VERSION ""

NS_ :

BS_:

BU_: VCU_LE CHUD_LE VKM_LE RCRM_LE VPM_LE EDI_LE V2V_LE TCP_LE CSM_LE UHP_Low_LE TouchPad_LE RSE_LE RSC_LE RSA_LE PDIM_LE OTIM_LE ICS_LE LVMPC_LE LVMNav_LE DVB_T_LE ONSTAR_LE HUD_LE IPC_LE RadioHead_LE CHM_LE Dummy_LE CGM_LE AMP_LE

BO_ 2158960640 ODIIndication_Centerstack_LE: 8 RadioHead_LE
 SG_ ODIIC_FUCID : 7|8@0+ (1,0) [0|255] ""  VCU_LE,IPC_LE,CHUD_LE,HUD_LE,RSC_LE,RSA_LE
 SG_ ODIIC_ODIInd9 : 23|1@0+ (1,0) [0|1] ""  VCU_LE,IPC_LE,CHUD_LE,HUD_LE,RSC_LE,RSA_LE
 SG_ ODIIC_ODIInd8 : 8|1@0+ (1,0) [0|1] ""  VCU_LE,IPC_LE,CHUD_LE,HUD_LE,RSC_LE,RSA_LE
 SG_ ODIIC_ODIInd7 : 9|1@0+ (1,0) [0|1] ""  VCU_LE,IPC_LE,CHUD_LE,HUD_LE,RSC_LE,RSA_LE
 SG_ ODIIC_ODIInd6 : 10|1@0+ (1,0) [0|1] ""  VCU_LE,IPC_LE,CHUD_LE,HUD_LE,RSC_LE,RSA_LE
 SG_ ODIIC_ODIInd56 : 56|1@0+ (1,0) [0|1] ""  VCU_LE,IPC_LE,CHUD_LE,HUD_LE,RSC_LE,RSA_LE
 SG_ ODIIC_ODIInd55 : 57|1@0+ (1,0) [0|1] ""  VCU_LE,IPC_LE,CHUD_LE,HUD_LE,RSC_LE,RSA_LE
 SG_ ODIIC_ODIInd54 : 58|1@0+ (1,0) [0|1] ""  VCU_LE,IPC_LE,CHUD_LE,HUD_LE,RSC_LE,RSA_LE
 SG_ ODIIC_ODIInd53 : 59|1@0+ (1,0) [0|1] ""  VCU_LE,IPC_LE,CHUD_LE,HUD_LE,RSC_LE,RSA_LE
 SG_ ODIIC_ODIInd52 : 60|1@0+ (1,0) [0|1] ""  VCU_LE,IPC_LE,CHUD_LE,HUD_LE,RSC_LE,RSA_LE
 SG_ ODIIC_ODIInd51 : 61|1@0+ (1,0) [0|1] ""  VCU_LE,IPC_LE,CHUD_LE,HUD_LE,RSC_LE,RSA_LE
 SG_ ODIIC_ODIInd50 : 62|1@0+ (1,0) [0|1] ""  VCU_LE,IPC_LE,CHUD_LE,HUD_LE,RSC_LE,RSA_LE
 SG_ ODIIC_ODIInd5 : 11|1@0+ (1,0) [0|1] ""  VCU_LE,IPC_LE,CHUD_LE,HUD_LE,RSC_LE,RSA_LE
 SG_ ODIIC_ODIInd49 : 63|1@0+ (1,0) [0|1] ""  VCU_LE,IPC_LE,CHUD_LE,HUD_LE,RSC_LE,RSA_LE
 SG_ ODIIC_ODIInd48 : 48|1@0+ (1,0) [0|1] ""  VCU_LE,IPC_LE,CHUD_LE,HUD_LE,RSC_LE,RSA_LE
 SG_ ODIIC_ODIInd47 : 49|1@0+ (1,0) [0|1] ""  VCU_LE,IPC_LE,CHUD_LE,HUD_LE,RSC_LE,RSA_LE
 SG_ ODIIC_ODIInd46 : 50|1@0+ (1,0) [0|1] ""  VCU_LE,IPC_LE,CHUD_LE,HUD_LE,RSC_LE,RSA_LE
 SG_ ODIIC_ODIInd45 : 51|1@0+ (1,0) [0|1] ""  VCU_LE,IPC_LE,CHUD_LE,HUD_LE,RSC_LE,RSA_LE
 SG_ ODIIC_ODIInd44 : 52|1@0+ (1,0) [0|1] ""  VCU_LE,IPC_LE,CHUD_LE,HUD_LE,RSC_LE,RSA_LE
 SG_ ODIIC_ODIInd43 : 53|1@0+ (1,0) [0|1] ""  VCU_LE,IPC_LE,CHUD_LE,HUD_LE,RSC_LE,RSA_LE
 SG_ ODIIC_ODIInd42 : 54|1@0+ (1,0) [0|1] ""  VCU_LE,IPC_LE,CHUD_LE,HUD_LE,RSC_LE,RSA_LE
 SG_ ODIIC_ODIInd41 : 55|1@0+ (1,0) [0|1] ""  VCU_LE,IPC_LE,CHUD_LE,HUD_LE,RSC_LE,RSA_LE
 SG_ ODIIC_ODIInd40 : 40|1@0+ (1,0) [0|1] ""  VCU_LE,IPC_LE,CHUD_LE,HUD_LE,RSC_LE,RSA_LE
 SG_ ODIIC_ODIInd4 : 12|1@0+ (1,0) [0|1] ""  VCU_LE,IPC_LE,CHUD_LE,HUD_LE,RSC_LE,RSA_LE
 SG_ ODIIC_ODIInd39 : 41|1@0+ (1,0) [0|1] ""  VCU_LE,IPC_LE,CHUD_LE,HUD_LE,RSC_LE,RSA_LE
 SG_ ODIIC_ODIInd38 : 42|1@0+ (1,0) [0|1] ""  VCU_LE,IPC_LE,CHUD_LE,HUD_LE,RSC_LE,RSA_LE
 SG_ ODIIC_ODIInd37 : 43|1@0+ (1,0) [0|1] ""  VCU_LE,IPC_LE,CHUD_LE,HUD_LE,RSC_LE,RSA_LE
 SG_ ODIIC_ODIInd36 : 44|1@0+ (1,0) [0|1] ""  VCU_LE,IPC_LE,CHUD_LE,HUD_LE,RSC_LE,RSA_LE
 SG_ ODIIC_ODIInd35 : 45|1@0+ (1,0) [0|1] ""  VCU_LE,IPC_LE,CHUD_LE,HUD_LE,RSC_LE,RSA_LE
 SG_ ODIIC_ODIInd34 : 46|1@0+ (1,0) [0|1] ""  VCU_LE,IPC_LE,CHUD_LE,HUD_LE,RSC_LE,RSA_LE
 SG_ ODIIC_ODIInd33 : 47|1@0+ (1,0) [0|1] ""  VCU_LE,IPC_LE,CHUD_LE,HUD_LE,RSC_LE,RSA_LE
 SG_ ODIIC_ODIInd32 : 32|1@0+ (1,0) [0|1] ""  VCU_LE,IPC_LE,CHUD_LE,HUD_LE,RSC_LE,RSA_LE
 SG_ ODIIC_ODIInd31 : 33|1@0+ (1,0) [0|1] ""  VCU_LE,IPC_LE,CHUD_LE,HUD_LE,RSC_LE,RSA_LE
 SG_ ODIIC_ODIInd30 : 34|1@0+ (1,0) [0|1] ""  VCU_LE,IPC_LE,CHUD_LE,HUD_LE,RSC_LE,RSA_LE
 SG_ ODIIC_ODIInd3 : 13|1@0+ (1,0) [0|1] ""  VCU_LE,IPC_LE,CHUD_LE,HUD_LE,RSC_LE,RSA_LE
 SG_ ODIIC_ODIInd29 : 35|1@0+ (1,0) [0|1] ""  VCU_LE,IPC_LE,CHUD_LE,HUD_LE,RSC_LE,RSA_LE
 SG_ ODIIC_ODIInd28 : 36|1@0+ (1,0) [0|1] ""  VCU_LE,IPC_LE,CHUD_LE,HUD_LE,RSC_LE,RSA_LE
 SG_ ODIIC_ODIInd27 : 37|1@0+ (1,0) [0|1] ""  VCU_LE,IPC_LE,CHUD_LE,HUD_LE,RSC_LE,RSA_LE
 SG_ ODIIC_ODIInd26 : 38|1@0+ (1,0) [0|1] ""  VCU_LE,IPC_LE,CHUD_LE,HUD_LE,RSC_LE,RSA_LE
 SG_ ODIIC_ODIInd25 : 39|1@0+ (1,0) [0|1] ""  VCU_LE,IPC_LE,CHUD_LE,HUD_LE,RSC_LE,RSA_LE
 SG_ ODIIC_ODIInd24 : 24|1@0+ (1,0) [0|1] ""  VCU_LE,IPC_LE,CHUD_LE,HUD_LE,RSC_LE,RSA_LE
 SG_ ODIIC_ODIInd23 : 25|1@0+ (1,0) [0|1] ""  VCU_LE,IPC_LE,CHUD_LE,HUD_LE,RSC_LE,RSA_LE
 SG_ ODIIC_ODIInd22 : 26|1@0+ (1,0) [0|1] ""  VCU_LE,IPC_LE,CHUD_LE,HUD_LE,RSC_LE,RSA_LE
 SG_ ODIIC_ODIInd21 : 27|1@0+ (1,0) [0|1] ""  VCU_LE,IPC_LE,CHUD_LE,HUD_LE,RSC_LE,RSA_LE
 SG_ ODIIC_ODIInd20 : 28|1@0+ (1,0) [0|1] ""  VCU_LE,IPC_LE,CHUD_LE,HUD_LE,RSC_LE,RSA_LE
 SG_ ODIIC_ODIInd2 : 14|1@0+ (1,0) [0|1] ""  VCU_LE,IPC_LE,CHUD_LE,HUD_LE,RSC_LE,RSA_LE
 SG_ ODIIC_ODIInd19 : 29|1@0+ (1,0) [0|1] ""  VCU_LE,IPC_LE,CHUD_LE,HUD_LE,RSC_LE,RSA_LE
 SG_ ODIIC_ODIInd18 : 30|1@0+ (1,0) [0|1] ""  VCU_LE,IPC_LE,CHUD_LE,HUD_LE,RSC_LE,RSA_LE
 SG_ ODIIC_ODIInd17 : 31|1@0+ (1,0) [0|1] ""  VCU_LE,IPC_LE,CHUD_LE,HUD_LE,RSC_LE,RSA_LE
 SG_ ODIIC_ODIInd16 : 16|1@0+ (1,0) [0|1] ""  VCU_LE,IPC_LE,CHUD_LE,HUD_LE,RSC_LE,RSA_LE
 SG_ ODIIC_ODIInd15 : 17|1@0+ (1,0) [0|1] ""  VCU_LE,IPC_LE,CHUD_LE,HUD_LE,RSC_LE,RSA_LE
 SG_ ODIIC_ODIInd14 : 18|1@0+ (1,0) [0|1] ""  VCU_LE,IPC_LE,CHUD_LE,HUD_LE,RSC_LE,RSA_LE
 SG_ ODIIC_ODIInd13 : 19|1@0+ (1,0) [0|1] ""  VCU_LE,IPC_LE,CHUD_LE,HUD_LE,RSC_LE,RSA_LE
 SG_ ODIIC_ODIInd12 : 20|1@0+ (1,0) [0|1] ""  VCU_LE,IPC_LE,CHUD_LE,HUD_LE,RSC_LE,RSA_LE
 SG_ ODIIC_ODIInd11 : 21|1@0+ (1,0) [0|1] ""  VCU_LE,IPC_LE,CHUD_LE,HUD_LE,RSC_LE,RSA_LE
 SG_ ODIIC_ODIInd10 : 22|1@0+ (1,0) [0|1] ""  VCU_LE,IPC_LE,CHUD_LE,HUD_LE,RSC_LE,RSA_LE
 SG_ ODIIC_ODIInd1 : 15|1@0+ (1,0) [0|1] ""  VCU_LE,IPC_LE,CHUD_LE,HUD_LE,RSC_LE,RSA_LE

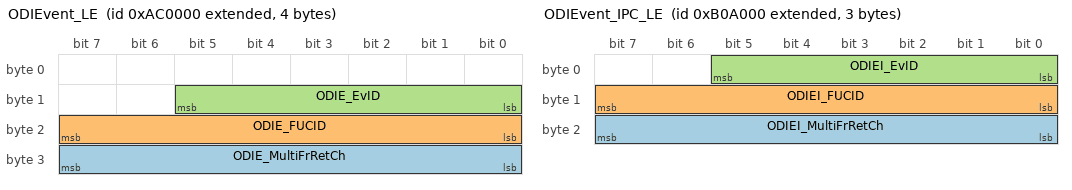
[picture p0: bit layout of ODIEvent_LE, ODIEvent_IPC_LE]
BO_ 2158755840 ODIEvent_LE: 4 ONSTAR_LE
 SG_ ODIE_MultiFrRetCh : 31|8@0+ (1,0) [0|255] ""  CSM_LE,OTIM_LE,RSC_LE,RSA_LE,RadioHead_LE,VCU_LE,IPC_LE,CHUD_LE,HUD_LE
 SG_ ODIE_FUCID : 23|8@0+ (1,0) [0|255] ""  CSM_LE,OTIM_LE,RSC_LE,RSA_LE,RadioHead_LE,VCU_LE,IPC_LE,CHUD_LE,HUD_LE
 SG_ ODIE_EvID : 13|6@0+ (1,0) [0|63] ""  CSM_LE,OTIM_LE,RSC_LE,RSA_LE,RadioHead_LE,VCU_LE,IPC_LE,CHUD_LE,HUD_LE

BO_ 2159058944 ODIEvent_IPC_LE: 3 IPC_LE
 SG_ ODIEI_MultiFrRetCh : 23|8@0+ (1,0) [0|255] ""  CSM_LE,VCU_LE,RadioHead_LE,CHUD_LE,HUD_LE
 SG_ ODIEI_FUCID : 15|8@0+ (1,0) [0|255] ""  CSM_LE,VCU_LE,RadioHead_LE,CHUD_LE,HUD_LE
 SG_ ODIEI_EvID : 5|6@0+ (1,0) [0|63] ""  CSM_LE,VCU_LE,RadioHead_LE,CHUD_LE,HUD_LE

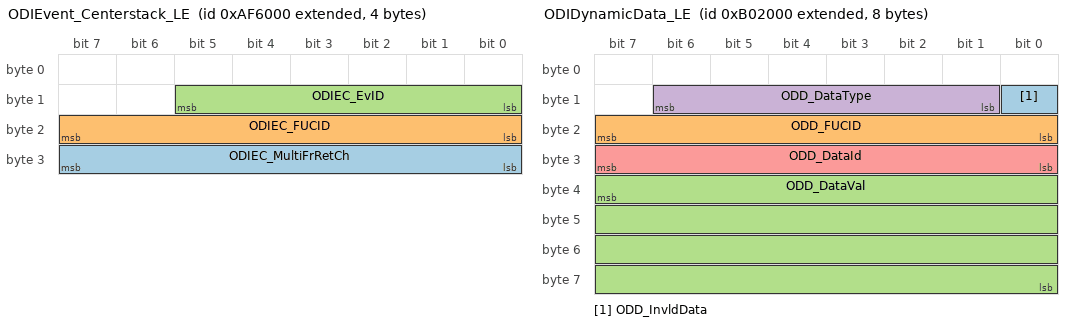
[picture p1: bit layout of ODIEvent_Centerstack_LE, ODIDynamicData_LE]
BO_ 2158977024 ODIEvent_Centerstack_LE: 4 RadioHead_LE
 SG_ ODIEC_MultiFrRetCh : 31|8@0+ (1,0) [0|255] ""  VCU_LE,IPC_LE,CHUD_LE,HUD_LE,RSC_LE,RSA_LE
 SG_ ODIEC_FUCID : 23|8@0+ (1,0) [0|255] ""  VCU_LE,IPC_LE,CHUD_LE,HUD_LE,RSC_LE,RSA_LE
 SG_ ODIEC_EvID : 13|6@0+ (1,0) [0|63] ""  VCU_LE,IPC_LE,CHUD_LE,HUD_LE,RSC_LE,RSA_LE

BO_ 2158936064 ODIEnumDynamicData_LE: 8 CGM_LE
 SG_ ODIEDD_Data18Value : 50|3@0+ (1,0) [0|7] ""  CSM_LE,TCP_LE,ONSTAR_LE,OTIM_LE,IPC_LE,CHUD_LE,HUD_LE,VCU_LE,RadioHead_LE
 SG_ ODIEDD_Data17Value : 53|3@0+ (1,0) [0|7] ""  CSM_LE,TCP_LE,ONSTAR_LE,OTIM_LE,IPC_LE,CHUD_LE,HUD_LE,VCU_LE,RadioHead_LE
 SG_ ODIEDD_Data16Value : 40|3@0+ (1,0) [0|7] ""  CSM_LE,TCP_LE,ONSTAR_LE,OTIM_LE,IPC_LE,CHUD_LE,HUD_LE,VCU_LE,RadioHead_LE
 SG_ ODIEDD_Data15Value : 43|3@0+ (1,0) [0|7] ""  CSM_LE,TCP_LE,ONSTAR_LE,OTIM_LE,IPC_LE,CHUD_LE,HUD_LE,VCU_LE,RadioHead_LE
 SG_ ODIEDD_Data14Value : 46|3@0+ (1,0) [0|7] ""  CSM_LE,TCP_LE,ONSTAR_LE,OTIM_LE,IPC_LE,CHUD_LE,HUD_LE,VCU_LE,RadioHead_LE
 SG_ ODIEDD_Data13Value : 33|3@0+ (1,0) [0|7] ""  CSM_LE,TCP_LE,ONSTAR_LE,OTIM_LE,IPC_LE,CHUD_LE,HUD_LE,VCU_LE,RadioHead_LE
 SG_ ODIEDD_Data12Value : 36|3@0+ (1,0) [0|7] ""  CSM_LE,TCP_LE,ONSTAR_LE,OTIM_LE,IPC_LE,CHUD_LE,HUD_LE,VCU_LE,RadioHead_LE
 SG_ ODIEDD_Data11Value : 39|3@0+ (1,0) [0|7] ""  CSM_LE,TCP_LE,ONSTAR_LE,OTIM_LE,IPC_LE,CHUD_LE,HUD_LE,VCU_LE,RadioHead_LE
 SG_ ODIEDD_Data10Value : 26|3@0+ (1,0) [0|7] ""  CSM_LE,TCP_LE,ONSTAR_LE,OTIM_LE,IPC_LE,CHUD_LE,HUD_LE,VCU_LE,RadioHead_LE
 SG_ ODIEDD_Data9Value : 29|3@0+ (1,0) [0|7] ""  CSM_LE,TCP_LE,ONSTAR_LE,OTIM_LE,IPC_LE,CHUD_LE,HUD_LE,VCU_LE,RadioHead_LE
 SG_ ODIEDD_Data8Value : 16|3@0+ (1,0) [0|7] ""  CSM_LE,TCP_LE,ONSTAR_LE,OTIM_LE,IPC_LE,CHUD_LE,HUD_LE,VCU_LE,RadioHead_LE
 SG_ ODIEDD_Data7Value : 19|3@0+ (1,0) [0|7] ""  CSM_LE,TCP_LE,ONSTAR_LE,OTIM_LE,IPC_LE,CHUD_LE,HUD_LE,VCU_LE,RadioHead_LE
 SG_ ODIEDD_Data6Value : 22|3@0+ (1,0) [0|7] ""  CSM_LE,TCP_LE,ONSTAR_LE,OTIM_LE,IPC_LE,CHUD_LE,HUD_LE,VCU_LE,RadioHead_LE
 SG_ ODIEDD_Data5Value : 9|3@0+ (1,0) [0|7] ""  CSM_LE,TCP_LE,ONSTAR_LE,OTIM_LE,IPC_LE,CHUD_LE,HUD_LE,VCU_LE,RadioHead_LE
 SG_ ODIEDD_Data4Value : 12|3@0+ (1,0) [0|7] ""  CSM_LE,TCP_LE,ONSTAR_LE,OTIM_LE,IPC_LE,CHUD_LE,HUD_LE,VCU_LE,RadioHead_LE
 SG_ ODIEDD_Data3Value : 15|3@0+ (1,0) [0|7] ""  CSM_LE,TCP_LE,ONSTAR_LE,OTIM_LE,IPC_LE,CHUD_LE,HUD_LE,VCU_LE,RadioHead_LE
 SG_ ODIEDD_Data2Value : 2|3@0+ (1,0) [0|7] ""  CSM_LE,TCP_LE,ONSTAR_LE,OTIM_LE,IPC_LE,CHUD_LE,HUD_LE,VCU_LE,RadioHead_LE
 SG_ ODIEDD_Data1Value : 5|3@0+ (1,0) [0|7] ""  CSM_LE,TCP_LE,ONSTAR_LE,OTIM_LE,IPC_LE,CHUD_LE,HUD_LE,VCU_LE,RadioHead_LE
 SG_ ODIEDD_FUCID : 63|8@0+ (1,0) [0|255] ""  CSM_LE,TCP_LE,ONSTAR_LE,OTIM_LE,IPC_LE,CHUD_LE,HUD_LE,VCU_LE,RadioHead_LE

BO_ 2159001600 ODIEnumDynamicData_IPC_LE: 8 IPC_LE
 SG_ ODIEDDIPC_FUCID : 63|8@0+ (1,0) [0|255] ""  CSM_LE,TCP_LE,ONSTAR_LE,CHUD_LE,HUD_LE,VCU_LE,RadioHead_LE
 SG_ ODIEDDIPC_Data18Value : 50|3@0+ (1,0) [0|7] ""  CSM_LE,TCP_LE,ONSTAR_LE,CHUD_LE,HUD_LE,VCU_LE,RadioHead_LE
 SG_ ODIEDDIPC_Data17Value : 53|3@0+ (1,0) [0|7] ""  CSM_LE,TCP_LE,ONSTAR_LE,CHUD_LE,HUD_LE,VCU_LE,RadioHead_LE
 SG_ ODIEDDIPC_Data16Value : 40|3@0+ (1,0) [0|7] ""  CSM_LE,TCP_LE,ONSTAR_LE,CHUD_LE,HUD_LE,VCU_LE,RadioHead_LE
 SG_ ODIEDDIPC_Data15Value : 43|3@0+ (1,0) [0|7] ""  CSM_LE,TCP_LE,ONSTAR_LE,CHUD_LE,HUD_LE,VCU_LE,RadioHead_LE
 SG_ ODIEDDIPC_Data14Value : 46|3@0+ (1,0) [0|7] ""  CSM_LE,TCP_LE,ONSTAR_LE,CHUD_LE,HUD_LE,VCU_LE,RadioHead_LE
 SG_ ODIEDDIPC_Data13Value : 33|3@0+ (1,0) [0|7] ""  CSM_LE,TCP_LE,ONSTAR_LE,CHUD_LE,HUD_LE,VCU_LE,RadioHead_LE
 SG_ ODIEDDIPC_Data12Value : 36|3@0+ (1,0) [0|7] ""  CSM_LE,TCP_LE,ONSTAR_LE,CHUD_LE,HUD_LE,VCU_LE,RadioHead_LE
 SG_ ODIEDDIPC_Data11Value : 39|3@0+ (1,0) [0|7] ""  CSM_LE,TCP_LE,ONSTAR_LE,CHUD_LE,HUD_LE,VCU_LE,RadioHead_LE
 SG_ ODIEDDIPC_Data10Value : 26|3@0+ (1,0) [0|7] ""  CSM_LE,TCP_LE,ONSTAR_LE,CHUD_LE,HUD_LE,VCU_LE,RadioHead_LE
 SG_ ODIEDDIPC_Data9Value : 29|3@0+ (1,0) [0|7] ""  CSM_LE,TCP_LE,ONSTAR_LE,CHUD_LE,HUD_LE,VCU_LE,RadioHead_LE
 SG_ ODIEDDIPC_Data8Value : 16|3@0+ (1,0) [0|7] ""  CSM_LE,TCP_LE,ONSTAR_LE,CHUD_LE,HUD_LE,VCU_LE,RadioHead_LE
 SG_ ODIEDDIPC_Data7Value : 19|3@0+ (1,0) [0|7] ""  CSM_LE,TCP_LE,ONSTAR_LE,CHUD_LE,HUD_LE,VCU_LE,RadioHead_LE
 SG_ ODIEDDIPC_Data6Value : 22|3@0+ (1,0) [0|7] ""  CSM_LE,TCP_LE,ONSTAR_LE,CHUD_LE,HUD_LE,VCU_LE,RadioHead_LE
 SG_ ODIEDDIPC_Data5Value : 9|3@0+ (1,0) [0|7] ""  CSM_LE,TCP_LE,ONSTAR_LE,CHUD_LE,HUD_LE,VCU_LE,RadioHead_LE
 SG_ ODIEDDIPC_Data4Value : 12|3@0+ (1,0) [0|7] ""  CSM_LE,TCP_LE,ONSTAR_LE,CHUD_LE,HUD_LE,VCU_LE,RadioHead_LE
 SG_ ODIEDDIPC_Data3Value : 15|3@0+ (1,0) [0|7] ""  CSM_LE,TCP_LE,ONSTAR_LE,CHUD_LE,HUD_LE,VCU_LE,RadioHead_LE
 SG_ ODIEDDIPC_Data2Value : 2|3@0+ (1,0) [0|7] ""  CSM_LE,TCP_LE,ONSTAR_LE,CHUD_LE,HUD_LE,VCU_LE,RadioHead_LE
 SG_ ODIEDDIPC_Data1Value : 5|3@0+ (1,0) [0|7] ""  CSM_LE,TCP_LE,ONSTAR_LE,CHUD_LE,HUD_LE,VCU_LE,RadioHead_LE

BO_ 2158993408 ODIEnumDynamicData_CntrStack_LE: 8 RadioHead_LE
 SG_ ODIEDDCS_FUCID : 63|8@0+ (1,0) [0|255] ""  VCU_LE,IPC_LE,CHUD_LE,HUD_LE
 SG_ ODIEDDCS_Data9Value : 29|3@0+ (1,0) [0|7] ""  VCU_LE,IPC_LE,CHUD_LE,HUD_LE
 SG_ ODIEDDCS_Data8Value : 16|3@0+ (1,0) [0|7] ""  VCU_LE,IPC_LE,CHUD_LE,HUD_LE
 SG_ ODIEDDCS_Data7Value : 19|3@0+ (1,0) [0|7] ""  VCU_LE,IPC_LE,CHUD_LE,HUD_LE
 SG_ ODIEDDCS_Data6Value : 22|3@0+ (1,0) [0|7] ""  VCU_LE,IPC_LE,CHUD_LE,HUD_LE
 SG_ ODIEDDCS_Data5Value : 9|3@0+ (1,0) [0|7] ""  VCU_LE,IPC_LE,CHUD_LE,HUD_LE
 SG_ ODIEDDCS_Data4Value : 12|3@0+ (1,0) [0|7] ""  VCU_LE,IPC_LE,CHUD_LE,HUD_LE
 SG_ ODIEDDCS_Data3Value : 15|3@0+ (1,0) [0|7] ""  VCU_LE,IPC_LE,CHUD_LE,HUD_LE
 SG_ ODIEDDCS_Data2Value : 2|3@0+ (1,0) [0|7] ""  VCU_LE,IPC_LE,CHUD_LE,HUD_LE
 SG_ ODIEDDCS_Data18Value : 50|3@0+ (1,0) [0|7] ""  VCU_LE,IPC_LE,CHUD_LE,HUD_LE
 SG_ ODIEDDCS_Data17Value : 53|3@0+ (1,0) [0|7] ""  VCU_LE,IPC_LE,CHUD_LE,HUD_LE
 SG_ ODIEDDCS_Data16Value : 40|3@0+ (1,0) [0|7] ""  VCU_LE,IPC_LE,CHUD_LE,HUD_LE
 SG_ ODIEDDCS_Data15Value : 43|3@0+ (1,0) [0|7] ""  VCU_LE,IPC_LE,CHUD_LE,HUD_LE
 SG_ ODIEDDCS_Data14Value : 46|3@0+ (1,0) [0|7] ""  VCU_LE,IPC_LE,CHUD_LE,HUD_LE
 SG_ ODIEDDCS_Data13Value : 33|3@0+ (1,0) [0|7] ""  VCU_LE,IPC_LE,CHUD_LE,HUD_LE
 SG_ ODIEDDCS_Data12Value : 36|3@0+ (1,0) [0|7] ""  VCU_LE,IPC_LE,CHUD_LE,HUD_LE
 SG_ ODIEDDCS_Data11Value : 39|3@0+ (1,0) [0|7] ""  VCU_LE,IPC_LE,CHUD_LE,HUD_LE
 SG_ ODIEDDCS_Data10Value : 26|3@0+ (1,0) [0|7] ""  VCU_LE,IPC_LE,CHUD_LE,HUD_LE
 SG_ ODIEDDCS_Data1Value : 5|3@0+ (1,0) [0|7] ""  VCU_LE,IPC_LE,CHUD_LE,HUD_LE

BO_ 2159026176 ODIDynamicData_LE: 8 ONSTAR_LE
 SG_ ODD_InvldData : 8|1@0+ (1,0) [0|1] ""  CSM_LE,OTIM_LE,RSC_LE,RSA_LE,IPC_LE,CHUD_LE,HUD_LE,VCU_LE,RadioHead_LE
 SG_ ODD_FUCID : 23|8@0+ (1,0) [0|255] ""  CSM_LE,OTIM_LE,RSC_LE,RSA_LE,IPC_LE,CHUD_LE,HUD_LE,VCU_LE,RadioHead_LE
 SG_ ODD_DataVal : 39|32@0+ (1,0) [0|4294967295] ""  CSM_LE,OTIM_LE,RSC_LE,RSA_LE,IPC_LE,CHUD_LE,HUD_LE,VCU_LE,RadioHead_LE
 SG_ ODD_DataType : 14|6@0+ (1,0) [0|63] ""  CSM_LE,OTIM_LE,RSC_LE,RSA_LE,IPC_LE,CHUD_LE,HUD_LE,VCU_LE,RadioHead_LE
 SG_ ODD_DataId : 31|8@0+ (1,0) [0|255] ""  CSM_LE,OTIM_LE,RSC_LE,RSA_LE,IPC_LE,CHUD_LE,HUD_LE,VCU_LE,RadioHead_LE

BO_ 2159116288 ODI_TEL_2_AuxIP_LE: 8 ONSTAR_LE
 SG_ ODI_TEL2AxIP : 7|64@0+ (1,0) [0|1.84467440737096E+019] ""  CHUD_LE,HUD_LE

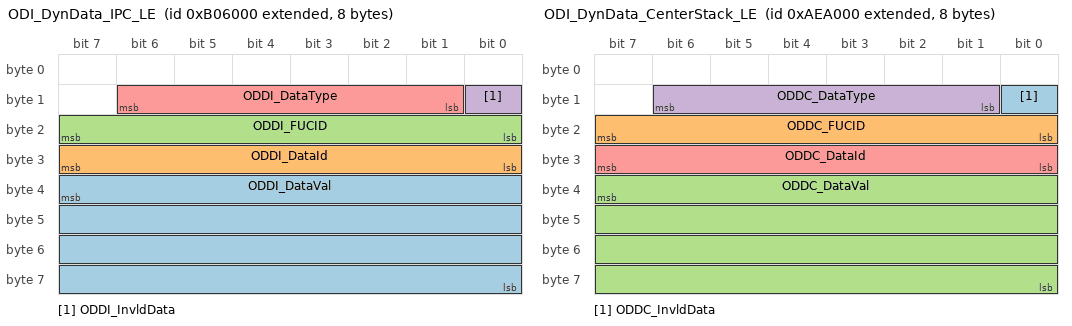
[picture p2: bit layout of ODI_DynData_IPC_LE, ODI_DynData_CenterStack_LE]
BO_ 2159042560 ODI_DynData_IPC_LE: 8 IPC_LE
 SG_ ODDI_DataVal : 39|32@0+ (1,0) [0|4294967295] ""  CSM_LE,VCU_LE,RadioHead_LE,CHUD_LE,HUD_LE
 SG_ ODDI_DataId : 31|8@0+ (1,0) [0|255] ""  CSM_LE,VCU_LE,RadioHead_LE,CHUD_LE,HUD_LE
 SG_ ODDI_FUCID : 23|8@0+ (1,0) [0|255] ""  CSM_LE,VCU_LE,RadioHead_LE,CHUD_LE,HUD_LE
 SG_ ODDI_InvldData : 8|1@0+ (1,0) [0|1] ""  CSM_LE,VCU_LE,RadioHead_LE,CHUD_LE,HUD_LE
 SG_ ODDI_DataType : 14|6@0+ (1,0) [0|63] ""  CSM_LE,VCU_LE,RadioHead_LE,CHUD_LE,HUD_LE

BO_ 2158927872 ODI_DynData_CenterStack_LE: 8 RadioHead_LE
 SG_ ODDC_InvldData : 8|1@0+ (1,0) [0|1] ""  ONSTAR_LE,RSC_LE,RSA_LE,CHUD_LE,HUD_LE,VCU_LE,IPC_LE,TCP_LE
 SG_ ODDC_FUCID : 23|8@0+ (1,0) [0|255] ""  ONSTAR_LE,RSC_LE,RSA_LE,CHUD_LE,HUD_LE,VCU_LE,IPC_LE,TCP_LE
 SG_ ODDC_DataVal : 39|32@0+ (1,0) [0|4294967295] ""  ONSTAR_LE,RSC_LE,RSA_LE,CHUD_LE,HUD_LE,VCU_LE,IPC_LE,TCP_LE
 SG_ ODDC_DataType : 14|6@0+ (1,0) [0|63] ""  ONSTAR_LE,RSC_LE,RSA_LE,CHUD_LE,HUD_LE,VCU_LE,IPC_LE,TCP_LE
 SG_ ODDC_DataId : 31|8@0+ (1,0) [0|255] ""  ONSTAR_LE,RSC_LE,RSA_LE,CHUD_LE,HUD_LE,VCU_LE,IPC_LE,TCP_LE

BO_ 2159099904 ODI_DAB_2_AuxIP_LE: 8 RadioHead_LE
 SG_ ODI_DAB2AxIP : 7|64@0+ (1,0) [0|1.84467440737096E+019] ""  CHUD_LE,HUD_LE

BO_ 2159181824 ODI_CenterStack_2_AuxIP_LE: 8 RadioHead_LE
 SG_ ODI_CntrStck2AxIP : 7|64@0+ (1,0) [0|1.84467440737096E+019] ""  CHUD_LE,HUD_LE

BO_ 1622 USDT_Resp_From_RSA_RSE_LE: 8 RSA_LE
 SG_ DgnInf : 7|64@0+ (1,0) [0|1.84467440737096E+019] ""  CGM_LE,CSM_LE,TCP_LE,ONSTAR_LE

BO_ 1590 VNMF_LE_636_RSA_RSE: 8 RSA_LE
 SG_ VectraSpcNWMgtD : 7|64@0+ (1,0) [0|1.84467440737096E+019] ""  RCRM_LE,V2V_LE,TCP_LE,UHP_Low_LE,LVMNav_LE,ONSTAR_LE,VKM_LE,RSC_LE,PDIM_LE,OTIM_LE,CHUD_LE,LVMPC_LE,IPC_LE,ICS_LE,VPM_LE,HUD_LE,TouchPad_LE,DVB_T_LE,VCU_LE,CSM_LE,RadioHead_LE,CHM_LE,AMP_LE,CGM_LE

BO_ 1366 UUDT_Resp_From_RSA_RSE_LE: 8 RSA_LE
 SG_ DgnInf_LS556 : 7|64@0+ (1,0) [0|1.84467440737096E+019] ""  CGM_LE,CSM_LE,TCP_LE,ONSTAR_LE

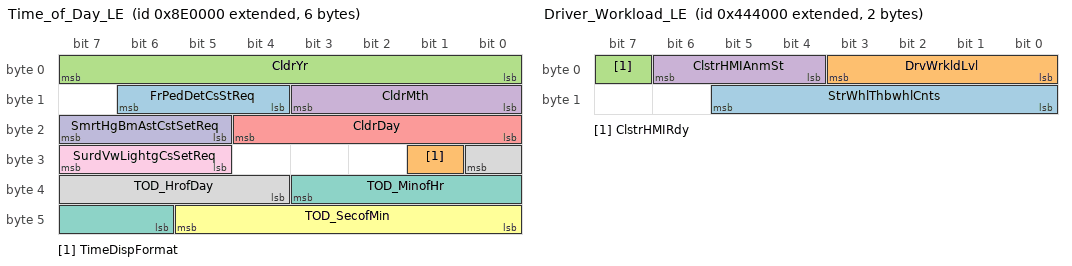
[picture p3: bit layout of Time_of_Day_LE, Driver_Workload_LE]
BO_ 2156789760 Time_of_Day_LE: 6 RadioHead_LE
 SG_ FrPedDetCsStReq : 14|3@0+ (1,0) [0|7] ""  CGM_LE,Dummy_LE
 SG_ TimeDispFormat : 25|1@0+ (1,0) [0|1] ""  RSE_LE,EDI_LE,VPM_LE,CGM_LE,CHUD_LE,HUD_LE,LVMPC_LE,LVMNav_LE,VCU_LE,IPC_LE
 SG_ CldrYr : 7|8@0+ (1,2000) [2000|2255] "year"  RSE_LE,EDI_LE,VPM_LE,CGM_LE,CHUD_LE,HUD_LE,UHP_Low_LE,LVMPC_LE,LVMNav_LE,VCU_LE,IPC_LE
 SG_ CldrMth : 11|4@0+ (1,0) [0|15] ""  RSE_LE,EDI_LE,VPM_LE,CGM_LE,CHUD_LE,HUD_LE,UHP_Low_LE,LVMPC_LE,LVMNav_LE,VCU_LE,IPC_LE
 SG_ CldrDay : 20|5@0+ (1,0) [0|31] "days"  RSE_LE,EDI_LE,VPM_LE,CGM_LE,CHUD_LE,HUD_LE,UHP_Low_LE,LVMPC_LE,LVMNav_LE,VCU_LE,IPC_LE
 SG_ TOD_SecofMin : 45|6@0+ (1,0) [0|63] "s"  RSE_LE,EDI_LE,VPM_LE,CGM_LE,CHUD_LE,HUD_LE,UHP_Low_LE,LVMPC_LE,LVMNav_LE,VCU_LE,IPC_LE
 SG_ TOD_MinofHr : 35|6@0+ (1,0) [0|63] "min"  RSE_LE,EDI_LE,VPM_LE,CGM_LE,CHUD_LE,HUD_LE,UHP_Low_LE,LVMPC_LE,LVMNav_LE,VCU_LE,IPC_LE
 SG_ TOD_HrofDay : 24|5@0+ (1,0) [0|31] "hr"  RSE_LE,EDI_LE,VPM_LE,CGM_LE,CHUD_LE,HUD_LE,UHP_Low_LE,LVMPC_LE,LVMNav_LE,VCU_LE,IPC_LE
 SG_ SurdVwLightgCsSetReq : 31|3@0+ (1,0) [0|7] ""  CGM_LE,VPM_LE
 SG_ SmrtHgBmAstCstSetReq : 23|3@0+ (1,0) [0|7] ""  CGM_LE

BO_ 2151956480 Driver_Workload_LE: 2 IPC_LE
 SG_ StrWhlThbwhlCnts : 13|6@0- (1,0) [-32|31] "counts"  RadioHead_LE,CSM_LE
 SG_ DrvWrkldLvl : 3|4@0+ (1,0) [0|15] ""  VCU_LE,CSM_LE,RadioHead_LE,CHUD_LE,HUD_LE
 SG_ ClstrHMIRdy : 7|1@0+ (1,0) [0|1] ""  CSM_LE
 SG_ ClstrHMIAnmSt : 6|3@0+ (1,0) [0|7] ""  CSM_LE

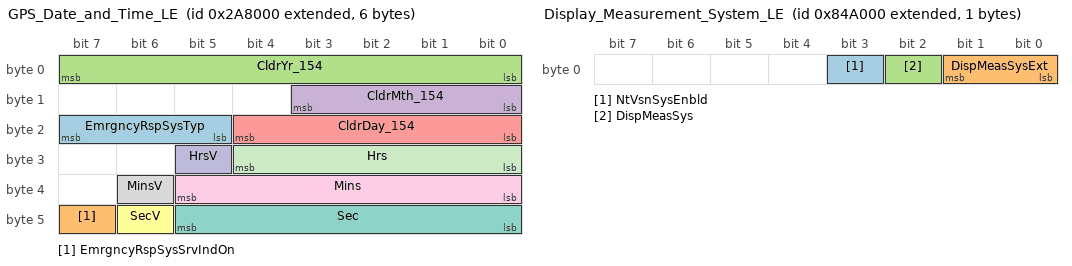
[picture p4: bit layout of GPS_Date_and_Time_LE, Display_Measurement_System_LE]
BO_ 2150268928 GPS_Date_and_Time_LE: 6 ONSTAR_LE
 SG_ EmrgncyRspSysTyp : 23|3@0+ (1,0) [0|7] ""  CGM_LE,VCU_LE,IPC_LE
 SG_ EmrgncyRspSysSrvIndOn : 47|1@0+ (1,0) [0|1] ""  CGM_LE,VCU_LE,IPC_LE
 SG_ CldrYr_154 : 7|8@0+ (1,2000) [2000|2255] "year"  V2V_LE,CGM_LE,CHUD_LE,HUD_LE,IPC_LE,VCU_LE,CSM_LE,RadioHead_LE,VPM_LE
 SG_ CldrMth_154 : 11|4@0+ (1,0) [0|15] ""  V2V_LE,CGM_LE,CHUD_LE,HUD_LE,IPC_LE,VCU_LE,CSM_LE,RadioHead_LE,VPM_LE
 SG_ CldrDay_154 : 20|5@0+ (1,0) [0|31] "days"  V2V_LE,CGM_LE,CHUD_LE,HUD_LE,IPC_LE,VCU_LE,CSM_LE,RadioHead_LE,VPM_LE
 SG_ SecV : 46|1@0+ (1,0) [0|1] ""  V2V_LE,CGM_LE,VCU_LE,CSM_LE,RadioHead_LE,VPM_LE
 SG_ Sec : 45|6@0+ (1,0) [0|63] "s"  V2V_LE,CGM_LE,VCU_LE,CSM_LE,RadioHead_LE,VPM_LE
 SG_ MinsV : 38|1@0+ (1,0) [0|1] ""  V2V_LE,CGM_LE,VCU_LE,CSM_LE,RadioHead_LE,VPM_LE
 SG_ Mins : 37|6@0+ (1,0) [0|63] "min"  V2V_LE,CGM_LE,VCU_LE,CSM_LE,RadioHead_LE,VPM_LE
 SG_ HrsV : 29|1@0+ (1,0) [0|1] ""  V2V_LE,CGM_LE,VCU_LE,CSM_LE,RadioHead_LE,VPM_LE
 SG_ Hrs : 28|5@0+ (1,0) [0|31] "h"  V2V_LE,CGM_LE,VCU_LE,CSM_LE,RadioHead_LE,VPM_LE

BO_ 2156175360 Display_Measurement_System_LE: 1 IPC_LE
 SG_ NtVsnSysEnbld : 3|1@0+ (1,0) [0|1] ""  CGM_LE
 SG_ DispMeasSysExt : 1|2@0+ (1,0) [0|3] ""  EDI_LE,TCP_LE,V2V_LE,CGM_LE,CHUD_LE,HUD_LE,ONSTAR_LE,RSC_LE,RSA_LE,VCU_LE,CSM_LE,RadioHead_LE,LVMPC_LE,LVMNav_LE
 SG_ DispMeasSys : 2|1@0+ (1,0) [0|1] ""  EDI_LE,V2V_LE,CGM_LE,LVMPC_LE,LVMNav_LE

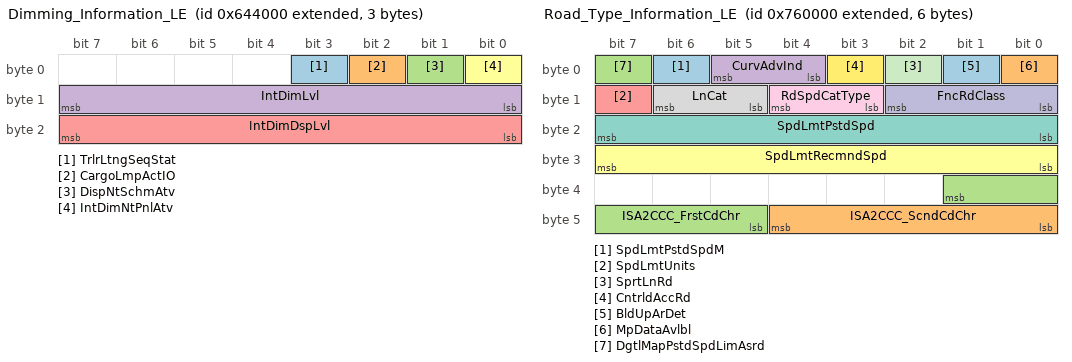
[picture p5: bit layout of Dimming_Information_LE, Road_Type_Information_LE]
BO_ 2154053632 Dimming_Information_LE: 3 CGM_LE
 SG_ TrlrLtngSeqStat : 3|1@0+ (1,0) [0|1] ""  TCP_LE,CSM_LE
 SG_ CargoLmpActIO : 2|1@0+ (1,0) [0|1] ""  VCU_LE,IPC_LE
 SG_ DispNtSchmAtv : 1|1@0+ (1,0) [0|1] ""  RSE_LE,TouchPad_LE,TCP_LE,ONSTAR_LE,ICS_LE,VCU_LE,CHUD_LE,EDI_LE,CSM_LE,RSC_LE,RSA_LE,HUD_LE,IPC_LE,RadioHead_LE
 SG_ IntDimLvl : 15|8@0+ (0.392157,0) [0|100.000035] "%"  RSE_LE,VPM_LE,TouchPad_LE,TCP_LE,ONSTAR_LE,ICS_LE,VCU_LE,CHUD_LE,EDI_LE,CSM_LE,RSC_LE,RSA_LE,HUD_LE,IPC_LE,RadioHead_LE
 SG_ IntDimDspLvl : 23|8@0+ (0.392157,0) [0|100.000035] "%"  RSE_LE,VPM_LE,TouchPad_LE,ICS_LE,VCU_LE,CHUD_LE,EDI_LE,CSM_LE,RSC_LE,RSA_LE,HUD_LE,IPC_LE,RadioHead_LE
 SG_ IntDimNtPnlAtv : 0|1@0+ (1,0) [0|1] ""  TCP_LE,ONSTAR_LE,ICS_LE,VCU_LE,CHUD_LE,EDI_LE,CSM_LE,RSC_LE,RSA_LE,HUD_LE,IPC_LE,RadioHead_LE

BO_ 2155216896 Road_Type_Information_LE: 6 RadioHead_LE
 SG_ SpdLmtPstdSpdM : 6|1@0+ (1,0) [0|1] ""  CGM_LE,VCU_LE,IPC_LE,CHUD_LE,HUD_LE
 SG_ ISA2CCC_ScndCdChr : 44|5@0+ (1,0) [0|31] ""  CGM_LE,LVMPC_LE
 SG_ ISA2CCC_FrstCdChr : 33|5@0+ (1,0) [0|31] ""  CGM_LE,LVMPC_LE
 SG_ CurvAdvInd : 5|2@0+ (1,0) [0|3] ""  CGM_LE,CHUD_LE,HUD_LE,VCU_LE,IPC_LE
 SG_ SpdLmtUnits : 15|1@0+ (1,0) [0|1] ""  CGM_LE,VCU_LE,IPC_LE,CHUD_LE,HUD_LE
 SG_ SpdLmtRecmndSpd : 31|8@0+ (1,0) [0|255] ""  CGM_LE,VCU_LE,IPC_LE,CHUD_LE,HUD_LE
 SG_ SpdLmtPstdSpd : 23|8@0+ (1,0) [0|255] ""  CGM_LE,VCU_LE,IPC_LE,CHUD_LE,HUD_LE
 SG_ LnCat : 14|2@0+ (1,0) [0|3] ""  CGM_LE,Dummy_LE
 SG_ RdSpdCatType : 12|2@0+ (1,0) [0|3] ""  CGM_LE,Dummy_LE
 SG_ FncRdClass : 10|3@0+ (1,0) [0|7] ""  CGM_LE,Dummy_LE
 SG_ SprtLnRd : 2|1@0+ (1,0) [0|1] ""  CGM_LE,Dummy_LE
 SG_ CntrldAccRd : 3|1@0+ (1,0) [0|1] ""  CGM_LE,Dummy_LE
 SG_ BldUpArDet : 1|1@0+ (1,0) [0|1] ""  CGM_LE,Dummy_LE
 SG_ MpDataAvlbl : 0|1@0+ (1,0) [0|1] ""  CGM_LE,Dummy_LE
 SG_ DgtlMapPstdSpdLimAsrd : 7|1@0+ (1,0) [0|1] ""  CGM_LE

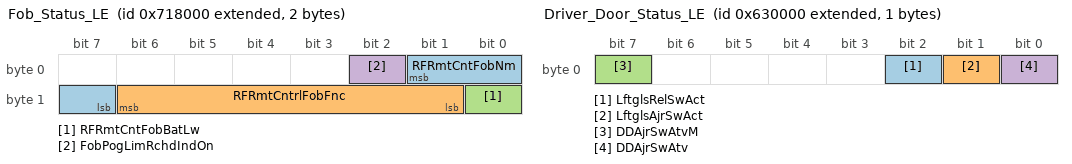
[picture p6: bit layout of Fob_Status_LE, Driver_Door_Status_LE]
BO_ 2154921984 Fob_Status_LE: 2 CGM_LE
 SG_ RFRmtCntFobNm : 1|3@0+ (1,0) [0|7] ""  TCP_LE,ONSTAR_LE,VCU_LE,IPC_LE,CHUD_LE,HUD_LE
 SG_ RFRmtCntrlFobFnc : 14|6@0+ (1,0) [0|63] ""  TCP_LE,ONSTAR_LE,VCU_LE,IPC_LE,CHUD_LE,HUD_LE
 SG_ RFRmtCntFobBatLw : 8|1@0+ (1,0) [0|1] ""  TCP_LE,ONSTAR_LE,VCU_LE,IPC_LE,CHUD_LE,HUD_LE
 SG_ FobPogLimRchdIndOn : 2|1@0+ (1,0) [0|1] ""  VCU_LE,IPC_LE

BO_ 2153971712 Driver_Door_Status_LE: 1 CGM_LE
 SG_ LftglsRelSwAct : 2|1@0+ (1,0) [0|1] ""  Dummy_LE
 SG_ LftglsAjrSwAct : 1|1@0+ (1,0) [0|1] ""  Dummy_LE,VPM_LE
 SG_ DDAjrSwAtvM : 7|1@0+ (1,0) [0|1] ""  AMP_LE,V2V_LE,CSM_LE,VCU_LE,RadioHead_LE
 SG_ DDAjrSwAtv : 0|1@0+ (1,0) [0|1] ""  VKM_LE,AMP_LE,V2V_LE,TCP_LE,ONSTAR_LE,CSM_LE,RadioHead_LE,VCU_LE,IPC_LE,CHUD_LE,HUD_LE,VPM_LE

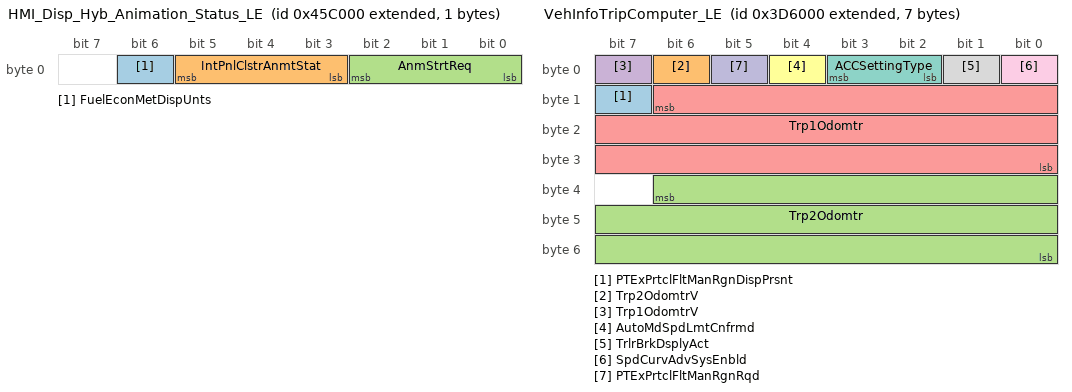
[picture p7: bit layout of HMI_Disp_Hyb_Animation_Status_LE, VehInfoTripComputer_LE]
BO_ 2152054784 HMI_Disp_Hyb_Animation_Status_LE: 1 IPC_LE
 SG_ FuelEconMetDispUnts : 6|1@0+ (1,0) [0|1] ""  CGM_LE,CSM_LE,VCU_LE,RadioHead_LE
 SG_ IntPnlClstrAnmtStat : 5|3@0+ (1,0) [0|7] ""  CGM_LE,VCU_LE,RadioHead_LE,CHUD_LE,HUD_LE
 SG_ AnmStrtReq : 2|3@0+ (1,0) [0|7] ""  CGM_LE,VCU_LE,RadioHead_LE,CHUD_LE,HUD_LE

BO_ 2151505920 VehInfoTripComputer_LE: 7 IPC_LE
 SG_ PTExPrtclFltManRgnDispPrsnt : 15|1@0+ (1,0) [0|1] ""  CGM_LE
 SG_ Trp2OdomtrV : 6|1@0+ (1,0) [0|1] ""  CGM_LE,VCU_LE,CSM_LE,RadioHead_LE
 SG_ Trp2Odomtr : 38|23@0+ (0.015625,0) [0|131071.984375] "km"  CGM_LE,VCU_LE,CSM_LE,RadioHead_LE
 SG_ Trp1OdomtrV : 7|1@0+ (1,0) [0|1] ""  CGM_LE,VCU_LE,CSM_LE,RadioHead_LE
 SG_ Trp1Odomtr : 14|23@0+ (0.015625,0) [0|131071.984375] "km"  CGM_LE,VCU_LE,CSM_LE,RadioHead_LE
 SG_ AutoMdSpdLmtCnfrmd : 4|1@0+ (1,0) [0|1] ""  CSM_LE,CGM_LE,Dummy_LE
 SG_ ACCSettingType : 3|2@0+ (1,0) [0|3] ""  CSM_LE,ONSTAR_LE,CGM_LE,Dummy_LE
 SG_ TrlrBrkDsplyAct : 1|1@0+ (1,0) [0|1] ""  CGM_LE,Dummy_LE
 SG_ SpdCurvAdvSysEnbld : 0|1@0+ (1,0) [0|1] ""  CSM_LE,ONSTAR_LE,CGM_LE,CHUD_LE,HUD_LE
 SG_ PTExPrtclFltManRgnRqd : 5|1@0+ (1,0) [0|1] ""  CGM_LE

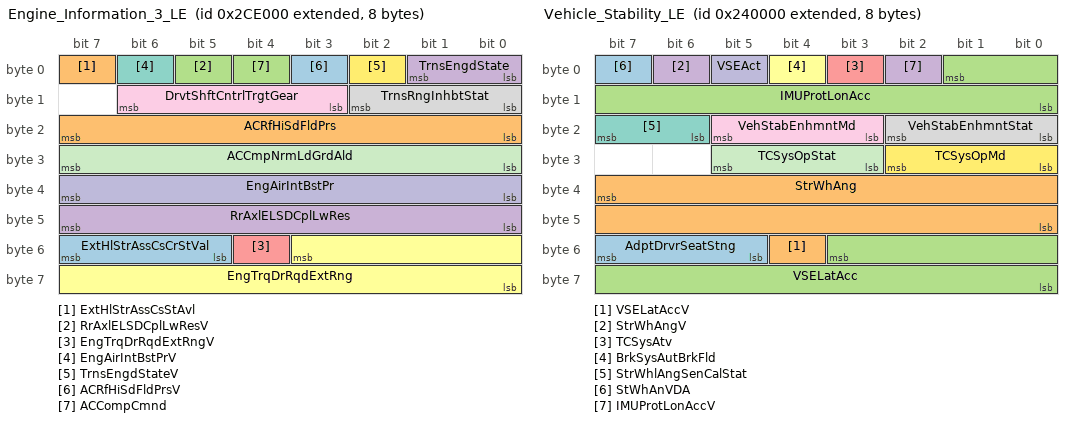
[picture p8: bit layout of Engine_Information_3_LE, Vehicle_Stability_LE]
BO_ 2150424576 Engine_Information_3_LE: 8 CGM_LE
 SG_ ExtHlStrAssCsCrStVal : 55|3@0+ (1,0) [0|7] ""  VCU_LE,CSM_LE,RadioHead_LE
 SG_ ExtHlStrAssCsStAvl : 7|1@0+ (1,0) [0|1] ""  VCU_LE,CSM_LE,RadioHead_LE
 SG_ RrAxlELSDCplLwResV : 5|1@0+ (1,0) [0|1] ""  VCU_LE,IPC_LE
 SG_ RrAxlELSDCplLwRes : 47|8@0+ (10,0) [0|2550] "Nm"  VCU_LE,IPC_LE
 SG_ EngTrqDrRqdExtRngV : 52|1@0+ (1,0) [0|1] ""  VCU_LE,IPC_LE
 SG_ EngTrqDrRqdExtRng : 51|12@0+ (0.5,-848) [-848|1199.5] "Nm"  VCU_LE,IPC_LE
 SG_ EngAirIntBstPrV : 6|1@0+ (1,0) [0|1] ""  CSM_LE,CHUD_LE,HUD_LE,RadioHead_LE,VCU_LE,IPC_LE
 SG_ TrnsRngInhbtStat : 10|3@0+ (1,0) [0|7] ""  CSM_LE,RadioHead_LE,VCU_LE,IPC_LE
 SG_ DrvtShftCntrlTrgtGear : 14|4@0+ (1,0) [0|15] ""  CSM_LE,RadioHead_LE,VCU_LE,IPC_LE
 SG_ EngAirIntBstPr : 39|8@0- (1,0) [-128|127] "kPaG"  CSM_LE,CHUD_LE,HUD_LE,RadioHead_LE,VCU_LE,IPC_LE
 SG_ ACCmpNrmLdGrdAld : 31|8@0+ (0.1,0) [0|25.5] "dm3/m/s"  CSM_LE,VCU_LE,RadioHead_LE
 SG_ TrnsEngdStateV : 2|1@0+ (1,0) [0|1] ""  CSM_LE,RadioHead_LE,VCU_LE,IPC_LE
 SG_ ACRfHiSdFldPrsV : 3|1@0+ (1,0) [0|1] ""  CSM_LE,VCU_LE,RadioHead_LE
 SG_ ACRfHiSdFldPrs : 23|8@0+ (14,0) [0|3570] "kPaG"  CSM_LE,VCU_LE,RadioHead_LE
 SG_ ACCompCmnd : 4|1@0+ (1,0) [0|1] ""  CSM_LE,VCU_LE,RadioHead_LE
 SG_ TrnsEngdState : 1|2@0+ (1,0) [0|3] ""  CSM_LE,RadioHead_LE,VCU_LE,IPC_LE

BO_ 2150416384 Engine_Information_2_LE: 8 CGM_LE
 SG_ PTWrmgWtToShftIO : 5|1@0+ (1,0) [0|1] ""  CSM_LE,VCU_LE,IPC_LE
 SG_ EngTrqActExtRngV : 21|1@0+ (1,0) [0|1] ""  CSM_LE,RadioHead_LE,VCU_LE,IPC_LE
 SG_ VehTopSpdLmtMdAct : 13|1@0+ (1,0) [0|1] ""  CSM_LE,RadioHead_LE,VCU_LE,IPC_LE
 SG_ EngTrqActExtRng : 51|12@0+ (0.5,-848) [-848|1199.5] "Nm"  CSM_LE,RadioHead_LE,VCU_LE,IPC_LE
 SG_ EngRunAtv : 8|1@0+ (1,0) [0|1] ""  VKM_LE,ICS_LE,VPM_LE,CSM_LE,CHUD_LE,HUD_LE,RadioHead_LE,TCP_LE,ONSTAR_LE,VCU_LE,IPC_LE,LVMNav_LE
 SG_ EngIdlAtv : 11|1@0+ (1,0) [0|1] ""  CSM_LE,RadioHead_LE,VCU_LE,IPC_LE
 SG_ EngSpdStat : 53|2@0+ (1,0) [0|3] ""  CHUD_LE,HUD_LE,CSM_LE,RadioHead_LE,VCU_LE,IPC_LE
 SG_ VaccBoostFailure : 2|1@0+ (1,0) [0|1] ""  CSM_LE,RadioHead_LE,VCU_LE,IPC_LE
 SG_ RmVhStrtEngRng : 54|1@0+ (1,0) [0|1] ""  CSM_LE,VCU_LE,RadioHead_LE,TCP_LE,ONSTAR_LE
 SG_ EngCoolFanSpd : 31|8@0+ (0.392157,0) [0|100.000035] "%"  CSM_LE,VCU_LE,RadioHead_LE
 SG_ TrnsVDA : 23|1@0+ (1,0) [0|1] ""  TCP_LE,CSM_LE,CHUD_LE,HUD_LE,ONSTAR_LE,RadioHead_LE,VCU_LE,IPC_LE
 SG_ GenFld : 3|1@0+ (1,0) [0|1] ""  CSM_LE,RadioHead_LE,VCU_LE,IPC_LE
 SG_ EngSpdLmtnMdAct : 4|1@0+ (1,0) [0|1] ""  CSM_LE,CHUD_LE,HUD_LE,RadioHead_LE,VCU_LE,IPC_LE
 SG_ EngNEmsnsRelMalfAct : 6|1@0+ (1,0) [0|1] ""  CSM_LE,RadioHead_LE,VCU_LE,IPC_LE
 SG_ EngCstFlCutAct : 7|1@0+ (1,0) [0|1] ""  CSM_LE,RadioHead_LE,VCU_LE,IPC_LE
 SG_ EngCylDeactMd : 15|2@0+ (1,0) [0|3] ""  AMP_LE,CSM_LE,RadioHead_LE,VCU_LE,IPC_LE
 SG_ EngBstPrsIndV : 0|1@0+ (1,0) [0|1] ""  CSM_LE,CHUD_LE,HUD_LE,RadioHead_LE,VCU_LE,IPC_LE
 SG_ EngBstPrsInd : 39|8@0+ (0.392157,0) [0|100.000035] "%"  CSM_LE,CHUD_LE,HUD_LE,RadioHead_LE,VCU_LE,IPC_LE
 SG_ TransEstGear : 19|4@0+ (1,0) [0|15] ""  CSM_LE,ICS_LE,CHUD_LE,HUD_LE,RadioHead_LE,VCU_LE,IPC_LE
 SG_ TransEstGearV : 20|1@0+ (1,0) [0|1] ""  CSM_LE,CHUD_LE,HUD_LE,RadioHead_LE,VCU_LE,IPC_LE
 SG_ EngVDA : 22|1@0+ (1,0) [0|1] ""  CSM_LE,TCP_LE,CHUD_LE,HUD_LE,OTIM_LE,ONSTAR_LE,RadioHead_LE,VCU_LE,IPC_LE
 SG_ TrnCrpMdAtv : 55|1@0+ (1,0) [0|1] ""  CSM_LE,RadioHead_LE,VCU_LE,IPC_LE
 SG_ VehTopSpdLmtArbVal : 47|8@0+ (2,0) [0|510] "km / h"  CSM_LE,RadioHead_LE,VCU_LE,IPC_LE

BO_ 2150408192 Engine_Information_1_LE: 8 CGM_LE
 SG_ ElcRngSelDrvAct : 5|1@0+ (1,0) [0|1] ""  VCU_LE,IPC_LE
 SG_ TmpDrvrShftCtlAct : 6|1@0+ (1,0) [0|1] ""  VCU_LE,IPC_LE
 SG_ AdptPsngrSeatStng : 63|3@0+ (1,0) [0|7] ""  Dummy_LE
 SG_ EngRunng : 14|1@0+ (1,0) [0|1] ""  RSE_LE,Dummy_LE
 SG_ Eng12vStrtrMtrCmmdOn : 13|1@0+ (1,0) [0|1] ""  Dummy_LE
 SG_ AccPdlOvrrdAtv : 7|1@0+ (1,0) [0|1] ""  CSM_LE,RadioHead_LE,VCU_LE,IPC_LE
 SG_ TopTrvlCltchSwActV : 60|1@0+ (1,0) [0|1] ""  CSM_LE,VCU_LE,RadioHead_LE
 SG_ TopTrvlCltchSwAct : 59|1@0+ (1,0) [0|1] ""  CSM_LE,VCU_LE,RadioHead_LE
 SG_ CltStartSwAtvV : 58|1@0+ (1,0) [0|1] ""  CSM_LE,VCU_LE,RadioHead_LE
 SG_ CltStartSwAtv : 57|1@0+ (1,0) [0|1] ""  CSM_LE,VCU_LE,RadioHead_LE
 SG_ CrsCntEnbld : 56|1@0+ (1,0) [0|1] ""  CSM_LE,RadioHead_LE,VCU_LE,IPC_LE
 SG_ AccActPosV : 4|1@0+ (1,0) [0|1] ""  CSM_LE,RadioHead_LE,VCU_LE,IPC_LE
 SG_ TrnsShftLvrPosV : 15|1@0+ (1,0) [0|1] ""  CSM_LE,RadioHead_LE,VCU_LE,IPC_LE
 SG_ TrnsSftMdStat : 2|3@0+ (1,0) [0|7] ""  CSM_LE,RadioHead_LE,VCU_LE,IPC_LE
 SG_ EngSpd : 23|16@0+ (0.25,0) [0|16383.75] "rpm"  RSE_LE,AMP_LE,CSM_LE,CHUD_LE,HUD_LE,RadioHead_LE,VCU_LE,IPC_LE
 SG_ AutoTransComndGear : 55|4@0+ (1,0) [0|15] ""  CSM_LE,TCP_LE,ONSTAR_LE,RadioHead_LE,VCU_LE,IPC_LE
 SG_ TrnShftPtrnActStat : 10|3@0+ (1,0) [0|7] ""  CSM_LE,RadioHead_LE,VCU_LE,IPC_LE
 SG_ TrnsShftLvrPos : 51|4@0+ (1,0) [0|15] ""  CSM_LE,RadioHead_LE,VCU_LE,IPC_LE
 SG_ AccActPos : 47|8@0+ (0.392157,0) [0|100.000035] "%"  CSM_LE,RadioHead_LE,VCU_LE,IPC_LE
 SG_ ThrPosV : 3|1@0+ (1,0) [0|1] ""  CSM_LE,RadioHead_LE,VCU_LE,IPC_LE
 SG_ TransTUDMdStat : 12|2@0+ (1,0) [0|3] ""  CSM_LE,RadioHead_LE,VCU_LE,IPC_LE
 SG_ ThrPos : 39|8@0+ (0.392157,0) [0|100.000035] "%"  CSM_LE,RadioHead_LE,VCU_LE,IPC_LE

BO_ 2149990400 HS_Indications_Fast_LE: 8 CGM_LE
 SG_ ElcTransRngRq : 39|3@0+ (1,0) [0|7] ""  VPM_LE
 SG_ TrnsfrCsRngShfSpdLmt : 47|8@0+ (1,0) [0|255] "km / h"  VCU_LE,IPC_LE
 SG_ TrlrBrkngVDA : 2|1@0+ (1,0) [0|1] ""  CSM_LE,RadioHead_LE,VCU_LE,IPC_LE
 SG_ SecAxlOperMod : 55|4@0+ (1,0) [0|15] ""  CSM_LE,RadioHead_LE,VCU_LE,IPC_LE
 SG_ InstFuelConsmpRate : 51|12@0+ (0.025,0) [0|102.375] "ltrs/hr"  CSM_LE,RadioHead_LE,VCU_LE,IPC_LE
 SG_ MotStBltUnblIO : 36|1@0+ (1,0) [0|1] ""  CSM_LE,RadioHead_LE,VCU_LE,IPC_LE
 SG_ MotStBltFldIO : 35|1@0+ (1,0) [0|1] ""  CSM_LE,RadioHead_LE,VCU_LE,IPC_LE
 SG_ TransNtrlCntrlMdStat : 34|2@0+ (1,0) [0|3] ""  CSM_LE,RadioHead_LE,VCU_LE,IPC_LE
 SG_ TrlrWiringFltIO : 7|1@0+ (1,0) [0|1] ""  CSM_LE,RadioHead_LE,VCU_LE,IPC_LE
 SG_ TrlrCnctdIO : 14|1@0+ (1,0) [0|1] ""  CSM_LE,RadioHead_LE,VCU_LE,IPC_LE
 SG_ TrlrBrkngGainSetIO : 13|1@0+ (1,0) [0|1] ""  CSM_LE,RadioHead_LE,VCU_LE,IPC_LE
 SG_ TrlrBrkngGainSet : 31|8@0+ (0.392157,0) [0|100.000035] "%"  CSM_LE,RadioHead_LE,VCU_LE,IPC_LE
 SG_ TrlrBrkngFrcOtpt : 23|8@0+ (0.392157,0) [0|100.000035] "%"  CSM_LE,RadioHead_LE,VCU_LE,IPC_LE
 SG_ SrvTrlrBrkngSysIO : 12|1@0+ (1,0) [0|1] ""  CSM_LE,RadioHead_LE,VCU_LE,IPC_LE
 SG_ ChkTrlrIO : 15|1@0+ (1,0) [0|1] ""  CSM_LE,RadioHead_LE,VCU_LE,IPC_LE
 SG_ ScndryAxleVDA : 11|1@0+ (1,0) [0|1] ""  CSM_LE,RadioHead_LE,VCU_LE,IPC_LE
 SG_ TrlrHtchSwAtv_ITBC : 32|1@0+ (1,0) [0|1] ""  CSM_LE,RadioHead_LE,VCU_LE,IPC_LE
 SG_ AdvHlmpsVDA : 9|1@0+ (1,0) [0|1] ""  CSM_LE,RadioHead_LE,VCU_LE,IPC_LE
 SG_ ABSIO : 0|1@0+ (1,0) [0|1] ""  CSM_LE,TCP_LE,ONSTAR_LE,RadioHead_LE,VCU_LE,IPC_LE
 SG_ ACCHdwayStngIO : 5|1@0+ (1,0) [0|1] ""  CSM_LE,CHUD_LE,HUD_LE,RadioHead_LE,VCU_LE,IPC_LE
 SG_ StpOnBrkToRelPBIndOn : 1|1@0+ (1,0) [0|1] ""  CSM_LE,RadioHead_LE,VCU_LE,IPC_LE
 SG_ SADmpVDA : 10|1@0+ (1,0) [0|1] ""  CSM_LE,RadioHead_LE,VCU_LE,IPC_LE
 SG_ ACCDrvrSeltdSpdIO : 6|1@0+ (1,0) [0|1] ""  CSM_LE,CHUD_LE,HUD_LE,RadioHead_LE,VCU_LE,IPC_LE
 SG_ TreInfMonSysRstPrfmd : 4|1@0+ (1,0) [0|1] ""  CSM_LE,RadioHead_LE,VCU_LE,IPC_LE
 SG_ DrvThrtlOvrdIO : 3|1@0+ (1,0) [0|1] ""  CSM_LE,CHUD_LE,HUD_LE,RadioHead_LE,VCU_LE,IPC_LE

BO_ 2149842944 Vehicle_Stability_LE: 8 CGM_LE
 SG_ AdptDrvrSeatStng : 55|3@0+ (1,0) [0|7] ""  Dummy_LE
 SG_ VSELatAccV : 52|1@0+ (1,0) [0|1] ""  CSM_LE,CHUD_LE,HUD_LE,RadioHead_LE,VCU_LE,IPC_LE
 SG_ VSELatAcc : 51|12@0- (0.015625,0) [-32|31.984375] "m/s^2"  CSM_LE,CHUD_LE,HUD_LE,RadioHead_LE,VCU_LE,IPC_LE
 SG_ StrWhAngV : 6|1@0+ (1,0) [0|1] ""  VPM_LE,VCU_LE,CSM_LE,RadioHead_LE
 SG_ TCSysAtv : 3|1@0+ (1,0) [0|1] ""  CSM_LE,RadioHead_LE,VCU_LE,IPC_LE
 SG_ BrkSysAutBrkFld : 4|1@0+ (1,0) [0|1] ""  CSM_LE,RadioHead_LE,VCU_LE,IPC_LE
 SG_ StrWhlAngSenCalStat : 23|2@0+ (1,0) [0|3] ""  VPM_LE,VCU_LE,CSM_LE,RadioHead_LE
 SG_ VehStabEnhmntStat : 18|3@0+ (1,0) [0|7] ""  CSM_LE,RadioHead_LE,VCU_LE,IPC_LE
 SG_ VehStabEnhmntMd : 21|3@0+ (1,0) [0|7] ""  CSM_LE,RadioHead_LE,VCU_LE,IPC_LE
 SG_ VSEAct : 5|1@0+ (1,0) [0|1] ""  CSM_LE,RadioHead_LE,VCU_LE,IPC_LE
 SG_ TCSysOpStat : 29|3@0+ (1,0) [0|7] ""  CSM_LE,RadioHead_LE,VCU_LE,IPC_LE
 SG_ TCSysOpMd : 26|3@0+ (1,0) [0|7] ""  CSM_LE,RadioHead_LE,VCU_LE,IPC_LE
 SG_ StWhAnVDA : 7|1@0+ (1,0) [0|1] ""  VPM_LE,VCU_LE,CSM_LE,RadioHead_LE
 SG_ StrWhAng : 39|16@0- (0.0625,0) [-2048|2047.9375] "deg"  VPM_LE,VCU_LE,CSM_LE,RadioHead_LE
 SG_ IMUProtLonAcc : 1|10@0- (0.03,0) [-15.36|15.33] "m/s^2"  CSM_LE,RadioHead_LE,VCU_LE,IPC_LE
 SG_ IMUProtLonAccV : 2|1@0+ (1,0) [0|1] ""  CSM_LE,RadioHead_LE,VCU_LE,IPC_LE

BO_TX_BU_ 2158960640 : CSM_LE,VCU_LE,RadioHead_LE;
BO_TX_BU_ 2158755840 : TCP_LE,CGM_LE,PDIM_LE,UHP_Low_LE,ONSTAR_LE;
BO_TX_BU_ 2159058944 : VCU_LE,IPC_LE;
BO_TX_BU_ 2158977024 : CSM_LE,VCU_LE,RadioHead_LE;
BO_TX_BU_ 2159001600 : VCU_LE,IPC_LE;
BO_TX_BU_ 2158993408 : CSM_LE,VCU_LE,RadioHead_LE;
BO_TX_BU_ 2159026176 : TCP_LE,CGM_LE,PDIM_LE,UHP_Low_LE,ONSTAR_LE;
BO_TX_BU_ 2159116288 : VCU_LE,RadioHead_LE,UHP_Low_LE,ONSTAR_LE;
BO_TX_BU_ 2159042560 : VCU_LE,IPC_LE;
BO_TX_BU_ 2158927872 : CSM_LE,VCU_LE,RadioHead_LE;
BO_TX_BU_ 2159099904 : VCU_LE,RadioHead_LE;
BO_TX_BU_ 2159181824 : VCU_LE,RadioHead_LE;
BO_TX_BU_ 1622 : CGM_LE,RSE_LE,RSA_LE;
BO_TX_BU_ 1590 : CGM_LE,RSE_LE,RSA_LE;
BO_TX_BU_ 1366 : CGM_LE,RSE_LE,RSA_LE;
BO_TX_BU_ 2156789760 : VCU_LE,CSM_LE,RadioHead_LE;
BO_TX_BU_ 2151956480 : VCU_LE,IPC_LE;
BO_TX_BU_ 2150268928 : TCP_LE,ONSTAR_LE;
BO_TX_BU_ 2156175360 : VCU_LE,IPC_LE;
BO_TX_BU_ 2155216896 : VCU_LE,CSM_LE,RadioHead_LE;
BO_TX_BU_ 2152054784 : VCU_LE,IPC_LE;
BO_TX_BU_ 2151505920 : VCU_LE,IPC_LE;
CM_ SG_ 2158960640 ODIIC_FUCID "ODI - Primary ID of Functional Unit in FU Database";
CM_ SG_ 2158755840 ODIE_FUCID "ODI - Primary ID of Functional Unit in FU Database";
CM_ SG_ 2158755840 ODIE_EvID "EventID within FUClass";
CM_ SG_ 2159058944 ODIEI_FUCID "ODI - Primary ID of Functional Unit in FU Database";
CM_ SG_ 2159058944 ODIEI_EvID "EventID within FUClass";
CM_ SG_ 2158977024 ODIEC_FUCID "ODI - Primary ID of Functional Unit in FU Database";
CM_ SG_ 2158977024 ODIEC_EvID "EventID within FUClass";
CM_ SG_ 2158936064 ODIEDD_Data18Value "ODI";
CM_ SG_ 2158936064 ODIEDD_Data17Value "ODI";
CM_ SG_ 2158936064 ODIEDD_Data16Value "ODI";
CM_ SG_ 2158936064 ODIEDD_Data15Value "ODI";
CM_ SG_ 2158936064 ODIEDD_Data14Value "ODI";
CM_ SG_ 2158936064 ODIEDD_Data13Value "ODI";
CM_ SG_ 2158936064 ODIEDD_Data12Value "ODI";
CM_ SG_ 2158936064 ODIEDD_Data11Value "ODI";
CM_ SG_ 2158936064 ODIEDD_Data10Value "ODI";
CM_ SG_ 2158936064 ODIEDD_Data9Value "ODI";
CM_ SG_ 2158936064 ODIEDD_Data8Value "ODI";
CM_ SG_ 2158936064 ODIEDD_Data7Value "ODI";
CM_ SG_ 2158936064 ODIEDD_Data6Value "ODI";
CM_ SG_ 2158936064 ODIEDD_Data5Value "ODI";
CM_ SG_ 2158936064 ODIEDD_Data4Value "ODI";
CM_ SG_ 2158936064 ODIEDD_Data3Value "ODI";
CM_ SG_ 2158936064 ODIEDD_Data2Value "ODI";
CM_ SG_ 2158936064 ODIEDD_Data1Value "ODI";
CM_ SG_ 2158936064 ODIEDD_FUCID "ODI - Primary ID of Functional Unit in FU Database";
CM_ SG_ 2159001600 ODIEDDIPC_FUCID "ODI - Primary ID of Functional Unit in FU Database";
CM_ SG_ 2159001600 ODIEDDIPC_Data18Value "ODI";
CM_ SG_ 2159001600 ODIEDDIPC_Data17Value "ODI";
CM_ SG_ 2159001600 ODIEDDIPC_Data16Value "ODI";
CM_ SG_ 2159001600 ODIEDDIPC_Data15Value "ODI";
CM_ SG_ 2159001600 ODIEDDIPC_Data14Value "ODI";
CM_ SG_ 2159001600 ODIEDDIPC_Data13Value "ODI";
CM_ SG_ 2159001600 ODIEDDIPC_Data12Value "ODI";
CM_ SG_ 2159001600 ODIEDDIPC_Data11Value "ODI";
CM_ SG_ 2159001600 ODIEDDIPC_Data10Value "ODI";
CM_ SG_ 2159001600 ODIEDDIPC_Data9Value "ODI";
CM_ SG_ 2159001600 ODIEDDIPC_Data8Value "ODI";
CM_ SG_ 2159001600 ODIEDDIPC_Data7Value "ODI";
CM_ SG_ 2159001600 ODIEDDIPC_Data6Value "ODI";
CM_ SG_ 2159001600 ODIEDDIPC_Data5Value "ODI";
CM_ SG_ 2159001600 ODIEDDIPC_Data4Value "ODI";
CM_ SG_ 2159001600 ODIEDDIPC_Data3Value "ODI";
CM_ SG_ 2159001600 ODIEDDIPC_Data2Value "ODI";
CM_ SG_ 2159001600 ODIEDDIPC_Data1Value "ODI";
CM_ SG_ 2158993408 ODIEDDCS_FUCID "ODI - Primary ID of Functional Unit in FU Database";
CM_ SG_ 2158993408 ODIEDDCS_Data9Value "ODI";
CM_ SG_ 2158993408 ODIEDDCS_Data8Value "ODI";
CM_ SG_ 2158993408 ODIEDDCS_Data7Value "ODI";
CM_ SG_ 2158993408 ODIEDDCS_Data6Value "ODI";
CM_ SG_ 2158993408 ODIEDDCS_Data5Value "ODI";
CM_ SG_ 2158993408 ODIEDDCS_Data4Value "ODI";
CM_ SG_ 2158993408 ODIEDDCS_Data3Value "ODI";
CM_ SG_ 2158993408 ODIEDDCS_Data2Value "ODI";
CM_ SG_ 2158993408 ODIEDDCS_Data18Value "ODI";
CM_ SG_ 2158993408 ODIEDDCS_Data17Value "ODI";
CM_ SG_ 2158993408 ODIEDDCS_Data16Value "ODI";
CM_ SG_ 2158993408 ODIEDDCS_Data15Value "ODI";
CM_ SG_ 2158993408 ODIEDDCS_Data14Value "ODI";
CM_ SG_ 2158993408 ODIEDDCS_Data13Value "ODI";
CM_ SG_ 2158993408 ODIEDDCS_Data12Value "ODI";
CM_ SG_ 2158993408 ODIEDDCS_Data11Value "ODI";
CM_ SG_ 2158993408 ODIEDDCS_Data10Value "ODI";
CM_ SG_ 2158993408 ODIEDDCS_Data1Value "ODI";
CM_ SG_ 2159026176 ODD_InvldData "ODI";
CM_ SG_ 2159026176 ODD_FUCID "ODI - Primary ID of Functional Unit in FU Database";
CM_ SG_ 2159026176 ODD_DataVal "ODI";
CM_ SG_ 2159026176 ODD_DataType "ODI";
CM_ SG_ 2159026176 ODD_DataId "ODI-Data Id for the dynamic list";
CM_ SG_ 2159042560 ODDI_DataVal "ODI";
CM_ SG_ 2159042560 ODDI_DataId "ODI-Data Id for the dynamic list";
CM_ SG_ 2159042560 ODDI_FUCID "ODI - Primary ID of Functional Unit in FU Database";
CM_ SG_ 2159042560 ODDI_InvldData "ODI";
CM_ SG_ 2159042560 ODDI_DataType "ODI";
CM_ SG_ 2158927872 ODDC_InvldData "ODI";
CM_ SG_ 2158927872 ODDC_FUCID "ODI - Primary ID of Functional Unit in FU Database";
CM_ SG_ 2158927872 ODDC_DataVal "ODI";
CM_ SG_ 2158927872 ODDC_DataType "ODI";
CM_ SG_ 2158927872 ODDC_DataId "ODI-Data Id for the dynamic list";
CM_ SG_ 2155216896 SpdLmtUnits "This signal indicates the units used for the Speed Limit Posted Speed and Speed Limit Recommended Speed signals";
CM_ SG_ 2155216896 SpdLmtRecmndSpd "Seperate signal 'Speed Limit Units' must be used to define selectable units for this signal";
CM_ SG_ 2155216896 SpdLmtPstdSpd "Seperate signal 'Speed Limit Units' must be used to define selectable units for this signal";
CM_ SG_ 2150424576 ACCmpNrmLdGrdAld "dm3/m/s = dm3/minute/second";
CM_ SG_ 2150416384 EngRunAtv "Indication from powertrain that the engine is running (Has RPM > 0)";
CM_ SG_ 2150408192 TrnShftPtrnActStat "(PT = Powertrain)";
CM_ SG_ 2149842944 BrkSysAutBrkFld "BrakeSystemAutomaticBrakingFailed";
BA_DEF_ SG_  "VNSigPrimaryTriggering" ENUM  "No","Yes","DLCLS","DLCHS","DLCCE","DLCFO";
BA_DEF_ SG_  "VNSigRemoteDiagnostics" ENUM  "No","Yes","DLCLS","DLCHS","DLCCE","DLCFO";
BA_DEF_ SG_  "VNSigInfotainment" ENUM  "No","Yes","DLCLS","DLCHS","DLCCE","DLCFO";
BA_DEF_ SG_  "VNSigParkedVehicle" ENUM  "No","Yes","DLCLS","DLCHS","DLCCE","DLCFO";
BA_DEF_ SG_  "VNSigIntermediate" ENUM  "No","Yes","DLCLS","DLCHS","DLCCE","DLCFO";
BA_DEF_ SG_  "VNSigUnused_4" ENUM  "No","Yes","DLCLS","DLCHS","DLCCE","DLCFO";
BA_DEF_ SG_  "SignalType" STRING ;
BA_DEF_ SG_  "PacketOrder" INT 0 65535;
BA_DEF_ SG_  "SignalLongName" STRING ;
BA_DEF_ SG_  "GenSigStartValue" INT 0 65535;
BA_DEF_ SG_  "VNSigDiagnostic" ENUM  "No","Yes","DLCLS","DLCHS","DLCCE","DLCFO";
BA_DEF_ SG_  "VNSigAllNodes" ENUM  "No","Yes","DLCLS","DLCHS","DLCCE","DLCFO";
BA_DEF_ SG_  "GenSigDeltaValue" INT 0 0;
BA_DEF_ SG_  "GenSigSendType" ENUM  "not used","not used","not used","not used","not used","not used","not used","NoSigSendType","not used","not used","OnAnyChange","OnChangeIfActive","OnDelta","DLCLS","DLCHS","DLCCE","DLCFO";
BA_DEF_ SG_  "GenSigSendOnInit" ENUM  "Not Initialized","Application","Handler","DLCLS","DLCHS","DLCCE","DLCFO";
BA_DEF_ BO_  "AppGenMsgCycleTime" INT 0 0;
BA_DEF_ BO_  "TpTxIndex" INT 0 99;
BA_DEF_ BO_  "GenMsgILSupport" ENUM  "No","Yes","DLCLS","DLCHS","DLCCE","DLCFO";
BA_DEF_ BO_  "TpApplType" STRING ;
BA_DEF_ BO_  "Prio" INT 0 7;
BA_DEF_ BO_  "MessageSubnet" ENUM  "LS","MS","HS","CE","PE","HV","FO","S1","HE","LE","HE2","DLCLS","DLCHS","DLCCE","DLCFO";
BA_DEF_ BO_  "GenMsgMandatoryToSupervision" ENUM  "No","Yes","DLCLS","DLCHS","DLCCE","DLCFO";
BA_DEF_ BO_  "DiagState" ENUM  "No","Yes","DLCLS","DLCHS","DLCCE","DLCFO";
BA_DEF_ BO_  "GenMsgStartDelayTime" INT 0 100000;
BA_DEF_ BO_  "GenMsgDelayTime" INT 0 100000;
BA_DEF_ BO_  "GenMsgCycleTime" INT 0 100000;
BA_DEF_ BO_  "GenMsgSendType" ENUM  "cyclicX","spontanX","cyclicIfActiveX","spontanWithDelay","cyclicAndSpontanX","cyclicAndSpontanWithDelay","spontanWithRepitition","cyclicIfActiveAndSpontanWD","DLCLS","DLCHS","DLCCE","DLCFO";
BA_DEF_ BO_  "DiagResponse" ENUM  "No","Yes","DLCLS","DLCHS","DLCCE","DLCFO";
BA_DEF_ BO_  "DiagRequest" ENUM  "No","Yes","DLCLS","DLCHS","DLCCE","DLCFO";
BA_DEF_ BO_  "NmMessage" ENUM  "No","Yes","DLCLS","DLCHS","DLCCE","DLCFO";
BA_DEF_REL_ BU_SG_REL_  "GenSigSuprvRespComment" STRING ;
BA_DEF_REL_ BU_SG_REL_  "GenSigVBitResp" ENUM  "No","Yes","DLCLS","DLCHS","DLCCE","DLCFO";
BA_DEF_REL_ BU_SG_REL_  "GenSigVBitRespComment" STRING ;
BA_DEF_REL_ BU_SG_REL_  "GenSigVDAFailComment" STRING ;
BA_DEF_REL_ BU_SG_REL_  "GenSigVDAFailResp" ENUM  "No","Yes","DLCLS","DLCHS","DLCCE","DLCFO";
BA_DEF_REL_ BU_SG_REL_  "GenSigRxStartValue" STRING ;
BA_DEF_REL_ BU_SG_REL_  "GenSigSuprvRespSubValue" INT 0 65535;
BA_DEF_REL_ BU_SG_REL_  "GenSigSuprvResp" ENUM  "None","Notify App","Substitute Default","DLCLS","DLCHS","DLCCE","DLCFO";
BA_DEF_REL_ BU_SG_REL_  "GenSigTimeoutMsg" HEX -2147483648 268435455;
BA_DEF_DEF_  "VNSigPrimaryTriggering" "No";
BA_DEF_DEF_  "VNSigRemoteDiagnostics" "No";
BA_DEF_DEF_  "VNSigInfotainment" "No";
BA_DEF_DEF_  "VNSigParkedVehicle" "No";
BA_DEF_DEF_  "VNSigIntermediate" "No";
BA_DEF_DEF_  "VNSigUnused_4" "No";
BA_DEF_DEF_  "SignalType" "";
BA_DEF_DEF_  "PacketOrder" 0;
BA_DEF_DEF_  "SignalLongName" "";
BA_DEF_DEF_  "GenSigStartValue" 0;
BA_DEF_DEF_  "VNSigDiagnostic" "No";
BA_DEF_DEF_  "VNSigAllNodes" "No";
BA_DEF_DEF_  "GenSigDeltaValue" 0;
BA_DEF_DEF_  "GenSigSendType" "NoSigSendType";
BA_DEF_DEF_  "GenSigSendOnInit" "Not Initialized";
BA_DEF_DEF_  "AppGenMsgCycleTime" 0;
BA_DEF_DEF_  "TpTxIndex" 0;
BA_DEF_DEF_  "GenMsgILSupport" "Yes";
BA_DEF_DEF_  "TpApplType" "";
BA_DEF_DEF_  "Prio" 4;
BA_DEF_DEF_  "MessageSubnet" "FO";
BA_DEF_DEF_  "GenMsgMandatoryToSupervision" "No";
BA_DEF_DEF_  "DiagState" "No";
BA_DEF_DEF_  "GenMsgStartDelayTime" 0;
BA_DEF_DEF_  "GenMsgDelayTime" 0;
BA_DEF_DEF_  "GenMsgCycleTime" 0;
BA_DEF_DEF_  "GenMsgSendType" "spontanX";
BA_DEF_DEF_  "DiagResponse" "No";
BA_DEF_DEF_  "DiagRequest" "No";
BA_DEF_DEF_  "NmMessage" "No";
BA_DEF_DEF_REL_ "GenSigSuprvRespComment" "";
BA_DEF_DEF_REL_ "GenSigVBitResp" "No";
BA_DEF_DEF_REL_ "GenSigVBitRespComment" "";
BA_DEF_DEF_REL_ "GenSigVDAFailComment" "";
BA_DEF_DEF_REL_ "GenSigVDAFailResp" "No";
BA_DEF_DEF_REL_ "GenSigRxStartValue" "";
BA_DEF_DEF_REL_ "GenSigSuprvRespSubValue" 0;
BA_DEF_DEF_REL_ "GenSigSuprvResp" "None";
BA_DEF_DEF_REL_ "GenSigTimeoutMsg" 0;
BA_ "MessageSubnet" BO_ 2158960640 9;
BA_ "GenMsgDelayTime" BO_ 2158960640 100;
BA_ "MessageSubnet" BO_ 2158755840 9;
BA_ "GenMsgDelayTime" BO_ 2158755840 100;
BA_ "MessageSubnet" BO_ 2159058944 9;
BA_ "GenMsgDelayTime" BO_ 2159058944 100;
BA_ "MessageSubnet" BO_ 2158977024 9;
BA_ "GenMsgDelayTime" BO_ 2158977024 100;
BA_ "MessageSubnet" BO_ 2158936064 9;
BA_ "GenMsgDelayTime" BO_ 2158936064 100;
BA_ "MessageSubnet" BO_ 2159001600 9;
BA_ "GenMsgDelayTime" BO_ 2159001600 100;
BA_ "MessageSubnet" BO_ 2158993408 9;
BA_ "GenMsgDelayTime" BO_ 2158993408 100;
BA_ "MessageSubnet" BO_ 2159026176 9;
BA_ "GenMsgDelayTime" BO_ 2159026176 10;
BA_ "MessageSubnet" BO_ 2159116288 9;
BA_ "GenMsgDelayTime" BO_ 2159116288 10;
BA_ "MessageSubnet" BO_ 2159042560 9;
BA_ "GenMsgDelayTime" BO_ 2159042560 100;
BA_ "MessageSubnet" BO_ 2158927872 9;
BA_ "GenMsgDelayTime" BO_ 2158927872 100;
BA_ "MessageSubnet" BO_ 2159099904 9;
BA_ "GenMsgDelayTime" BO_ 2159099904 10;
BA_ "MessageSubnet" BO_ 2159181824 9;
BA_ "GenMsgDelayTime" BO_ 2159181824 10;
BA_ "Prio" BO_ 1622 0;
BA_ "MessageSubnet" BO_ 1622 9;
BA_ "DiagResponse" BO_ 1622 1;
BA_ "Prio" BO_ 1590 0;
BA_ "MessageSubnet" BO_ 1590 9;
BA_ "GenMsgCycleTime" BO_ 1590 3000;
BA_ "GenMsgSendType" BO_ 1590 0;
BA_ "NmMessage" BO_ 1590 1;
BA_ "GenMsgILSupport" BO_ 1366 0;
BA_ "TpApplType" BO_ 1366 "DiagUUDTResponse";
BA_ "Prio" BO_ 1366 0;
BA_ "MessageSubnet" BO_ 1366 9;
BA_ "MessageSubnet" BO_ 2156789760 9;
BA_ "GenMsgDelayTime" BO_ 2156789760 100;
BA_ "MessageSubnet" BO_ 2151956480 9;
BA_ "GenMsgDelayTime" BO_ 2151956480 20;
BA_ "MessageSubnet" BO_ 2150268928 9;
BA_ "GenMsgDelayTime" BO_ 2150268928 100;
BA_ "MessageSubnet" BO_ 2156175360 9;
BA_ "GenMsgDelayTime" BO_ 2156175360 50;
BA_ "MessageSubnet" BO_ 2154053632 9;
BA_ "GenMsgMandatoryToSupervision" BO_ 2154053632 1;
BA_ "GenMsgDelayTime" BO_ 2154053632 100;
BA_ "MessageSubnet" BO_ 2155216896 9;
BA_ "GenMsgDelayTime" BO_ 2155216896 100;
BA_ "Prio" BO_ 2154921984 3;
BA_ "MessageSubnet" BO_ 2154921984 9;
BA_ "GenMsgDelayTime" BO_ 2154921984 100;
BA_ "Prio" BO_ 2153971712 3;
BA_ "MessageSubnet" BO_ 2153971712 9;
BA_ "GenMsgDelayTime" BO_ 2153971712 100;
BA_ "MessageSubnet" BO_ 2152054784 9;
BA_ "GenMsgDelayTime" BO_ 2152054784 100;
BA_ "MessageSubnet" BO_ 2151505920 9;
BA_ "GenMsgDelayTime" BO_ 2151505920 100;
BA_ "GenMsgCycleTime" BO_ 2151505920 1000;
BA_ "GenMsgSendType" BO_ 2151505920 0;
BA_ "MessageSubnet" BO_ 2150424576 9;
BA_ "GenMsgMandatoryToSupervision" BO_ 2150424576 1;
BA_ "GenMsgStartDelayTime" BO_ 2150424576 150;
BA_ "GenMsgCycleTime" BO_ 2150424576 250;
BA_ "GenMsgSendType" BO_ 2150424576 0;
BA_ "MessageSubnet" BO_ 2150416384 9;
BA_ "GenMsgStartDelayTime" BO_ 2150416384 140;
BA_ "GenMsgCycleTime" BO_ 2150416384 250;
BA_ "GenMsgSendType" BO_ 2150416384 0;
BA_ "MessageSubnet" BO_ 2150408192 9;
BA_ "GenMsgMandatoryToSupervision" BO_ 2150408192 1;
BA_ "GenMsgStartDelayTime" BO_ 2150408192 180;
BA_ "GenMsgCycleTime" BO_ 2150408192 100;
BA_ "GenMsgSendType" BO_ 2150408192 0;
BA_ "MessageSubnet" BO_ 2149990400 9;
BA_ "GenMsgStartDelayTime" BO_ 2149990400 200;
BA_ "GenMsgCycleTime" BO_ 2149990400 100;
BA_ "GenMsgSendType" BO_ 2149990400 0;
BA_ "MessageSubnet" BO_ 2149842944 9;
BA_ "GenMsgStartDelayTime" BO_ 2149842944 160;
BA_ "GenMsgCycleTime" BO_ 2149842944 100;
BA_ "GenMsgSendType" BO_ 2149842944 0;
BA_ "GenSigDeltaValue" SG_ 2158960640 ODIIC_FUCID 1;
BA_ "GenSigSendType" SG_ 2158960640 ODIIC_FUCID 12;
BA_ "GenSigSendOnInit" SG_ 2158960640 ODIIC_FUCID 1;
BA_ "VNSigInfotainment" SG_ 2158960640 ODIIC_FUCID 1;
BA_ "SignalType" SG_ 2158960640 ODIIC_FUCID "UNM";
BA_ "PacketOrder" SG_ 2158960640 ODIIC_FUCID 1;
BA_ "SignalLongName" SG_ 2158960640 ODIIC_FUCID "Open Display Interface Indication Centerstack: Functional Unit Class ID";
BA_ "VNSigAllNodes" SG_ 2158960640 ODIIC_FUCID 1;
BA_ "GenSigSendType" SG_ 2158960640 ODIIC_ODIInd9 10;
BA_ "GenSigSendOnInit" SG_ 2158960640 ODIIC_ODIInd9 1;
BA_ "VNSigInfotainment" SG_ 2158960640 ODIIC_ODIInd9 1;
BA_ "SignalType" SG_ 2158960640 ODIIC_ODIInd9 "BLN";
BA_ "PacketOrder" SG_ 2158960640 ODIIC_ODIInd9 10;
BA_ "SignalLongName" SG_ 2158960640 ODIIC_ODIInd9 "Open Display Interface Indication Centerstack : Open Display Interface Indication 9";
BA_ "VNSigAllNodes" SG_ 2158960640 ODIIC_ODIInd9 1;
BA_ "GenSigSendType" SG_ 2158960640 ODIIC_ODIInd8 10;
BA_ "GenSigSendOnInit" SG_ 2158960640 ODIIC_ODIInd8 1;
BA_ "VNSigInfotainment" SG_ 2158960640 ODIIC_ODIInd8 1;
BA_ "SignalType" SG_ 2158960640 ODIIC_ODIInd8 "BLN";
BA_ "PacketOrder" SG_ 2158960640 ODIIC_ODIInd8 9;
BA_ "SignalLongName" SG_ 2158960640 ODIIC_ODIInd8 "Open Display Interface Indication Centerstack : Open Display Interface Indication 8";
BA_ "VNSigAllNodes" SG_ 2158960640 ODIIC_ODIInd8 1;
BA_ "GenSigSendType" SG_ 2158960640 ODIIC_ODIInd7 10;
BA_ "GenSigSendOnInit" SG_ 2158960640 ODIIC_ODIInd7 1;
BA_ "VNSigInfotainment" SG_ 2158960640 ODIIC_ODIInd7 1;
BA_ "SignalType" SG_ 2158960640 ODIIC_ODIInd7 "BLN";
BA_ "PacketOrder" SG_ 2158960640 ODIIC_ODIInd7 8;
BA_ "SignalLongName" SG_ 2158960640 ODIIC_ODIInd7 "Open Display Interface Indication Centerstack : Open Display Interface Indication 7";
BA_ "VNSigAllNodes" SG_ 2158960640 ODIIC_ODIInd7 1;
BA_ "GenSigSendType" SG_ 2158960640 ODIIC_ODIInd6 10;
BA_ "GenSigSendOnInit" SG_ 2158960640 ODIIC_ODIInd6 1;
BA_ "VNSigInfotainment" SG_ 2158960640 ODIIC_ODIInd6 1;
BA_ "SignalType" SG_ 2158960640 ODIIC_ODIInd6 "BLN";
BA_ "PacketOrder" SG_ 2158960640 ODIIC_ODIInd6 7;
BA_ "SignalLongName" SG_ 2158960640 ODIIC_ODIInd6 "Open Display Interface Indication Centerstack : Open Display Interface Indication 6";
BA_ "VNSigAllNodes" SG_ 2158960640 ODIIC_ODIInd6 1;
BA_ "GenSigSendType" SG_ 2158960640 ODIIC_ODIInd56 10;
BA_ "GenSigSendOnInit" SG_ 2158960640 ODIIC_ODIInd56 1;
BA_ "VNSigInfotainment" SG_ 2158960640 ODIIC_ODIInd56 1;
BA_ "SignalType" SG_ 2158960640 ODIIC_ODIInd56 "BLN";
BA_ "PacketOrder" SG_ 2158960640 ODIIC_ODIInd56 57;
BA_ "SignalLongName" SG_ 2158960640 ODIIC_ODIInd56 "Open Display Interface Indication Centerstack : Open Display Interface Indication 56";
BA_ "VNSigAllNodes" SG_ 2158960640 ODIIC_ODIInd56 1;
BA_ "GenSigSendType" SG_ 2158960640 ODIIC_ODIInd55 10;
BA_ "GenSigSendOnInit" SG_ 2158960640 ODIIC_ODIInd55 1;
BA_ "VNSigInfotainment" SG_ 2158960640 ODIIC_ODIInd55 1;
BA_ "SignalType" SG_ 2158960640 ODIIC_ODIInd55 "BLN";
BA_ "PacketOrder" SG_ 2158960640 ODIIC_ODIInd55 56;
BA_ "SignalLongName" SG_ 2158960640 ODIIC_ODIInd55 "Open Display Interface Indication Centerstack : Open Display Interface Indication 55";
BA_ "VNSigAllNodes" SG_ 2158960640 ODIIC_ODIInd55 1;
BA_ "GenSigSendType" SG_ 2158960640 ODIIC_ODIInd54 10;
BA_ "GenSigSendOnInit" SG_ 2158960640 ODIIC_ODIInd54 1;
BA_ "VNSigInfotainment" SG_ 2158960640 ODIIC_ODIInd54 1;
BA_ "SignalType" SG_ 2158960640 ODIIC_ODIInd54 "BLN";
BA_ "PacketOrder" SG_ 2158960640 ODIIC_ODIInd54 55;
BA_ "SignalLongName" SG_ 2158960640 ODIIC_ODIInd54 "Open Display Interface Indication Centerstack : Open Display Interface Indication 54";
BA_ "VNSigAllNodes" SG_ 2158960640 ODIIC_ODIInd54 1;
BA_ "GenSigSendType" SG_ 2158960640 ODIIC_ODIInd53 10;
BA_ "GenSigSendOnInit" SG_ 2158960640 ODIIC_ODIInd53 1;
BA_ "VNSigInfotainment" SG_ 2158960640 ODIIC_ODIInd53 1;
BA_ "SignalType" SG_ 2158960640 ODIIC_ODIInd53 "BLN";
BA_ "PacketOrder" SG_ 2158960640 ODIIC_ODIInd53 54;
BA_ "SignalLongName" SG_ 2158960640 ODIIC_ODIInd53 "Open Display Interface Indication Centerstack : Open Display Interface Indication 53";
BA_ "VNSigAllNodes" SG_ 2158960640 ODIIC_ODIInd53 1;
BA_ "GenSigSendType" SG_ 2158960640 ODIIC_ODIInd52 10;
BA_ "GenSigSendOnInit" SG_ 2158960640 ODIIC_ODIInd52 1;
BA_ "VNSigInfotainment" SG_ 2158960640 ODIIC_ODIInd52 1;
BA_ "SignalType" SG_ 2158960640 ODIIC_ODIInd52 "BLN";
BA_ "PacketOrder" SG_ 2158960640 ODIIC_ODIInd52 53;
BA_ "SignalLongName" SG_ 2158960640 ODIIC_ODIInd52 "Open Display Interface Indication Centerstack : Open Display Interface Indication 52";
BA_ "VNSigAllNodes" SG_ 2158960640 ODIIC_ODIInd52 1;
BA_ "GenSigSendType" SG_ 2158960640 ODIIC_ODIInd51 10;
BA_ "GenSigSendOnInit" SG_ 2158960640 ODIIC_ODIInd51 1;
BA_ "VNSigInfotainment" SG_ 2158960640 ODIIC_ODIInd51 1;
BA_ "SignalType" SG_ 2158960640 ODIIC_ODIInd51 "BLN";
BA_ "PacketOrder" SG_ 2158960640 ODIIC_ODIInd51 52;
BA_ "SignalLongName" SG_ 2158960640 ODIIC_ODIInd51 "Open Display Interface Indication Centerstack : Open Display Interface Indication 51";
BA_ "VNSigAllNodes" SG_ 2158960640 ODIIC_ODIInd51 1;
BA_ "GenSigSendType" SG_ 2158960640 ODIIC_ODIInd50 10;
BA_ "GenSigSendOnInit" SG_ 2158960640 ODIIC_ODIInd50 1;
BA_ "VNSigInfotainment" SG_ 2158960640 ODIIC_ODIInd50 1;
BA_ "SignalType" SG_ 2158960640 ODIIC_ODIInd50 "BLN";
BA_ "PacketOrder" SG_ 2158960640 ODIIC_ODIInd50 51;
BA_ "SignalLongName" SG_ 2158960640 ODIIC_ODIInd50 "Open Display Interface Indication Centerstack : Open Display Interface Indication 50";
BA_ "VNSigAllNodes" SG_ 2158960640 ODIIC_ODIInd50 1;
BA_ "GenSigSendType" SG_ 2158960640 ODIIC_ODIInd5 10;
BA_ "GenSigSendOnInit" SG_ 2158960640 ODIIC_ODIInd5 1;
BA_ "VNSigInfotainment" SG_ 2158960640 ODIIC_ODIInd5 1;
BA_ "SignalType" SG_ 2158960640 ODIIC_ODIInd5 "BLN";
BA_ "PacketOrder" SG_ 2158960640 ODIIC_ODIInd5 6;
BA_ "SignalLongName" SG_ 2158960640 ODIIC_ODIInd5 "Open Display Interface Indication Centerstack : Open Display Interface Indication 5";
BA_ "VNSigAllNodes" SG_ 2158960640 ODIIC_ODIInd5 1;
BA_ "GenSigSendType" SG_ 2158960640 ODIIC_ODIInd49 10;
BA_ "GenSigSendOnInit" SG_ 2158960640 ODIIC_ODIInd49 1;
BA_ "VNSigInfotainment" SG_ 2158960640 ODIIC_ODIInd49 1;
BA_ "SignalType" SG_ 2158960640 ODIIC_ODIInd49 "BLN";
BA_ "PacketOrder" SG_ 2158960640 ODIIC_ODIInd49 50;
BA_ "SignalLongName" SG_ 2158960640 ODIIC_ODIInd49 "Open Display Interface Indication Centerstack : Open Display Interface Indication 49";
BA_ "VNSigAllNodes" SG_ 2158960640 ODIIC_ODIInd49 1;
BA_ "GenSigSendType" SG_ 2158960640 ODIIC_ODIInd48 10;
BA_ "GenSigSendOnInit" SG_ 2158960640 ODIIC_ODIInd48 1;
BA_ "VNSigInfotainment" SG_ 2158960640 ODIIC_ODIInd48 1;
BA_ "SignalType" SG_ 2158960640 ODIIC_ODIInd48 "BLN";
BA_ "PacketOrder" SG_ 2158960640 ODIIC_ODIInd48 49;
BA_ "SignalLongName" SG_ 2158960640 ODIIC_ODIInd48 "Open Display Interface Indication Centerstack : Open Display Interface Indication 48";
BA_ "VNSigAllNodes" SG_ 2158960640 ODIIC_ODIInd48 1;
BA_ "GenSigSendType" SG_ 2158960640 ODIIC_ODIInd47 10;
BA_ "GenSigSendOnInit" SG_ 2158960640 ODIIC_ODIInd47 1;
BA_ "VNSigInfotainment" SG_ 2158960640 ODIIC_ODIInd47 1;
BA_ "SignalType" SG_ 2158960640 ODIIC_ODIInd47 "BLN";
BA_ "PacketOrder" SG_ 2158960640 ODIIC_ODIInd47 48;
BA_ "SignalLongName" SG_ 2158960640 ODIIC_ODIInd47 "Open Display Interface Indication Centerstack : Open Display Interface Indication 47";
BA_ "VNSigAllNodes" SG_ 2158960640 ODIIC_ODIInd47 1;
BA_ "GenSigSendType" SG_ 2158960640 ODIIC_ODIInd46 10;
BA_ "GenSigSendOnInit" SG_ 2158960640 ODIIC_ODIInd46 1;
BA_ "VNSigInfotainment" SG_ 2158960640 ODIIC_ODIInd46 1;
BA_ "SignalType" SG_ 2158960640 ODIIC_ODIInd46 "BLN";
BA_ "PacketOrder" SG_ 2158960640 ODIIC_ODIInd46 47;
BA_ "SignalLongName" SG_ 2158960640 ODIIC_ODIInd46 "Open Display Interface Indication Centerstack : Open Display Interface Indication 46";
BA_ "VNSigAllNodes" SG_ 2158960640 ODIIC_ODIInd46 1;
BA_ "GenSigSendType" SG_ 2158960640 ODIIC_ODIInd45 10;
BA_ "GenSigSendOnInit" SG_ 2158960640 ODIIC_ODIInd45 1;
BA_ "VNSigInfotainment" SG_ 2158960640 ODIIC_ODIInd45 1;
BA_ "SignalType" SG_ 2158960640 ODIIC_ODIInd45 "BLN";
BA_ "PacketOrder" SG_ 2158960640 ODIIC_ODIInd45 46;
BA_ "SignalLongName" SG_ 2158960640 ODIIC_ODIInd45 "Open Display Interface Indication Centerstack : Open Display Interface Indication 45";
BA_ "VNSigAllNodes" SG_ 2158960640 ODIIC_ODIInd45 1;
BA_ "GenSigSendType" SG_ 2158960640 ODIIC_ODIInd44 10;
BA_ "GenSigSendOnInit" SG_ 2158960640 ODIIC_ODIInd44 1;
BA_ "VNSigInfotainment" SG_ 2158960640 ODIIC_ODIInd44 1;
BA_ "SignalType" SG_ 2158960640 ODIIC_ODIInd44 "BLN";
BA_ "PacketOrder" SG_ 2158960640 ODIIC_ODIInd44 45;
BA_ "SignalLongName" SG_ 2158960640 ODIIC_ODIInd44 "Open Display Interface Indication Centerstack : Open Display Interface Indication 44";
BA_ "VNSigAllNodes" SG_ 2158960640 ODIIC_ODIInd44 1;
BA_ "GenSigSendType" SG_ 2158960640 ODIIC_ODIInd43 10;
BA_ "GenSigSendOnInit" SG_ 2158960640 ODIIC_ODIInd43 1;
BA_ "VNSigInfotainment" SG_ 2158960640 ODIIC_ODIInd43 1;
BA_ "SignalType" SG_ 2158960640 ODIIC_ODIInd43 "BLN";
BA_ "PacketOrder" SG_ 2158960640 ODIIC_ODIInd43 44;
BA_ "SignalLongName" SG_ 2158960640 ODIIC_ODIInd43 "Open Display Interface Indication Centerstack : Open Display Interface Indication 43";
BA_ "VNSigAllNodes" SG_ 2158960640 ODIIC_ODIInd43 1;
BA_ "GenSigSendType" SG_ 2158960640 ODIIC_ODIInd42 10;
BA_ "GenSigSendOnInit" SG_ 2158960640 ODIIC_ODIInd42 1;
BA_ "VNSigInfotainment" SG_ 2158960640 ODIIC_ODIInd42 1;
BA_ "SignalType" SG_ 2158960640 ODIIC_ODIInd42 "BLN";
BA_ "PacketOrder" SG_ 2158960640 ODIIC_ODIInd42 43;
BA_ "SignalLongName" SG_ 2158960640 ODIIC_ODIInd42 "Open Display Interface Indication Centerstack : Open Display Interface Indication 42";
BA_ "VNSigAllNodes" SG_ 2158960640 ODIIC_ODIInd42 1;
BA_ "GenSigSendType" SG_ 2158960640 ODIIC_ODIInd41 10;
BA_ "GenSigSendOnInit" SG_ 2158960640 ODIIC_ODIInd41 1;
BA_ "VNSigInfotainment" SG_ 2158960640 ODIIC_ODIInd41 1;
BA_ "SignalType" SG_ 2158960640 ODIIC_ODIInd41 "BLN";
BA_ "PacketOrder" SG_ 2158960640 ODIIC_ODIInd41 42;
BA_ "SignalLongName" SG_ 2158960640 ODIIC_ODIInd41 "Open Display Interface Indication Centerstack : Open Display Interface Indication 41";
BA_ "VNSigAllNodes" SG_ 2158960640 ODIIC_ODIInd41 1;
BA_ "GenSigSendType" SG_ 2158960640 ODIIC_ODIInd40 10;
BA_ "GenSigSendOnInit" SG_ 2158960640 ODIIC_ODIInd40 1;
BA_ "VNSigInfotainment" SG_ 2158960640 ODIIC_ODIInd40 1;
BA_ "SignalType" SG_ 2158960640 ODIIC_ODIInd40 "BLN";
BA_ "PacketOrder" SG_ 2158960640 ODIIC_ODIInd40 41;
BA_ "SignalLongName" SG_ 2158960640 ODIIC_ODIInd40 "Open Display Interface Indication Centerstack : Open Display Interface Indication 40";
BA_ "VNSigAllNodes" SG_ 2158960640 ODIIC_ODIInd40 1;
BA_ "GenSigSendType" SG_ 2158960640 ODIIC_ODIInd4 10;
BA_ "GenSigSendOnInit" SG_ 2158960640 ODIIC_ODIInd4 1;
BA_ "VNSigInfotainment" SG_ 2158960640 ODIIC_ODIInd4 1;
BA_ "SignalType" SG_ 2158960640 ODIIC_ODIInd4 "BLN";
BA_ "PacketOrder" SG_ 2158960640 ODIIC_ODIInd4 5;
BA_ "SignalLongName" SG_ 2158960640 ODIIC_ODIInd4 "Open Display Interface Indication Centerstack : Open Display Interface Indication 4";
BA_ "VNSigAllNodes" SG_ 2158960640 ODIIC_ODIInd4 1;
BA_ "GenSigSendType" SG_ 2158960640 ODIIC_ODIInd39 10;
BA_ "GenSigSendOnInit" SG_ 2158960640 ODIIC_ODIInd39 1;
BA_ "VNSigInfotainment" SG_ 2158960640 ODIIC_ODIInd39 1;
BA_ "SignalType" SG_ 2158960640 ODIIC_ODIInd39 "BLN";
BA_ "PacketOrder" SG_ 2158960640 ODIIC_ODIInd39 40;
BA_ "SignalLongName" SG_ 2158960640 ODIIC_ODIInd39 "Open Display Interface Indication Centerstack : Open Display Interface Indication 39";
BA_ "VNSigAllNodes" SG_ 2158960640 ODIIC_ODIInd39 1;
BA_ "GenSigSendType" SG_ 2158960640 ODIIC_ODIInd38 10;
BA_ "GenSigSendOnInit" SG_ 2158960640 ODIIC_ODIInd38 1;
BA_ "VNSigInfotainment" SG_ 2158960640 ODIIC_ODIInd38 1;
BA_ "SignalType" SG_ 2158960640 ODIIC_ODIInd38 "BLN";
BA_ "PacketOrder" SG_ 2158960640 ODIIC_ODIInd38 39;
BA_ "SignalLongName" SG_ 2158960640 ODIIC_ODIInd38 "Open Display Interface Indication Centerstack : Open Display Interface Indication 38";
BA_ "VNSigAllNodes" SG_ 2158960640 ODIIC_ODIInd38 1;
BA_ "GenSigSendType" SG_ 2158960640 ODIIC_ODIInd37 10;
BA_ "GenSigSendOnInit" SG_ 2158960640 ODIIC_ODIInd37 1;
BA_ "VNSigInfotainment" SG_ 2158960640 ODIIC_ODIInd37 1;
BA_ "SignalType" SG_ 2158960640 ODIIC_ODIInd37 "BLN";
BA_ "PacketOrder" SG_ 2158960640 ODIIC_ODIInd37 38;
BA_ "SignalLongName" SG_ 2158960640 ODIIC_ODIInd37 "Open Display Interface Indication Centerstack : Open Display Interface Indication 37";
BA_ "VNSigAllNodes" SG_ 2158960640 ODIIC_ODIInd37 1;
BA_ "GenSigSendType" SG_ 2158960640 ODIIC_ODIInd36 10;
BA_ "GenSigSendOnInit" SG_ 2158960640 ODIIC_ODIInd36 1;
BA_ "VNSigInfotainment" SG_ 2158960640 ODIIC_ODIInd36 1;
BA_ "SignalType" SG_ 2158960640 ODIIC_ODIInd36 "BLN";
BA_ "PacketOrder" SG_ 2158960640 ODIIC_ODIInd36 37;
BA_ "SignalLongName" SG_ 2158960640 ODIIC_ODIInd36 "Open Display Interface Indication Centerstack : Open Display Interface Indication 36";
BA_ "VNSigAllNodes" SG_ 2158960640 ODIIC_ODIInd36 1;
BA_ "GenSigSendType" SG_ 2158960640 ODIIC_ODIInd35 10;
BA_ "GenSigSendOnInit" SG_ 2158960640 ODIIC_ODIInd35 1;
BA_ "VNSigInfotainment" SG_ 2158960640 ODIIC_ODIInd35 1;
BA_ "SignalType" SG_ 2158960640 ODIIC_ODIInd35 "BLN";
BA_ "PacketOrder" SG_ 2158960640 ODIIC_ODIInd35 36;
BA_ "SignalLongName" SG_ 2158960640 ODIIC_ODIInd35 "Open Display Interface Indication Centerstack : Open Display Interface Indication 35";
BA_ "VNSigAllNodes" SG_ 2158960640 ODIIC_ODIInd35 1;
BA_ "GenSigSendType" SG_ 2158960640 ODIIC_ODIInd34 10;
BA_ "GenSigSendOnInit" SG_ 2158960640 ODIIC_ODIInd34 1;
BA_ "VNSigInfotainment" SG_ 2158960640 ODIIC_ODIInd34 1;
BA_ "SignalType" SG_ 2158960640 ODIIC_ODIInd34 "BLN";
BA_ "PacketOrder" SG_ 2158960640 ODIIC_ODIInd34 35;
BA_ "SignalLongName" SG_ 2158960640 ODIIC_ODIInd34 "Open Display Interface Indication Centerstack : Open Display Interface Indication 34";
BA_ "VNSigAllNodes" SG_ 2158960640 ODIIC_ODIInd34 1;
BA_ "GenSigSendType" SG_ 2158960640 ODIIC_ODIInd33 10;
BA_ "GenSigSendOnInit" SG_ 2158960640 ODIIC_ODIInd33 1;
BA_ "VNSigInfotainment" SG_ 2158960640 ODIIC_ODIInd33 1;
BA_ "SignalType" SG_ 2158960640 ODIIC_ODIInd33 "BLN";
BA_ "PacketOrder" SG_ 2158960640 ODIIC_ODIInd33 34;
BA_ "SignalLongName" SG_ 2158960640 ODIIC_ODIInd33 "Open Display Interface Indication Centerstack : Open Display Interface Indication 33";
BA_ "VNSigAllNodes" SG_ 2158960640 ODIIC_ODIInd33 1;
BA_ "GenSigSendType" SG_ 2158960640 ODIIC_ODIInd32 10;
BA_ "GenSigSendOnInit" SG_ 2158960640 ODIIC_ODIInd32 1;
BA_ "VNSigInfotainment" SG_ 2158960640 ODIIC_ODIInd32 1;
BA_ "SignalType" SG_ 2158960640 ODIIC_ODIInd32 "BLN";
BA_ "PacketOrder" SG_ 2158960640 ODIIC_ODIInd32 33;
BA_ "SignalLongName" SG_ 2158960640 ODIIC_ODIInd32 "Open Display Interface Indication Centerstack : Open Display Interface Indication 32";
BA_ "VNSigAllNodes" SG_ 2158960640 ODIIC_ODIInd32 1;
BA_ "GenSigSendType" SG_ 2158960640 ODIIC_ODIInd31 10;
BA_ "GenSigSendOnInit" SG_ 2158960640 ODIIC_ODIInd31 1;
BA_ "VNSigInfotainment" SG_ 2158960640 ODIIC_ODIInd31 1;
BA_ "SignalType" SG_ 2158960640 ODIIC_ODIInd31 "BLN";
BA_ "PacketOrder" SG_ 2158960640 ODIIC_ODIInd31 32;
BA_ "SignalLongName" SG_ 2158960640 ODIIC_ODIInd31 "Open Display Interface Indication Centerstack : Open Display Interface Indication 31";
BA_ "VNSigAllNodes" SG_ 2158960640 ODIIC_ODIInd31 1;
BA_ "GenSigSendType" SG_ 2158960640 ODIIC_ODIInd30 10;
BA_ "GenSigSendOnInit" SG_ 2158960640 ODIIC_ODIInd30 1;
BA_ "VNSigInfotainment" SG_ 2158960640 ODIIC_ODIInd30 1;
BA_ "SignalType" SG_ 2158960640 ODIIC_ODIInd30 "BLN";
BA_ "PacketOrder" SG_ 2158960640 ODIIC_ODIInd30 31;
BA_ "SignalLongName" SG_ 2158960640 ODIIC_ODIInd30 "Open Display Interface Indication Centerstack : Open Display Interface Indication 30";
BA_ "VNSigAllNodes" SG_ 2158960640 ODIIC_ODIInd30 1;
BA_ "GenSigSendType" SG_ 2158960640 ODIIC_ODIInd3 10;
BA_ "GenSigSendOnInit" SG_ 2158960640 ODIIC_ODIInd3 1;
BA_ "VNSigInfotainment" SG_ 2158960640 ODIIC_ODIInd3 1;
BA_ "SignalType" SG_ 2158960640 ODIIC_ODIInd3 "BLN";
BA_ "PacketOrder" SG_ 2158960640 ODIIC_ODIInd3 4;
BA_ "SignalLongName" SG_ 2158960640 ODIIC_ODIInd3 "Open Display Interface Indication Centerstack : Open Display Interface Indication 3";
BA_ "VNSigAllNodes" SG_ 2158960640 ODIIC_ODIInd3 1;
BA_ "GenSigSendType" SG_ 2158960640 ODIIC_ODIInd29 10;
BA_ "GenSigSendOnInit" SG_ 2158960640 ODIIC_ODIInd29 1;
BA_ "VNSigInfotainment" SG_ 2158960640 ODIIC_ODIInd29 1;
BA_ "SignalType" SG_ 2158960640 ODIIC_ODIInd29 "BLN";
BA_ "PacketOrder" SG_ 2158960640 ODIIC_ODIInd29 30;
BA_ "SignalLongName" SG_ 2158960640 ODIIC_ODIInd29 "Open Display Interface Indication Centerstack : Open Display Interface Indication 29";
BA_ "VNSigAllNodes" SG_ 2158960640 ODIIC_ODIInd29 1;
BA_ "GenSigSendType" SG_ 2158960640 ODIIC_ODIInd28 10;
BA_ "GenSigSendOnInit" SG_ 2158960640 ODIIC_ODIInd28 1;
BA_ "VNSigInfotainment" SG_ 2158960640 ODIIC_ODIInd28 1;
BA_ "SignalType" SG_ 2158960640 ODIIC_ODIInd28 "BLN";
BA_ "PacketOrder" SG_ 2158960640 ODIIC_ODIInd28 29;
BA_ "SignalLongName" SG_ 2158960640 ODIIC_ODIInd28 "Open Display Interface Indication Centerstack : Open Display Interface Indication 28";
BA_ "VNSigAllNodes" SG_ 2158960640 ODIIC_ODIInd28 1;
BA_ "GenSigSendType" SG_ 2158960640 ODIIC_ODIInd27 10;
BA_ "GenSigSendOnInit" SG_ 2158960640 ODIIC_ODIInd27 1;
BA_ "VNSigInfotainment" SG_ 2158960640 ODIIC_ODIInd27 1;
BA_ "SignalType" SG_ 2158960640 ODIIC_ODIInd27 "BLN";
BA_ "PacketOrder" SG_ 2158960640 ODIIC_ODIInd27 28;
BA_ "SignalLongName" SG_ 2158960640 ODIIC_ODIInd27 "Open Display Interface Indication Centerstack : Open Display Interface Indication 27";
BA_ "VNSigAllNodes" SG_ 2158960640 ODIIC_ODIInd27 1;
BA_ "GenSigSendType" SG_ 2158960640 ODIIC_ODIInd26 10;
BA_ "GenSigSendOnInit" SG_ 2158960640 ODIIC_ODIInd26 1;
BA_ "VNSigInfotainment" SG_ 2158960640 ODIIC_ODIInd26 1;
BA_ "SignalType" SG_ 2158960640 ODIIC_ODIInd26 "BLN";
BA_ "PacketOrder" SG_ 2158960640 ODIIC_ODIInd26 27;
BA_ "SignalLongName" SG_ 2158960640 ODIIC_ODIInd26 "Open Display Interface Indication Centerstack : Open Display Interface Indication 26";
BA_ "VNSigAllNodes" SG_ 2158960640 ODIIC_ODIInd26 1;
BA_ "GenSigSendType" SG_ 2158960640 ODIIC_ODIInd25 10;
BA_ "GenSigSendOnInit" SG_ 2158960640 ODIIC_ODIInd25 1;
BA_ "VNSigInfotainment" SG_ 2158960640 ODIIC_ODIInd25 1;
BA_ "SignalType" SG_ 2158960640 ODIIC_ODIInd25 "BLN";
BA_ "PacketOrder" SG_ 2158960640 ODIIC_ODIInd25 26;
BA_ "SignalLongName" SG_ 2158960640 ODIIC_ODIInd25 "Open Display Interface Indication Centerstack : Open Display Interface Indication 25";
BA_ "VNSigAllNodes" SG_ 2158960640 ODIIC_ODIInd25 1;
BA_ "GenSigSendType" SG_ 2158960640 ODIIC_ODIInd24 10;
BA_ "GenSigSendOnInit" SG_ 2158960640 ODIIC_ODIInd24 1;
BA_ "VNSigInfotainment" SG_ 2158960640 ODIIC_ODIInd24 1;
BA_ "SignalType" SG_ 2158960640 ODIIC_ODIInd24 "BLN";
BA_ "PacketOrder" SG_ 2158960640 ODIIC_ODIInd24 25;
BA_ "SignalLongName" SG_ 2158960640 ODIIC_ODIInd24 "Open Display Interface Indication Centerstack : Open Display Interface Indication 24";
BA_ "VNSigAllNodes" SG_ 2158960640 ODIIC_ODIInd24 1;
BA_ "GenSigSendType" SG_ 2158960640 ODIIC_ODIInd23 10;
BA_ "GenSigSendOnInit" SG_ 2158960640 ODIIC_ODIInd23 1;
BA_ "VNSigInfotainment" SG_ 2158960640 ODIIC_ODIInd23 1;
BA_ "SignalType" SG_ 2158960640 ODIIC_ODIInd23 "BLN";
BA_ "PacketOrder" SG_ 2158960640 ODIIC_ODIInd23 24;
BA_ "SignalLongName" SG_ 2158960640 ODIIC_ODIInd23 "Open Display Interface Indication Centerstack : Open Display Interface Indication 23";
BA_ "VNSigAllNodes" SG_ 2158960640 ODIIC_ODIInd23 1;
BA_ "GenSigSendType" SG_ 2158960640 ODIIC_ODIInd22 10;
BA_ "GenSigSendOnInit" SG_ 2158960640 ODIIC_ODIInd22 1;
BA_ "VNSigInfotainment" SG_ 2158960640 ODIIC_ODIInd22 1;
BA_ "SignalType" SG_ 2158960640 ODIIC_ODIInd22 "BLN";
BA_ "PacketOrder" SG_ 2158960640 ODIIC_ODIInd22 23;
BA_ "SignalLongName" SG_ 2158960640 ODIIC_ODIInd22 "Open Display Interface Indication Centerstack : Open Display Interface Indication 22";
BA_ "VNSigAllNodes" SG_ 2158960640 ODIIC_ODIInd22 1;
BA_ "GenSigSendType" SG_ 2158960640 ODIIC_ODIInd21 10;
BA_ "GenSigSendOnInit" SG_ 2158960640 ODIIC_ODIInd21 1;
BA_ "VNSigInfotainment" SG_ 2158960640 ODIIC_ODIInd21 1;
BA_ "SignalType" SG_ 2158960640 ODIIC_ODIInd21 "BLN";
BA_ "PacketOrder" SG_ 2158960640 ODIIC_ODIInd21 22;
BA_ "SignalLongName" SG_ 2158960640 ODIIC_ODIInd21 "Open Display Interface Indication Centerstack : Open Display Interface Indication 21";
BA_ "VNSigAllNodes" SG_ 2158960640 ODIIC_ODIInd21 1;
BA_ "GenSigSendType" SG_ 2158960640 ODIIC_ODIInd20 10;
BA_ "GenSigSendOnInit" SG_ 2158960640 ODIIC_ODIInd20 1;
BA_ "VNSigInfotainment" SG_ 2158960640 ODIIC_ODIInd20 1;
BA_ "SignalType" SG_ 2158960640 ODIIC_ODIInd20 "BLN";
BA_ "PacketOrder" SG_ 2158960640 ODIIC_ODIInd20 21;
BA_ "SignalLongName" SG_ 2158960640 ODIIC_ODIInd20 "Open Display Interface Indication Centerstack : Open Display Interface Indication 20";
BA_ "VNSigAllNodes" SG_ 2158960640 ODIIC_ODIInd20 1;
BA_ "GenSigSendType" SG_ 2158960640 ODIIC_ODIInd2 10;
BA_ "GenSigSendOnInit" SG_ 2158960640 ODIIC_ODIInd2 1;
BA_ "VNSigInfotainment" SG_ 2158960640 ODIIC_ODIInd2 1;
BA_ "SignalType" SG_ 2158960640 ODIIC_ODIInd2 "BLN";
BA_ "PacketOrder" SG_ 2158960640 ODIIC_ODIInd2 3;
BA_ "SignalLongName" SG_ 2158960640 ODIIC_ODIInd2 "Open Display Interface Indication Centerstack : Open Display Interface Indication 2";
BA_ "VNSigAllNodes" SG_ 2158960640 ODIIC_ODIInd2 1;
BA_ "GenSigSendType" SG_ 2158960640 ODIIC_ODIInd19 10;
BA_ "GenSigSendOnInit" SG_ 2158960640 ODIIC_ODIInd19 1;
BA_ "VNSigInfotainment" SG_ 2158960640 ODIIC_ODIInd19 1;
BA_ "SignalType" SG_ 2158960640 ODIIC_ODIInd19 "BLN";
BA_ "PacketOrder" SG_ 2158960640 ODIIC_ODIInd19 20;
BA_ "SignalLongName" SG_ 2158960640 ODIIC_ODIInd19 "Open Display Interface Indication Centerstack : Open Display Interface Indication 19";
BA_ "VNSigAllNodes" SG_ 2158960640 ODIIC_ODIInd19 1;
BA_ "GenSigSendType" SG_ 2158960640 ODIIC_ODIInd18 10;
BA_ "GenSigSendOnInit" SG_ 2158960640 ODIIC_ODIInd18 1;
BA_ "VNSigInfotainment" SG_ 2158960640 ODIIC_ODIInd18 1;
BA_ "SignalType" SG_ 2158960640 ODIIC_ODIInd18 "BLN";
BA_ "PacketOrder" SG_ 2158960640 ODIIC_ODIInd18 19;
BA_ "SignalLongName" SG_ 2158960640 ODIIC_ODIInd18 "Open Display Interface Indication Centerstack : Open Display Interface Indication 18";
BA_ "VNSigAllNodes" SG_ 2158960640 ODIIC_ODIInd18 1;
BA_ "GenSigSendType" SG_ 2158960640 ODIIC_ODIInd17 10;
BA_ "GenSigSendOnInit" SG_ 2158960640 ODIIC_ODIInd17 1;
BA_ "VNSigInfotainment" SG_ 2158960640 ODIIC_ODIInd17 1;
BA_ "SignalType" SG_ 2158960640 ODIIC_ODIInd17 "BLN";
BA_ "PacketOrder" SG_ 2158960640 ODIIC_ODIInd17 18;
BA_ "SignalLongName" SG_ 2158960640 ODIIC_ODIInd17 "Open Display Interface Indication Centerstack : Open Display Interface Indication 17";
BA_ "VNSigAllNodes" SG_ 2158960640 ODIIC_ODIInd17 1;
BA_ "GenSigSendType" SG_ 2158960640 ODIIC_ODIInd16 10;
BA_ "GenSigSendOnInit" SG_ 2158960640 ODIIC_ODIInd16 1;
BA_ "VNSigInfotainment" SG_ 2158960640 ODIIC_ODIInd16 1;
BA_ "SignalType" SG_ 2158960640 ODIIC_ODIInd16 "BLN";
BA_ "PacketOrder" SG_ 2158960640 ODIIC_ODIInd16 17;
BA_ "SignalLongName" SG_ 2158960640 ODIIC_ODIInd16 "Open Display Interface Indication Centerstack : Open Display Interface Indication 16";
BA_ "VNSigAllNodes" SG_ 2158960640 ODIIC_ODIInd16 1;
BA_ "GenSigSendType" SG_ 2158960640 ODIIC_ODIInd15 10;
BA_ "GenSigSendOnInit" SG_ 2158960640 ODIIC_ODIInd15 1;
BA_ "VNSigInfotainment" SG_ 2158960640 ODIIC_ODIInd15 1;
BA_ "SignalType" SG_ 2158960640 ODIIC_ODIInd15 "BLN";
BA_ "PacketOrder" SG_ 2158960640 ODIIC_ODIInd15 16;
BA_ "SignalLongName" SG_ 2158960640 ODIIC_ODIInd15 "Open Display Interface Indication Centerstack : Open Display Interface Indication 15";
BA_ "VNSigAllNodes" SG_ 2158960640 ODIIC_ODIInd15 1;
BA_ "GenSigSendType" SG_ 2158960640 ODIIC_ODIInd14 10;
BA_ "GenSigSendOnInit" SG_ 2158960640 ODIIC_ODIInd14 1;
BA_ "VNSigInfotainment" SG_ 2158960640 ODIIC_ODIInd14 1;
BA_ "SignalType" SG_ 2158960640 ODIIC_ODIInd14 "BLN";
BA_ "PacketOrder" SG_ 2158960640 ODIIC_ODIInd14 15;
BA_ "SignalLongName" SG_ 2158960640 ODIIC_ODIInd14 "Open Display Interface Indication Centerstack : Open Display Interface Indication 14";
BA_ "VNSigAllNodes" SG_ 2158960640 ODIIC_ODIInd14 1;
BA_ "GenSigSendType" SG_ 2158960640 ODIIC_ODIInd13 10;
BA_ "GenSigSendOnInit" SG_ 2158960640 ODIIC_ODIInd13 1;
BA_ "VNSigInfotainment" SG_ 2158960640 ODIIC_ODIInd13 1;
BA_ "SignalType" SG_ 2158960640 ODIIC_ODIInd13 "BLN";
BA_ "PacketOrder" SG_ 2158960640 ODIIC_ODIInd13 14;
BA_ "SignalLongName" SG_ 2158960640 ODIIC_ODIInd13 "Open Display Interface Indication Centerstack : Open Display Interface Indication 13";
BA_ "VNSigAllNodes" SG_ 2158960640 ODIIC_ODIInd13 1;
BA_ "GenSigSendType" SG_ 2158960640 ODIIC_ODIInd12 10;
BA_ "GenSigSendOnInit" SG_ 2158960640 ODIIC_ODIInd12 1;
BA_ "VNSigInfotainment" SG_ 2158960640 ODIIC_ODIInd12 1;
BA_ "SignalType" SG_ 2158960640 ODIIC_ODIInd12 "BLN";
BA_ "PacketOrder" SG_ 2158960640 ODIIC_ODIInd12 13;
BA_ "SignalLongName" SG_ 2158960640 ODIIC_ODIInd12 "Open Display Interface Indication Centerstack : Open Display Interface Indication 12";
BA_ "VNSigAllNodes" SG_ 2158960640 ODIIC_ODIInd12 1;
BA_ "GenSigSendType" SG_ 2158960640 ODIIC_ODIInd11 10;
BA_ "GenSigSendOnInit" SG_ 2158960640 ODIIC_ODIInd11 1;
BA_ "VNSigInfotainment" SG_ 2158960640 ODIIC_ODIInd11 1;
BA_ "SignalType" SG_ 2158960640 ODIIC_ODIInd11 "BLN";
BA_ "PacketOrder" SG_ 2158960640 ODIIC_ODIInd11 12;
BA_ "SignalLongName" SG_ 2158960640 ODIIC_ODIInd11 "Open Display Interface Indication Centerstack : Open Display Interface Indication 11";
BA_ "VNSigAllNodes" SG_ 2158960640 ODIIC_ODIInd11 1;
BA_ "GenSigSendType" SG_ 2158960640 ODIIC_ODIInd10 10;
BA_ "GenSigSendOnInit" SG_ 2158960640 ODIIC_ODIInd10 1;
BA_ "VNSigInfotainment" SG_ 2158960640 ODIIC_ODIInd10 1;
BA_ "SignalType" SG_ 2158960640 ODIIC_ODIInd10 "BLN";
BA_ "PacketOrder" SG_ 2158960640 ODIIC_ODIInd10 11;
BA_ "SignalLongName" SG_ 2158960640 ODIIC_ODIInd10 "Open Display Interface Indication Centerstack : Open Display Interface Indication 10";
BA_ "VNSigAllNodes" SG_ 2158960640 ODIIC_ODIInd10 1;
BA_ "GenSigSendType" SG_ 2158960640 ODIIC_ODIInd1 10;
BA_ "GenSigSendOnInit" SG_ 2158960640 ODIIC_ODIInd1 1;
BA_ "VNSigInfotainment" SG_ 2158960640 ODIIC_ODIInd1 1;
BA_ "SignalType" SG_ 2158960640 ODIIC_ODIInd1 "BLN";
BA_ "PacketOrder" SG_ 2158960640 ODIIC_ODIInd1 2;
BA_ "SignalLongName" SG_ 2158960640 ODIIC_ODIInd1 "Open Display Interface Indication Centerstack : Open Display Interface Indication 1";
BA_ "VNSigAllNodes" SG_ 2158960640 ODIIC_ODIInd1 1;
BA_ "GenSigDeltaValue" SG_ 2158755840 ODIE_MultiFrRetCh 1;
BA_ "GenSigSendType" SG_ 2158755840 ODIE_MultiFrRetCh 12;
BA_ "VNSigInfotainment" SG_ 2158755840 ODIE_MultiFrRetCh 1;
BA_ "SignalType" SG_ 2158755840 ODIE_MultiFrRetCh "UNM";
BA_ "PacketOrder" SG_ 2158755840 ODIE_MultiFrRetCh 3;
BA_ "SignalLongName" SG_ 2158755840 ODIE_MultiFrRetCh "Open Display Interface Event Packet : MultiFrameReturnChannel";
BA_ "VNSigAllNodes" SG_ 2158755840 ODIE_MultiFrRetCh 1;
BA_ "GenSigDeltaValue" SG_ 2158755840 ODIE_FUCID 1;
BA_ "GenSigSendType" SG_ 2158755840 ODIE_FUCID 12;
BA_ "VNSigInfotainment" SG_ 2158755840 ODIE_FUCID 1;
BA_ "SignalType" SG_ 2158755840 ODIE_FUCID "UNM";
BA_ "PacketOrder" SG_ 2158755840 ODIE_FUCID 2;
BA_ "SignalLongName" SG_ 2158755840 ODIE_FUCID "Open Display Interface Event Packet : Functional Unit Class ID";
BA_ "VNSigAllNodes" SG_ 2158755840 ODIE_FUCID 1;
BA_ "GenSigDeltaValue" SG_ 2158755840 ODIE_EvID 1;
BA_ "GenSigSendType" SG_ 2158755840 ODIE_EvID 12;
BA_ "VNSigInfotainment" SG_ 2158755840 ODIE_EvID 1;
BA_ "SignalType" SG_ 2158755840 ODIE_EvID "UNM";
BA_ "PacketOrder" SG_ 2158755840 ODIE_EvID 1;
BA_ "SignalLongName" SG_ 2158755840 ODIE_EvID "Open Display Interface Event Packet : Event ID";
BA_ "VNSigAllNodes" SG_ 2158755840 ODIE_EvID 1;
BA_ "GenSigDeltaValue" SG_ 2159058944 ODIEI_MultiFrRetCh 1;
BA_ "GenSigSendType" SG_ 2159058944 ODIEI_MultiFrRetCh 12;
BA_ "VNSigInfotainment" SG_ 2159058944 ODIEI_MultiFrRetCh 1;
BA_ "SignalType" SG_ 2159058944 ODIEI_MultiFrRetCh "UNM";
BA_ "PacketOrder" SG_ 2159058944 ODIEI_MultiFrRetCh 3;
BA_ "SignalLongName" SG_ 2159058944 ODIEI_MultiFrRetCh "Open Display Interface Event Packet IPC : MultiFrameReturnChannel";
BA_ "VNSigAllNodes" SG_ 2159058944 ODIEI_MultiFrRetCh 1;
BA_ "GenSigDeltaValue" SG_ 2159058944 ODIEI_FUCID 1;
BA_ "GenSigSendType" SG_ 2159058944 ODIEI_FUCID 12;
BA_ "VNSigInfotainment" SG_ 2159058944 ODIEI_FUCID 1;
BA_ "SignalType" SG_ 2159058944 ODIEI_FUCID "UNM";
BA_ "PacketOrder" SG_ 2159058944 ODIEI_FUCID 2;
BA_ "SignalLongName" SG_ 2159058944 ODIEI_FUCID "Open Display Interface Event Packet IPC : Functional Unit Class ID";
BA_ "VNSigAllNodes" SG_ 2159058944 ODIEI_FUCID 1;
BA_ "GenSigDeltaValue" SG_ 2159058944 ODIEI_EvID 1;
BA_ "GenSigSendType" SG_ 2159058944 ODIEI_EvID 12;
BA_ "VNSigInfotainment" SG_ 2159058944 ODIEI_EvID 1;
BA_ "SignalType" SG_ 2159058944 ODIEI_EvID "UNM";
BA_ "PacketOrder" SG_ 2159058944 ODIEI_EvID 1;
BA_ "SignalLongName" SG_ 2159058944 ODIEI_EvID "Open Display Interface Event Packet IPC : Event ID";
BA_ "VNSigAllNodes" SG_ 2159058944 ODIEI_EvID 1;
BA_ "GenSigDeltaValue" SG_ 2158977024 ODIEC_MultiFrRetCh 1;
BA_ "GenSigSendType" SG_ 2158977024 ODIEC_MultiFrRetCh 12;
BA_ "VNSigInfotainment" SG_ 2158977024 ODIEC_MultiFrRetCh 1;
BA_ "SignalType" SG_ 2158977024 ODIEC_MultiFrRetCh "UNM";
BA_ "PacketOrder" SG_ 2158977024 ODIEC_MultiFrRetCh 3;
BA_ "SignalLongName" SG_ 2158977024 ODIEC_MultiFrRetCh "Open Display Interface Event Packet Centerstack : MultiFrameReturnChannel";
BA_ "VNSigAllNodes" SG_ 2158977024 ODIEC_MultiFrRetCh 1;
BA_ "GenSigDeltaValue" SG_ 2158977024 ODIEC_FUCID 1;
BA_ "GenSigSendType" SG_ 2158977024 ODIEC_FUCID 12;
BA_ "VNSigInfotainment" SG_ 2158977024 ODIEC_FUCID 1;
BA_ "SignalType" SG_ 2158977024 ODIEC_FUCID "UNM";
BA_ "PacketOrder" SG_ 2158977024 ODIEC_FUCID 2;
BA_ "SignalLongName" SG_ 2158977024 ODIEC_FUCID "Open Display Interface Event Packet Centerstack : Functional Unit Class ID";
BA_ "VNSigAllNodes" SG_ 2158977024 ODIEC_FUCID 1;
BA_ "GenSigDeltaValue" SG_ 2158977024 ODIEC_EvID 1;
BA_ "GenSigSendType" SG_ 2158977024 ODIEC_EvID 12;
BA_ "VNSigInfotainment" SG_ 2158977024 ODIEC_EvID 1;
BA_ "SignalType" SG_ 2158977024 ODIEC_EvID "UNM";
BA_ "PacketOrder" SG_ 2158977024 ODIEC_EvID 1;
BA_ "SignalLongName" SG_ 2158977024 ODIEC_EvID "Open Display Interface Event Packet Centerstack : Event ID";
BA_ "VNSigAllNodes" SG_ 2158977024 ODIEC_EvID 1;
BA_ "GenSigDeltaValue" SG_ 2158936064 ODIEDD_Data18Value 1;
BA_ "GenSigSendType" SG_ 2158936064 ODIEDD_Data18Value 12;
BA_ "GenSigSendOnInit" SG_ 2158936064 ODIEDD_Data18Value 1;
BA_ "VNSigInfotainment" SG_ 2158936064 ODIEDD_Data18Value 1;
BA_ "SignalType" SG_ 2158936064 ODIEDD_Data18Value "UNM";
BA_ "PacketOrder" SG_ 2158936064 ODIEDD_Data18Value 18;
BA_ "SignalLongName" SG_ 2158936064 ODIEDD_Data18Value "Open Display Interface Enum Dynamic Data : Data ID 18";
BA_ "VNSigAllNodes" SG_ 2158936064 ODIEDD_Data18Value 1;
BA_ "GenSigDeltaValue" SG_ 2158936064 ODIEDD_Data17Value 1;
BA_ "GenSigSendType" SG_ 2158936064 ODIEDD_Data17Value 12;
BA_ "GenSigSendOnInit" SG_ 2158936064 ODIEDD_Data17Value 1;
BA_ "VNSigInfotainment" SG_ 2158936064 ODIEDD_Data17Value 1;
BA_ "SignalType" SG_ 2158936064 ODIEDD_Data17Value "UNM";
BA_ "PacketOrder" SG_ 2158936064 ODIEDD_Data17Value 17;
BA_ "SignalLongName" SG_ 2158936064 ODIEDD_Data17Value "Open Display Interface Enum Dynamic Data : Data ID 17";
BA_ "VNSigAllNodes" SG_ 2158936064 ODIEDD_Data17Value 1;
BA_ "GenSigDeltaValue" SG_ 2158936064 ODIEDD_Data16Value 1;
BA_ "GenSigSendType" SG_ 2158936064 ODIEDD_Data16Value 12;
BA_ "GenSigSendOnInit" SG_ 2158936064 ODIEDD_Data16Value 1;
BA_ "VNSigInfotainment" SG_ 2158936064 ODIEDD_Data16Value 1;
BA_ "SignalType" SG_ 2158936064 ODIEDD_Data16Value "UNM";
BA_ "PacketOrder" SG_ 2158936064 ODIEDD_Data16Value 16;
BA_ "SignalLongName" SG_ 2158936064 ODIEDD_Data16Value "Open Display Interface Enum Dynamic Data : Data ID 16";
BA_ "VNSigAllNodes" SG_ 2158936064 ODIEDD_Data16Value 1;
BA_ "GenSigDeltaValue" SG_ 2158936064 ODIEDD_Data15Value 1;
BA_ "GenSigSendType" SG_ 2158936064 ODIEDD_Data15Value 12;
BA_ "GenSigSendOnInit" SG_ 2158936064 ODIEDD_Data15Value 1;
BA_ "VNSigInfotainment" SG_ 2158936064 ODIEDD_Data15Value 1;
BA_ "SignalType" SG_ 2158936064 ODIEDD_Data15Value "UNM";
BA_ "PacketOrder" SG_ 2158936064 ODIEDD_Data15Value 15;
BA_ "SignalLongName" SG_ 2158936064 ODIEDD_Data15Value "Open Display Interface Enum Dynamic Data : Data ID 15";
BA_ "VNSigAllNodes" SG_ 2158936064 ODIEDD_Data15Value 1;
BA_ "GenSigDeltaValue" SG_ 2158936064 ODIEDD_Data14Value 1;
BA_ "GenSigSendType" SG_ 2158936064 ODIEDD_Data14Value 12;
BA_ "GenSigSendOnInit" SG_ 2158936064 ODIEDD_Data14Value 1;
BA_ "VNSigInfotainment" SG_ 2158936064 ODIEDD_Data14Value 1;
BA_ "SignalType" SG_ 2158936064 ODIEDD_Data14Value "UNM";
BA_ "PacketOrder" SG_ 2158936064 ODIEDD_Data14Value 14;
BA_ "SignalLongName" SG_ 2158936064 ODIEDD_Data14Value "Open Display Interface Enum Dynamic Data : Data ID 14";
BA_ "VNSigAllNodes" SG_ 2158936064 ODIEDD_Data14Value 1;
BA_ "GenSigDeltaValue" SG_ 2158936064 ODIEDD_Data13Value 1;
BA_ "GenSigSendType" SG_ 2158936064 ODIEDD_Data13Value 12;
BA_ "GenSigSendOnInit" SG_ 2158936064 ODIEDD_Data13Value 1;
BA_ "VNSigInfotainment" SG_ 2158936064 ODIEDD_Data13Value 1;
BA_ "SignalType" SG_ 2158936064 ODIEDD_Data13Value "UNM";
BA_ "PacketOrder" SG_ 2158936064 ODIEDD_Data13Value 13;
BA_ "SignalLongName" SG_ 2158936064 ODIEDD_Data13Value "Open Display Interface Enum Dynamic Data : Data ID 13";
BA_ "VNSigAllNodes" SG_ 2158936064 ODIEDD_Data13Value 1;
BA_ "GenSigDeltaValue" SG_ 2158936064 ODIEDD_Data12Value 1;
BA_ "GenSigSendType" SG_ 2158936064 ODIEDD_Data12Value 12;
BA_ "GenSigSendOnInit" SG_ 2158936064 ODIEDD_Data12Value 1;
BA_ "VNSigInfotainment" SG_ 2158936064 ODIEDD_Data12Value 1;
BA_ "SignalType" SG_ 2158936064 ODIEDD_Data12Value "UNM";
BA_ "PacketOrder" SG_ 2158936064 ODIEDD_Data12Value 12;
BA_ "SignalLongName" SG_ 2158936064 ODIEDD_Data12Value "Open Display Interface Enum Dynamic Data : Data ID 12";
BA_ "VNSigAllNodes" SG_ 2158936064 ODIEDD_Data12Value 1;
BA_ "GenSigDeltaValue" SG_ 2158936064 ODIEDD_Data11Value 1;
BA_ "GenSigSendType" SG_ 2158936064 ODIEDD_Data11Value 12;
BA_ "GenSigSendOnInit" SG_ 2158936064 ODIEDD_Data11Value 1;
BA_ "VNSigInfotainment" SG_ 2158936064 ODIEDD_Data11Value 1;
BA_ "SignalType" SG_ 2158936064 ODIEDD_Data11Value "UNM";
BA_ "PacketOrder" SG_ 2158936064 ODIEDD_Data11Value 11;
BA_ "SignalLongName" SG_ 2158936064 ODIEDD_Data11Value "Open Display Interface Enum Dynamic Data : Data ID 11";
BA_ "VNSigAllNodes" SG_ 2158936064 ODIEDD_Data11Value 1;
BA_ "GenSigDeltaValue" SG_ 2158936064 ODIEDD_Data10Value 1;
BA_ "GenSigSendType" SG_ 2158936064 ODIEDD_Data10Value 12;
BA_ "GenSigSendOnInit" SG_ 2158936064 ODIEDD_Data10Value 1;
BA_ "VNSigInfotainment" SG_ 2158936064 ODIEDD_Data10Value 1;
BA_ "SignalType" SG_ 2158936064 ODIEDD_Data10Value "UNM";
BA_ "PacketOrder" SG_ 2158936064 ODIEDD_Data10Value 10;
BA_ "SignalLongName" SG_ 2158936064 ODIEDD_Data10Value "Open Display Interface Enum Dynamic Data : Data ID 10";
BA_ "VNSigAllNodes" SG_ 2158936064 ODIEDD_Data10Value 1;
BA_ "GenSigDeltaValue" SG_ 2158936064 ODIEDD_Data9Value 1;
BA_ "GenSigSendType" SG_ 2158936064 ODIEDD_Data9Value 12;
BA_ "GenSigSendOnInit" SG_ 2158936064 ODIEDD_Data9Value 1;
BA_ "VNSigInfotainment" SG_ 2158936064 ODIEDD_Data9Value 1;
BA_ "SignalType" SG_ 2158936064 ODIEDD_Data9Value "UNM";
BA_ "PacketOrder" SG_ 2158936064 ODIEDD_Data9Value 9;
BA_ "SignalLongName" SG_ 2158936064 ODIEDD_Data9Value "Open Display Interface Enum Dynamic Data : Data ID 9";
BA_ "VNSigAllNodes" SG_ 2158936064 ODIEDD_Data9Value 1;
BA_ "GenSigDeltaValue" SG_ 2158936064 ODIEDD_Data8Value 1;
BA_ "GenSigSendType" SG_ 2158936064 ODIEDD_Data8Value 12;
BA_ "GenSigSendOnInit" SG_ 2158936064 ODIEDD_Data8Value 1;
BA_ "VNSigInfotainment" SG_ 2158936064 ODIEDD_Data8Value 1;
BA_ "SignalType" SG_ 2158936064 ODIEDD_Data8Value "UNM";
BA_ "PacketOrder" SG_ 2158936064 ODIEDD_Data8Value 8;
BA_ "SignalLongName" SG_ 2158936064 ODIEDD_Data8Value "Open Display Interface Enum Dynamic Data : Data ID 8";
BA_ "VNSigAllNodes" SG_ 2158936064 ODIEDD_Data8Value 1;
BA_ "GenSigDeltaValue" SG_ 2158936064 ODIEDD_Data7Value 1;
BA_ "GenSigSendType" SG_ 2158936064 ODIEDD_Data7Value 12;
BA_ "GenSigSendOnInit" SG_ 2158936064 ODIEDD_Data7Value 1;
BA_ "VNSigInfotainment" SG_ 2158936064 ODIEDD_Data7Value 1;
BA_ "SignalType" SG_ 2158936064 ODIEDD_Data7Value "UNM";
BA_ "PacketOrder" SG_ 2158936064 ODIEDD_Data7Value 7;
BA_ "SignalLongName" SG_ 2158936064 ODIEDD_Data7Value "Open Display Interface Enum Dynamic Data : Data ID 7";
BA_ "VNSigAllNodes" SG_ 2158936064 ODIEDD_Data7Value 1;
BA_ "GenSigDeltaValue" SG_ 2158936064 ODIEDD_Data6Value 1;
BA_ "GenSigSendType" SG_ 2158936064 ODIEDD_Data6Value 12;
BA_ "GenSigSendOnInit" SG_ 2158936064 ODIEDD_Data6Value 1;
BA_ "VNSigInfotainment" SG_ 2158936064 ODIEDD_Data6Value 1;
BA_ "SignalType" SG_ 2158936064 ODIEDD_Data6Value "UNM";
BA_ "PacketOrder" SG_ 2158936064 ODIEDD_Data6Value 6;
BA_ "SignalLongName" SG_ 2158936064 ODIEDD_Data6Value "Open Display Interface Enum Dynamic Data : Data ID 6";
BA_ "VNSigAllNodes" SG_ 2158936064 ODIEDD_Data6Value 1;
BA_ "GenSigDeltaValue" SG_ 2158936064 ODIEDD_Data5Value 1;
BA_ "GenSigSendType" SG_ 2158936064 ODIEDD_Data5Value 12;
BA_ "GenSigSendOnInit" SG_ 2158936064 ODIEDD_Data5Value 1;
BA_ "VNSigInfotainment" SG_ 2158936064 ODIEDD_Data5Value 1;
BA_ "SignalType" SG_ 2158936064 ODIEDD_Data5Value "UNM";
BA_ "PacketOrder" SG_ 2158936064 ODIEDD_Data5Value 5;
BA_ "SignalLongName" SG_ 2158936064 ODIEDD_Data5Value "Open Display Interface Enum Dynamic Data : Data ID 5";
BA_ "VNSigAllNodes" SG_ 2158936064 ODIEDD_Data5Value 1;
BA_ "GenSigDeltaValue" SG_ 2158936064 ODIEDD_Data4Value 1;
BA_ "GenSigSendType" SG_ 2158936064 ODIEDD_Data4Value 12;
BA_ "GenSigSendOnInit" SG_ 2158936064 ODIEDD_Data4Value 1;
BA_ "VNSigInfotainment" SG_ 2158936064 ODIEDD_Data4Value 1;
BA_ "SignalType" SG_ 2158936064 ODIEDD_Data4Value "UNM";
BA_ "PacketOrder" SG_ 2158936064 ODIEDD_Data4Value 4;
BA_ "SignalLongName" SG_ 2158936064 ODIEDD_Data4Value "Open Display Interface Enum Dynamic Data : Data ID 4";
BA_ "VNSigAllNodes" SG_ 2158936064 ODIEDD_Data4Value 1;
BA_ "GenSigDeltaValue" SG_ 2158936064 ODIEDD_Data3Value 1;
BA_ "GenSigSendType" SG_ 2158936064 ODIEDD_Data3Value 12;
BA_ "GenSigSendOnInit" SG_ 2158936064 ODIEDD_Data3Value 1;
BA_ "VNSigInfotainment" SG_ 2158936064 ODIEDD_Data3Value 1;
BA_ "SignalType" SG_ 2158936064 ODIEDD_Data3Value "UNM";
BA_ "PacketOrder" SG_ 2158936064 ODIEDD_Data3Value 3;
BA_ "SignalLongName" SG_ 2158936064 ODIEDD_Data3Value "Open Display Interface Enum Dynamic Data : Data ID 3";
BA_ "VNSigAllNodes" SG_ 2158936064 ODIEDD_Data3Value 1;
BA_ "GenSigDeltaValue" SG_ 2158936064 ODIEDD_Data2Value 1;
BA_ "GenSigSendType" SG_ 2158936064 ODIEDD_Data2Value 12;
BA_ "GenSigSendOnInit" SG_ 2158936064 ODIEDD_Data2Value 1;
BA_ "VNSigInfotainment" SG_ 2158936064 ODIEDD_Data2Value 1;
BA_ "SignalType" SG_ 2158936064 ODIEDD_Data2Value "UNM";
BA_ "PacketOrder" SG_ 2158936064 ODIEDD_Data2Value 2;
BA_ "SignalLongName" SG_ 2158936064 ODIEDD_Data2Value "Open Display Interface Enum Dynamic Data : Data ID 2";
BA_ "VNSigAllNodes" SG_ 2158936064 ODIEDD_Data2Value 1;
BA_ "GenSigDeltaValue" SG_ 2158936064 ODIEDD_Data1Value 1;
BA_ "GenSigSendType" SG_ 2158936064 ODIEDD_Data1Value 12;
BA_ "GenSigSendOnInit" SG_ 2158936064 ODIEDD_Data1Value 1;
BA_ "VNSigInfotainment" SG_ 2158936064 ODIEDD_Data1Value 1;
BA_ "SignalType" SG_ 2158936064 ODIEDD_Data1Value "UNM";
BA_ "PacketOrder" SG_ 2158936064 ODIEDD_Data1Value 1;
BA_ "SignalLongName" SG_ 2158936064 ODIEDD_Data1Value "Open Display Interface Enum Dynamic Data : Data ID 1";
BA_ "VNSigAllNodes" SG_ 2158936064 ODIEDD_Data1Value 1;
BA_ "GenSigDeltaValue" SG_ 2158936064 ODIEDD_FUCID 1;
BA_ "GenSigSendType" SG_ 2158936064 ODIEDD_FUCID 12;
BA_ "GenSigSendOnInit" SG_ 2158936064 ODIEDD_FUCID 1;
BA_ "VNSigInfotainment" SG_ 2158936064 ODIEDD_FUCID 1;
BA_ "SignalType" SG_ 2158936064 ODIEDD_FUCID "UNM";
BA_ "PacketOrder" SG_ 2158936064 ODIEDD_FUCID 19;
BA_ "SignalLongName" SG_ 2158936064 ODIEDD_FUCID "Open Display Interface Enum Dynamic Data : Functional Unit Class ID";
BA_ "VNSigAllNodes" SG_ 2158936064 ODIEDD_FUCID 1;
BA_ "GenSigDeltaValue" SG_ 2159001600 ODIEDDIPC_FUCID 1;
BA_ "GenSigSendType" SG_ 2159001600 ODIEDDIPC_FUCID 12;
BA_ "VNSigInfotainment" SG_ 2159001600 ODIEDDIPC_FUCID 1;
BA_ "SignalType" SG_ 2159001600 ODIEDDIPC_FUCID "UNM";
BA_ "PacketOrder" SG_ 2159001600 ODIEDDIPC_FUCID 19;
BA_ "SignalLongName" SG_ 2159001600 ODIEDDIPC_FUCID "Open Display Interface Enum Dynamic Data : Functional Unit Class ID";
BA_ "VNSigAllNodes" SG_ 2159001600 ODIEDDIPC_FUCID 1;
BA_ "GenSigDeltaValue" SG_ 2159001600 ODIEDDIPC_Data18Value 1;
BA_ "GenSigSendType" SG_ 2159001600 ODIEDDIPC_Data18Value 12;
BA_ "VNSigInfotainment" SG_ 2159001600 ODIEDDIPC_Data18Value 1;
BA_ "SignalType" SG_ 2159001600 ODIEDDIPC_Data18Value "UNM";
BA_ "PacketOrder" SG_ 2159001600 ODIEDDIPC_Data18Value 18;
BA_ "SignalLongName" SG_ 2159001600 ODIEDDIPC_Data18Value "Open Display Interface Enum Dynamic Data : Data ID 18";
BA_ "VNSigAllNodes" SG_ 2159001600 ODIEDDIPC_Data18Value 1;
BA_ "GenSigDeltaValue" SG_ 2159001600 ODIEDDIPC_Data17Value 1;
BA_ "GenSigSendType" SG_ 2159001600 ODIEDDIPC_Data17Value 12;
BA_ "VNSigInfotainment" SG_ 2159001600 ODIEDDIPC_Data17Value 1;
BA_ "SignalType" SG_ 2159001600 ODIEDDIPC_Data17Value "UNM";
BA_ "PacketOrder" SG_ 2159001600 ODIEDDIPC_Data17Value 17;
BA_ "SignalLongName" SG_ 2159001600 ODIEDDIPC_Data17Value "Open Display Interface Enum Dynamic Data : Data ID 17";
BA_ "VNSigAllNodes" SG_ 2159001600 ODIEDDIPC_Data17Value 1;
BA_ "GenSigDeltaValue" SG_ 2159001600 ODIEDDIPC_Data16Value 1;
BA_ "GenSigSendType" SG_ 2159001600 ODIEDDIPC_Data16Value 12;
BA_ "VNSigInfotainment" SG_ 2159001600 ODIEDDIPC_Data16Value 1;
BA_ "SignalType" SG_ 2159001600 ODIEDDIPC_Data16Value "UNM";
BA_ "PacketOrder" SG_ 2159001600 ODIEDDIPC_Data16Value 16;
BA_ "SignalLongName" SG_ 2159001600 ODIEDDIPC_Data16Value "Open Display Interface Enum Dynamic Data : Data ID 16";
BA_ "VNSigAllNodes" SG_ 2159001600 ODIEDDIPC_Data16Value 1;
BA_ "GenSigDeltaValue" SG_ 2159001600 ODIEDDIPC_Data15Value 1;
BA_ "GenSigSendType" SG_ 2159001600 ODIEDDIPC_Data15Value 12;
BA_ "VNSigInfotainment" SG_ 2159001600 ODIEDDIPC_Data15Value 1;
BA_ "SignalType" SG_ 2159001600 ODIEDDIPC_Data15Value "UNM";
BA_ "PacketOrder" SG_ 2159001600 ODIEDDIPC_Data15Value 15;
BA_ "SignalLongName" SG_ 2159001600 ODIEDDIPC_Data15Value "Open Display Interface Enum Dynamic Data : Data ID 15";
BA_ "VNSigAllNodes" SG_ 2159001600 ODIEDDIPC_Data15Value 1;
BA_ "GenSigDeltaValue" SG_ 2159001600 ODIEDDIPC_Data14Value 1;
BA_ "GenSigSendType" SG_ 2159001600 ODIEDDIPC_Data14Value 12;
BA_ "VNSigInfotainment" SG_ 2159001600 ODIEDDIPC_Data14Value 1;
BA_ "SignalType" SG_ 2159001600 ODIEDDIPC_Data14Value "UNM";
BA_ "PacketOrder" SG_ 2159001600 ODIEDDIPC_Data14Value 14;
BA_ "SignalLongName" SG_ 2159001600 ODIEDDIPC_Data14Value "Open Display Interface Enum Dynamic Data : Data ID 14";
BA_ "VNSigAllNodes" SG_ 2159001600 ODIEDDIPC_Data14Value 1;
BA_ "GenSigDeltaValue" SG_ 2159001600 ODIEDDIPC_Data13Value 1;
BA_ "GenSigSendType" SG_ 2159001600 ODIEDDIPC_Data13Value 12;
BA_ "VNSigInfotainment" SG_ 2159001600 ODIEDDIPC_Data13Value 1;
BA_ "SignalType" SG_ 2159001600 ODIEDDIPC_Data13Value "UNM";
BA_ "PacketOrder" SG_ 2159001600 ODIEDDIPC_Data13Value 13;
BA_ "SignalLongName" SG_ 2159001600 ODIEDDIPC_Data13Value "Open Display Interface Enum Dynamic Data : Data ID 13";
BA_ "VNSigAllNodes" SG_ 2159001600 ODIEDDIPC_Data13Value 1;
BA_ "GenSigDeltaValue" SG_ 2159001600 ODIEDDIPC_Data12Value 1;
BA_ "GenSigSendType" SG_ 2159001600 ODIEDDIPC_Data12Value 12;
BA_ "VNSigInfotainment" SG_ 2159001600 ODIEDDIPC_Data12Value 1;
BA_ "SignalType" SG_ 2159001600 ODIEDDIPC_Data12Value "UNM";
BA_ "PacketOrder" SG_ 2159001600 ODIEDDIPC_Data12Value 12;
BA_ "SignalLongName" SG_ 2159001600 ODIEDDIPC_Data12Value "Open Display Interface Enum Dynamic Data : Data ID 12";
BA_ "VNSigAllNodes" SG_ 2159001600 ODIEDDIPC_Data12Value 1;
BA_ "GenSigDeltaValue" SG_ 2159001600 ODIEDDIPC_Data11Value 1;
BA_ "GenSigSendType" SG_ 2159001600 ODIEDDIPC_Data11Value 12;
BA_ "VNSigInfotainment" SG_ 2159001600 ODIEDDIPC_Data11Value 1;
BA_ "SignalType" SG_ 2159001600 ODIEDDIPC_Data11Value "UNM";
BA_ "PacketOrder" SG_ 2159001600 ODIEDDIPC_Data11Value 11;
BA_ "SignalLongName" SG_ 2159001600 ODIEDDIPC_Data11Value "Open Display Interface Enum Dynamic Data : Data ID 11";
BA_ "VNSigAllNodes" SG_ 2159001600 ODIEDDIPC_Data11Value 1;
BA_ "GenSigDeltaValue" SG_ 2159001600 ODIEDDIPC_Data10Value 1;
BA_ "GenSigSendType" SG_ 2159001600 ODIEDDIPC_Data10Value 12;
BA_ "VNSigInfotainment" SG_ 2159001600 ODIEDDIPC_Data10Value 1;
BA_ "SignalType" SG_ 2159001600 ODIEDDIPC_Data10Value "UNM";
BA_ "PacketOrder" SG_ 2159001600 ODIEDDIPC_Data10Value 10;
BA_ "SignalLongName" SG_ 2159001600 ODIEDDIPC_Data10Value "Open Display Interface Enum Dynamic Data : Data ID 10";
BA_ "VNSigAllNodes" SG_ 2159001600 ODIEDDIPC_Data10Value 1;
BA_ "GenSigDeltaValue" SG_ 2159001600 ODIEDDIPC_Data9Value 1;
BA_ "GenSigSendType" SG_ 2159001600 ODIEDDIPC_Data9Value 12;
BA_ "VNSigInfotainment" SG_ 2159001600 ODIEDDIPC_Data9Value 1;
BA_ "SignalType" SG_ 2159001600 ODIEDDIPC_Data9Value "UNM";
BA_ "PacketOrder" SG_ 2159001600 ODIEDDIPC_Data9Value 9;
BA_ "SignalLongName" SG_ 2159001600 ODIEDDIPC_Data9Value "Open Display Interface Enum Dynamic Data : Data ID 9";
BA_ "VNSigAllNodes" SG_ 2159001600 ODIEDDIPC_Data9Value 1;
BA_ "GenSigDeltaValue" SG_ 2159001600 ODIEDDIPC_Data8Value 1;
BA_ "GenSigSendType" SG_ 2159001600 ODIEDDIPC_Data8Value 12;
BA_ "VNSigInfotainment" SG_ 2159001600 ODIEDDIPC_Data8Value 1;
BA_ "SignalType" SG_ 2159001600 ODIEDDIPC_Data8Value "UNM";
BA_ "PacketOrder" SG_ 2159001600 ODIEDDIPC_Data8Value 8;
BA_ "SignalLongName" SG_ 2159001600 ODIEDDIPC_Data8Value "Open Display Interface Enum Dynamic Data : Data ID 8";
BA_ "VNSigAllNodes" SG_ 2159001600 ODIEDDIPC_Data8Value 1;
BA_ "GenSigDeltaValue" SG_ 2159001600 ODIEDDIPC_Data7Value 1;
BA_ "GenSigSendType" SG_ 2159001600 ODIEDDIPC_Data7Value 12;
BA_ "VNSigInfotainment" SG_ 2159001600 ODIEDDIPC_Data7Value 1;
BA_ "SignalType" SG_ 2159001600 ODIEDDIPC_Data7Value "UNM";
BA_ "PacketOrder" SG_ 2159001600 ODIEDDIPC_Data7Value 7;
BA_ "SignalLongName" SG_ 2159001600 ODIEDDIPC_Data7Value "Open Display Interface Enum Dynamic Data : Data ID 7";
BA_ "VNSigAllNodes" SG_ 2159001600 ODIEDDIPC_Data7Value 1;
BA_ "GenSigDeltaValue" SG_ 2159001600 ODIEDDIPC_Data6Value 1;
BA_ "GenSigSendType" SG_ 2159001600 ODIEDDIPC_Data6Value 12;
BA_ "VNSigInfotainment" SG_ 2159001600 ODIEDDIPC_Data6Value 1;
BA_ "SignalType" SG_ 2159001600 ODIEDDIPC_Data6Value "UNM";
BA_ "PacketOrder" SG_ 2159001600 ODIEDDIPC_Data6Value 6;
BA_ "SignalLongName" SG_ 2159001600 ODIEDDIPC_Data6Value "Open Display Interface Enum Dynamic Data : Data ID 6";
BA_ "VNSigAllNodes" SG_ 2159001600 ODIEDDIPC_Data6Value 1;
BA_ "GenSigDeltaValue" SG_ 2159001600 ODIEDDIPC_Data5Value 1;
BA_ "GenSigSendType" SG_ 2159001600 ODIEDDIPC_Data5Value 12;
BA_ "VNSigInfotainment" SG_ 2159001600 ODIEDDIPC_Data5Value 1;
BA_ "SignalType" SG_ 2159001600 ODIEDDIPC_Data5Value "UNM";
BA_ "PacketOrder" SG_ 2159001600 ODIEDDIPC_Data5Value 5;
BA_ "SignalLongName" SG_ 2159001600 ODIEDDIPC_Data5Value "Open Display Interface Enum Dynamic Data : Data ID 5";
BA_ "VNSigAllNodes" SG_ 2159001600 ODIEDDIPC_Data5Value 1;
BA_ "GenSigDeltaValue" SG_ 2159001600 ODIEDDIPC_Data4Value 1;
BA_ "GenSigSendType" SG_ 2159001600 ODIEDDIPC_Data4Value 12;
BA_ "VNSigInfotainment" SG_ 2159001600 ODIEDDIPC_Data4Value 1;
BA_ "SignalType" SG_ 2159001600 ODIEDDIPC_Data4Value "UNM";
BA_ "PacketOrder" SG_ 2159001600 ODIEDDIPC_Data4Value 4;
BA_ "SignalLongName" SG_ 2159001600 ODIEDDIPC_Data4Value "Open Display Interface Enum Dynamic Data : Data ID 4";
BA_ "VNSigAllNodes" SG_ 2159001600 ODIEDDIPC_Data4Value 1;
BA_ "GenSigDeltaValue" SG_ 2159001600 ODIEDDIPC_Data3Value 1;
BA_ "GenSigSendType" SG_ 2159001600 ODIEDDIPC_Data3Value 12;
BA_ "VNSigInfotainment" SG_ 2159001600 ODIEDDIPC_Data3Value 1;
BA_ "SignalType" SG_ 2159001600 ODIEDDIPC_Data3Value "UNM";
BA_ "PacketOrder" SG_ 2159001600 ODIEDDIPC_Data3Value 3;
BA_ "SignalLongName" SG_ 2159001600 ODIEDDIPC_Data3Value "Open Display Interface Enum Dynamic Data : Data ID 3";
BA_ "VNSigAllNodes" SG_ 2159001600 ODIEDDIPC_Data3Value 1;
BA_ "GenSigDeltaValue" SG_ 2159001600 ODIEDDIPC_Data2Value 1;
BA_ "GenSigSendType" SG_ 2159001600 ODIEDDIPC_Data2Value 12;
BA_ "VNSigInfotainment" SG_ 2159001600 ODIEDDIPC_Data2Value 1;
BA_ "SignalType" SG_ 2159001600 ODIEDDIPC_Data2Value "UNM";
BA_ "PacketOrder" SG_ 2159001600 ODIEDDIPC_Data2Value 2;
BA_ "SignalLongName" SG_ 2159001600 ODIEDDIPC_Data2Value "Open Display Interface Enum Dynamic Data : Data ID 2";
BA_ "VNSigAllNodes" SG_ 2159001600 ODIEDDIPC_Data2Value 1;
BA_ "GenSigDeltaValue" SG_ 2159001600 ODIEDDIPC_Data1Value 1;
BA_ "GenSigSendType" SG_ 2159001600 ODIEDDIPC_Data1Value 12;
BA_ "VNSigInfotainment" SG_ 2159001600 ODIEDDIPC_Data1Value 1;
BA_ "SignalType" SG_ 2159001600 ODIEDDIPC_Data1Value "UNM";
BA_ "PacketOrder" SG_ 2159001600 ODIEDDIPC_Data1Value 1;
BA_ "SignalLongName" SG_ 2159001600 ODIEDDIPC_Data1Value "Open Display Interface Enum Dynamic Data : Data ID 1";
BA_ "VNSigAllNodes" SG_ 2159001600 ODIEDDIPC_Data1Value 1;
BA_ "GenSigDeltaValue" SG_ 2158993408 ODIEDDCS_FUCID 1;
BA_ "GenSigSendType" SG_ 2158993408 ODIEDDCS_FUCID 12;
BA_ "GenSigSendOnInit" SG_ 2158993408 ODIEDDCS_FUCID 1;
BA_ "VNSigInfotainment" SG_ 2158993408 ODIEDDCS_FUCID 1;
BA_ "SignalType" SG_ 2158993408 ODIEDDCS_FUCID "UNM";
BA_ "PacketOrder" SG_ 2158993408 ODIEDDCS_FUCID 19;
BA_ "SignalLongName" SG_ 2158993408 ODIEDDCS_FUCID "Open Display Interface Enum Dynamic Data : Functional Unit Class ID";
BA_ "VNSigAllNodes" SG_ 2158993408 ODIEDDCS_FUCID 1;
BA_ "GenSigDeltaValue" SG_ 2158993408 ODIEDDCS_Data9Value 1;
BA_ "GenSigSendType" SG_ 2158993408 ODIEDDCS_Data9Value 12;
BA_ "GenSigSendOnInit" SG_ 2158993408 ODIEDDCS_Data9Value 1;
BA_ "VNSigInfotainment" SG_ 2158993408 ODIEDDCS_Data9Value 1;
BA_ "SignalType" SG_ 2158993408 ODIEDDCS_Data9Value "UNM";
BA_ "PacketOrder" SG_ 2158993408 ODIEDDCS_Data9Value 9;
BA_ "SignalLongName" SG_ 2158993408 ODIEDDCS_Data9Value "Open Display Interface Enum Dynamic Data : Data ID 9";
BA_ "VNSigAllNodes" SG_ 2158993408 ODIEDDCS_Data9Value 1;
BA_ "GenSigDeltaValue" SG_ 2158993408 ODIEDDCS_Data8Value 1;
BA_ "GenSigSendType" SG_ 2158993408 ODIEDDCS_Data8Value 12;
BA_ "GenSigSendOnInit" SG_ 2158993408 ODIEDDCS_Data8Value 1;
BA_ "VNSigInfotainment" SG_ 2158993408 ODIEDDCS_Data8Value 1;
BA_ "SignalType" SG_ 2158993408 ODIEDDCS_Data8Value "UNM";
BA_ "PacketOrder" SG_ 2158993408 ODIEDDCS_Data8Value 8;
BA_ "SignalLongName" SG_ 2158993408 ODIEDDCS_Data8Value "Open Display Interface Enum Dynamic Data : Data ID 8";
BA_ "VNSigAllNodes" SG_ 2158993408 ODIEDDCS_Data8Value 1;
BA_ "GenSigDeltaValue" SG_ 2158993408 ODIEDDCS_Data7Value 1;
BA_ "GenSigSendType" SG_ 2158993408 ODIEDDCS_Data7Value 12;
BA_ "GenSigSendOnInit" SG_ 2158993408 ODIEDDCS_Data7Value 1;
BA_ "VNSigInfotainment" SG_ 2158993408 ODIEDDCS_Data7Value 1;
BA_ "SignalType" SG_ 2158993408 ODIEDDCS_Data7Value "UNM";
BA_ "PacketOrder" SG_ 2158993408 ODIEDDCS_Data7Value 7;
BA_ "SignalLongName" SG_ 2158993408 ODIEDDCS_Data7Value "Open Display Interface Enum Dynamic Data : Data ID 7";
BA_ "VNSigAllNodes" SG_ 2158993408 ODIEDDCS_Data7Value 1;
BA_ "GenSigDeltaValue" SG_ 2158993408 ODIEDDCS_Data6Value 1;
BA_ "GenSigSendType" SG_ 2158993408 ODIEDDCS_Data6Value 12;
BA_ "GenSigSendOnInit" SG_ 2158993408 ODIEDDCS_Data6Value 1;
BA_ "VNSigInfotainment" SG_ 2158993408 ODIEDDCS_Data6Value 1;
BA_ "SignalType" SG_ 2158993408 ODIEDDCS_Data6Value "UNM";
BA_ "PacketOrder" SG_ 2158993408 ODIEDDCS_Data6Value 6;
BA_ "SignalLongName" SG_ 2158993408 ODIEDDCS_Data6Value "Open Display Interface Enum Dynamic Data : Data ID 6";
BA_ "VNSigAllNodes" SG_ 2158993408 ODIEDDCS_Data6Value 1;
BA_ "GenSigDeltaValue" SG_ 2158993408 ODIEDDCS_Data5Value 1;
BA_ "GenSigSendType" SG_ 2158993408 ODIEDDCS_Data5Value 12;
BA_ "GenSigSendOnInit" SG_ 2158993408 ODIEDDCS_Data5Value 1;
BA_ "VNSigInfotainment" SG_ 2158993408 ODIEDDCS_Data5Value 1;
BA_ "SignalType" SG_ 2158993408 ODIEDDCS_Data5Value "UNM";
BA_ "PacketOrder" SG_ 2158993408 ODIEDDCS_Data5Value 5;
BA_ "SignalLongName" SG_ 2158993408 ODIEDDCS_Data5Value "Open Display Interface Enum Dynamic Data : Data ID 5";
BA_ "VNSigAllNodes" SG_ 2158993408 ODIEDDCS_Data5Value 1;
BA_ "GenSigDeltaValue" SG_ 2158993408 ODIEDDCS_Data4Value 1;
BA_ "GenSigSendType" SG_ 2158993408 ODIEDDCS_Data4Value 12;
BA_ "GenSigSendOnInit" SG_ 2158993408 ODIEDDCS_Data4Value 1;
BA_ "VNSigInfotainment" SG_ 2158993408 ODIEDDCS_Data4Value 1;
BA_ "SignalType" SG_ 2158993408 ODIEDDCS_Data4Value "UNM";
BA_ "PacketOrder" SG_ 2158993408 ODIEDDCS_Data4Value 4;
BA_ "SignalLongName" SG_ 2158993408 ODIEDDCS_Data4Value "Open Display Interface Enum Dynamic Data : Data ID 4";
BA_ "VNSigAllNodes" SG_ 2158993408 ODIEDDCS_Data4Value 1;
BA_ "GenSigDeltaValue" SG_ 2158993408 ODIEDDCS_Data3Value 1;
BA_ "GenSigSendType" SG_ 2158993408 ODIEDDCS_Data3Value 12;
BA_ "GenSigSendOnInit" SG_ 2158993408 ODIEDDCS_Data3Value 1;
BA_ "VNSigInfotainment" SG_ 2158993408 ODIEDDCS_Data3Value 1;
BA_ "SignalType" SG_ 2158993408 ODIEDDCS_Data3Value "UNM";
BA_ "PacketOrder" SG_ 2158993408 ODIEDDCS_Data3Value 3;
BA_ "SignalLongName" SG_ 2158993408 ODIEDDCS_Data3Value "Open Display Interface Enum Dynamic Data : Data ID 3";
BA_ "VNSigAllNodes" SG_ 2158993408 ODIEDDCS_Data3Value 1;
BA_ "GenSigDeltaValue" SG_ 2158993408 ODIEDDCS_Data2Value 1;
BA_ "GenSigSendType" SG_ 2158993408 ODIEDDCS_Data2Value 12;
BA_ "GenSigSendOnInit" SG_ 2158993408 ODIEDDCS_Data2Value 1;
BA_ "VNSigInfotainment" SG_ 2158993408 ODIEDDCS_Data2Value 1;
BA_ "SignalType" SG_ 2158993408 ODIEDDCS_Data2Value "UNM";
BA_ "PacketOrder" SG_ 2158993408 ODIEDDCS_Data2Value 2;
BA_ "SignalLongName" SG_ 2158993408 ODIEDDCS_Data2Value "Open Display Interface Enum Dynamic Data : Data ID 2";
BA_ "VNSigAllNodes" SG_ 2158993408 ODIEDDCS_Data2Value 1;
BA_ "GenSigDeltaValue" SG_ 2158993408 ODIEDDCS_Data18Value 1;
BA_ "GenSigSendType" SG_ 2158993408 ODIEDDCS_Data18Value 12;
BA_ "GenSigSendOnInit" SG_ 2158993408 ODIEDDCS_Data18Value 1;
BA_ "VNSigInfotainment" SG_ 2158993408 ODIEDDCS_Data18Value 1;
BA_ "SignalType" SG_ 2158993408 ODIEDDCS_Data18Value "UNM";
BA_ "PacketOrder" SG_ 2158993408 ODIEDDCS_Data18Value 18;
BA_ "SignalLongName" SG_ 2158993408 ODIEDDCS_Data18Value "Open Display Interface Enum Dynamic Data : Data ID 18";
BA_ "VNSigAllNodes" SG_ 2158993408 ODIEDDCS_Data18Value 1;
BA_ "GenSigDeltaValue" SG_ 2158993408 ODIEDDCS_Data17Value 1;
BA_ "GenSigSendType" SG_ 2158993408 ODIEDDCS_Data17Value 12;
BA_ "GenSigSendOnInit" SG_ 2158993408 ODIEDDCS_Data17Value 1;
BA_ "VNSigInfotainment" SG_ 2158993408 ODIEDDCS_Data17Value 1;
BA_ "SignalType" SG_ 2158993408 ODIEDDCS_Data17Value "UNM";
BA_ "PacketOrder" SG_ 2158993408 ODIEDDCS_Data17Value 17;
BA_ "SignalLongName" SG_ 2158993408 ODIEDDCS_Data17Value "Open Display Interface Enum Dynamic Data : Data ID 17";
BA_ "VNSigAllNodes" SG_ 2158993408 ODIEDDCS_Data17Value 1;
BA_ "GenSigDeltaValue" SG_ 2158993408 ODIEDDCS_Data16Value 1;
BA_ "GenSigSendType" SG_ 2158993408 ODIEDDCS_Data16Value 12;
BA_ "GenSigSendOnInit" SG_ 2158993408 ODIEDDCS_Data16Value 1;
BA_ "VNSigInfotainment" SG_ 2158993408 ODIEDDCS_Data16Value 1;
BA_ "SignalType" SG_ 2158993408 ODIEDDCS_Data16Value "UNM";
BA_ "PacketOrder" SG_ 2158993408 ODIEDDCS_Data16Value 16;
BA_ "SignalLongName" SG_ 2158993408 ODIEDDCS_Data16Value "Open Display Interface Enum Dynamic Data : Data ID 16";
BA_ "VNSigAllNodes" SG_ 2158993408 ODIEDDCS_Data16Value 1;
BA_ "GenSigDeltaValue" SG_ 2158993408 ODIEDDCS_Data15Value 1;
BA_ "GenSigSendType" SG_ 2158993408 ODIEDDCS_Data15Value 12;
BA_ "GenSigSendOnInit" SG_ 2158993408 ODIEDDCS_Data15Value 1;
BA_ "VNSigInfotainment" SG_ 2158993408 ODIEDDCS_Data15Value 1;
BA_ "SignalType" SG_ 2158993408 ODIEDDCS_Data15Value "UNM";
BA_ "PacketOrder" SG_ 2158993408 ODIEDDCS_Data15Value 15;
BA_ "SignalLongName" SG_ 2158993408 ODIEDDCS_Data15Value "Open Display Interface Enum Dynamic Data : Data ID 15";
BA_ "VNSigAllNodes" SG_ 2158993408 ODIEDDCS_Data15Value 1;
BA_ "GenSigDeltaValue" SG_ 2158993408 ODIEDDCS_Data14Value 1;
BA_ "GenSigSendType" SG_ 2158993408 ODIEDDCS_Data14Value 12;
BA_ "GenSigSendOnInit" SG_ 2158993408 ODIEDDCS_Data14Value 1;
BA_ "VNSigInfotainment" SG_ 2158993408 ODIEDDCS_Data14Value 1;
BA_ "SignalType" SG_ 2158993408 ODIEDDCS_Data14Value "UNM";
BA_ "PacketOrder" SG_ 2158993408 ODIEDDCS_Data14Value 14;
BA_ "SignalLongName" SG_ 2158993408 ODIEDDCS_Data14Value "Open Display Interface Enum Dynamic Data : Data ID 14";
BA_ "VNSigAllNodes" SG_ 2158993408 ODIEDDCS_Data14Value 1;
BA_ "GenSigDeltaValue" SG_ 2158993408 ODIEDDCS_Data13Value 1;
BA_ "GenSigSendType" SG_ 2158993408 ODIEDDCS_Data13Value 12;
BA_ "GenSigSendOnInit" SG_ 2158993408 ODIEDDCS_Data13Value 1;
BA_ "VNSigInfotainment" SG_ 2158993408 ODIEDDCS_Data13Value 1;
BA_ "SignalType" SG_ 2158993408 ODIEDDCS_Data13Value "UNM";
BA_ "PacketOrder" SG_ 2158993408 ODIEDDCS_Data13Value 13;
BA_ "SignalLongName" SG_ 2158993408 ODIEDDCS_Data13Value "Open Display Interface Enum Dynamic Data : Data ID 13";
BA_ "VNSigAllNodes" SG_ 2158993408 ODIEDDCS_Data13Value 1;
BA_ "GenSigDeltaValue" SG_ 2158993408 ODIEDDCS_Data12Value 1;
BA_ "GenSigSendType" SG_ 2158993408 ODIEDDCS_Data12Value 12;
BA_ "GenSigSendOnInit" SG_ 2158993408 ODIEDDCS_Data12Value 1;
BA_ "VNSigInfotainment" SG_ 2158993408 ODIEDDCS_Data12Value 1;
BA_ "SignalType" SG_ 2158993408 ODIEDDCS_Data12Value "UNM";
BA_ "PacketOrder" SG_ 2158993408 ODIEDDCS_Data12Value 12;
BA_ "SignalLongName" SG_ 2158993408 ODIEDDCS_Data12Value "Open Display Interface Enum Dynamic Data : Data ID 12";
BA_ "VNSigAllNodes" SG_ 2158993408 ODIEDDCS_Data12Value 1;
BA_ "GenSigDeltaValue" SG_ 2158993408 ODIEDDCS_Data11Value 1;
BA_ "GenSigSendType" SG_ 2158993408 ODIEDDCS_Data11Value 12;
BA_ "GenSigSendOnInit" SG_ 2158993408 ODIEDDCS_Data11Value 1;
BA_ "VNSigInfotainment" SG_ 2158993408 ODIEDDCS_Data11Value 1;
BA_ "SignalType" SG_ 2158993408 ODIEDDCS_Data11Value "UNM";
BA_ "PacketOrder" SG_ 2158993408 ODIEDDCS_Data11Value 11;
BA_ "SignalLongName" SG_ 2158993408 ODIEDDCS_Data11Value "Open Display Interface Enum Dynamic Data : Data ID 11";
BA_ "VNSigAllNodes" SG_ 2158993408 ODIEDDCS_Data11Value 1;
BA_ "GenSigDeltaValue" SG_ 2158993408 ODIEDDCS_Data10Value 1;
BA_ "GenSigSendType" SG_ 2158993408 ODIEDDCS_Data10Value 12;
BA_ "GenSigSendOnInit" SG_ 2158993408 ODIEDDCS_Data10Value 1;
BA_ "VNSigInfotainment" SG_ 2158993408 ODIEDDCS_Data10Value 1;
BA_ "SignalType" SG_ 2158993408 ODIEDDCS_Data10Value "UNM";
BA_ "PacketOrder" SG_ 2158993408 ODIEDDCS_Data10Value 10;
BA_ "SignalLongName" SG_ 2158993408 ODIEDDCS_Data10Value "Open Display Interface Enum Dynamic Data : Data ID 10";
BA_ "VNSigAllNodes" SG_ 2158993408 ODIEDDCS_Data10Value 1;
BA_ "GenSigSendType" SG_ 2158993408 ODIEDDCS_Data1Value 12;
BA_ "GenSigSendOnInit" SG_ 2158993408 ODIEDDCS_Data1Value 1;
BA_ "VNSigInfotainment" SG_ 2158993408 ODIEDDCS_Data1Value 1;
BA_ "SignalType" SG_ 2158993408 ODIEDDCS_Data1Value "UNM";
BA_ "PacketOrder" SG_ 2158993408 ODIEDDCS_Data1Value 1;
BA_ "SignalLongName" SG_ 2158993408 ODIEDDCS_Data1Value "Open Display Interface Enum Dynamic Data : Data ID 1";
BA_ "VNSigAllNodes" SG_ 2158993408 ODIEDDCS_Data1Value 1;
BA_ "GenSigSendType" SG_ 2159026176 ODD_InvldData 10;
BA_ "VNSigInfotainment" SG_ 2159026176 ODD_InvldData 1;
BA_ "SignalType" SG_ 2159026176 ODD_InvldData "BLN";
BA_ "PacketOrder" SG_ 2159026176 ODD_InvldData 2;
BA_ "SignalLongName" SG_ 2159026176 ODD_InvldData "Open Display Interface Dynamic Data : Invalid Data";
BA_ "VNSigAllNodes" SG_ 2159026176 ODD_InvldData 1;
BA_ "GenSigDeltaValue" SG_ 2159026176 ODD_FUCID 1;
BA_ "GenSigSendType" SG_ 2159026176 ODD_FUCID 12;
BA_ "VNSigInfotainment" SG_ 2159026176 ODD_FUCID 1;
BA_ "SignalType" SG_ 2159026176 ODD_FUCID "UNM";
BA_ "PacketOrder" SG_ 2159026176 ODD_FUCID 3;
BA_ "SignalLongName" SG_ 2159026176 ODD_FUCID "Open Display Interface Dynamic Data : Functional Unit Class ID";
BA_ "VNSigAllNodes" SG_ 2159026176 ODD_FUCID 1;
BA_ "GenSigDeltaValue" SG_ 2159026176 ODD_DataVal 1;
BA_ "GenSigSendType" SG_ 2159026176 ODD_DataVal 12;
BA_ "VNSigInfotainment" SG_ 2159026176 ODD_DataVal 1;
BA_ "SignalType" SG_ 2159026176 ODD_DataVal "UNM";
BA_ "PacketOrder" SG_ 2159026176 ODD_DataVal 5;
BA_ "SignalLongName" SG_ 2159026176 ODD_DataVal "Open Display Interface Dynamic Data : Data Value";
BA_ "VNSigAllNodes" SG_ 2159026176 ODD_DataVal 1;
BA_ "GenSigSendType" SG_ 2159026176 ODD_DataType 10;
BA_ "VNSigInfotainment" SG_ 2159026176 ODD_DataType 1;
BA_ "SignalType" SG_ 2159026176 ODD_DataType "ENM";
BA_ "PacketOrder" SG_ 2159026176 ODD_DataType 1;
BA_ "SignalLongName" SG_ 2159026176 ODD_DataType "Open Display Interface Dynamic Data : Data Type";
BA_ "VNSigAllNodes" SG_ 2159026176 ODD_DataType 1;
BA_ "GenSigDeltaValue" SG_ 2159026176 ODD_DataId 1;
BA_ "GenSigSendType" SG_ 2159026176 ODD_DataId 12;
BA_ "VNSigInfotainment" SG_ 2159026176 ODD_DataId 1;
BA_ "SignalType" SG_ 2159026176 ODD_DataId "UNM";
BA_ "PacketOrder" SG_ 2159026176 ODD_DataId 4;
BA_ "SignalLongName" SG_ 2159026176 ODD_DataId "Open Display Interface Dynamic Data : Data ID";
BA_ "VNSigAllNodes" SG_ 2159026176 ODD_DataId 1;
BA_ "GenSigDeltaValue" SG_ 2159116288 ODI_TEL2AxIP 1;
BA_ "GenSigSendType" SG_ 2159116288 ODI_TEL2AxIP 12;
BA_ "VNSigInfotainment" SG_ 2159116288 ODI_TEL2AxIP 1;
BA_ "SignalType" SG_ 2159116288 ODI_TEL2AxIP "UNM";
BA_ "SignalLongName" SG_ 2159116288 ODI_TEL2AxIP "Open Display Interface TEL 2 AuxIP";
BA_ "VNSigAllNodes" SG_ 2159116288 ODI_TEL2AxIP 1;
BA_ "GenSigDeltaValue" SG_ 2159042560 ODDI_DataVal 1;
BA_ "GenSigSendType" SG_ 2159042560 ODDI_DataVal 12;
BA_ "VNSigInfotainment" SG_ 2159042560 ODDI_DataVal 1;
BA_ "SignalType" SG_ 2159042560 ODDI_DataVal "UNM";
BA_ "PacketOrder" SG_ 2159042560 ODDI_DataVal 5;
BA_ "SignalLongName" SG_ 2159042560 ODDI_DataVal "Open Display Interface Dynamic Data IPC : Data Value";
BA_ "VNSigAllNodes" SG_ 2159042560 ODDI_DataVal 1;
BA_ "GenSigDeltaValue" SG_ 2159042560 ODDI_DataId 1;
BA_ "GenSigSendType" SG_ 2159042560 ODDI_DataId 12;
BA_ "VNSigInfotainment" SG_ 2159042560 ODDI_DataId 1;
BA_ "SignalType" SG_ 2159042560 ODDI_DataId "UNM";
BA_ "PacketOrder" SG_ 2159042560 ODDI_DataId 4;
BA_ "SignalLongName" SG_ 2159042560 ODDI_DataId "Open Display Interface Dynamic Data IPC : Data ID";
BA_ "VNSigAllNodes" SG_ 2159042560 ODDI_DataId 1;
BA_ "GenSigDeltaValue" SG_ 2159042560 ODDI_FUCID 1;
BA_ "GenSigSendType" SG_ 2159042560 ODDI_FUCID 12;
BA_ "VNSigInfotainment" SG_ 2159042560 ODDI_FUCID 1;
BA_ "SignalType" SG_ 2159042560 ODDI_FUCID "UNM";
BA_ "PacketOrder" SG_ 2159042560 ODDI_FUCID 3;
BA_ "SignalLongName" SG_ 2159042560 ODDI_FUCID "Open Display Interface Dynamic Data IPC : Functional Unit Class ID";
BA_ "VNSigAllNodes" SG_ 2159042560 ODDI_FUCID 1;
BA_ "GenSigSendType" SG_ 2159042560 ODDI_InvldData 10;
BA_ "VNSigInfotainment" SG_ 2159042560 ODDI_InvldData 1;
BA_ "SignalType" SG_ 2159042560 ODDI_InvldData "BLN";
BA_ "PacketOrder" SG_ 2159042560 ODDI_InvldData 2;
BA_ "SignalLongName" SG_ 2159042560 ODDI_InvldData "Open Display Interface Dynamic Data IPC : Invalid Data";
BA_ "VNSigAllNodes" SG_ 2159042560 ODDI_InvldData 1;
BA_ "GenSigSendType" SG_ 2159042560 ODDI_DataType 10;
BA_ "VNSigInfotainment" SG_ 2159042560 ODDI_DataType 1;
BA_ "SignalType" SG_ 2159042560 ODDI_DataType "ENM";
BA_ "PacketOrder" SG_ 2159042560 ODDI_DataType 1;
BA_ "SignalLongName" SG_ 2159042560 ODDI_DataType "Open Display Interface Dynamic Data IPC : Data Type";
BA_ "VNSigAllNodes" SG_ 2159042560 ODDI_DataType 1;
BA_ "GenSigSendType" SG_ 2158927872 ODDC_InvldData 10;
BA_ "VNSigInfotainment" SG_ 2158927872 ODDC_InvldData 1;
BA_ "SignalType" SG_ 2158927872 ODDC_InvldData "BLN";
BA_ "PacketOrder" SG_ 2158927872 ODDC_InvldData 2;
BA_ "SignalLongName" SG_ 2158927872 ODDC_InvldData "Open Display Interface Dynamic Data Centerstack : Invalid Data";
BA_ "VNSigAllNodes" SG_ 2158927872 ODDC_InvldData 1;
BA_ "GenSigDeltaValue" SG_ 2158927872 ODDC_FUCID 1;
BA_ "GenSigSendType" SG_ 2158927872 ODDC_FUCID 12;
BA_ "VNSigInfotainment" SG_ 2158927872 ODDC_FUCID 1;
BA_ "SignalType" SG_ 2158927872 ODDC_FUCID "UNM";
BA_ "PacketOrder" SG_ 2158927872 ODDC_FUCID 3;
BA_ "SignalLongName" SG_ 2158927872 ODDC_FUCID "Open Display Interface Dynamic Data Centerstack : Functional Unit Class ID";
BA_ "VNSigAllNodes" SG_ 2158927872 ODDC_FUCID 1;
BA_ "GenSigDeltaValue" SG_ 2158927872 ODDC_DataVal 1;
BA_ "GenSigSendType" SG_ 2158927872 ODDC_DataVal 12;
BA_ "VNSigInfotainment" SG_ 2158927872 ODDC_DataVal 1;
BA_ "SignalType" SG_ 2158927872 ODDC_DataVal "UNM";
BA_ "PacketOrder" SG_ 2158927872 ODDC_DataVal 5;
BA_ "SignalLongName" SG_ 2158927872 ODDC_DataVal "Open Display Interface Dynamic Data Centerstack : Data Value";
BA_ "VNSigAllNodes" SG_ 2158927872 ODDC_DataVal 1;
BA_ "GenSigSendType" SG_ 2158927872 ODDC_DataType 10;
BA_ "VNSigInfotainment" SG_ 2158927872 ODDC_DataType 1;
BA_ "SignalType" SG_ 2158927872 ODDC_DataType "ENM";
BA_ "PacketOrder" SG_ 2158927872 ODDC_DataType 1;
BA_ "SignalLongName" SG_ 2158927872 ODDC_DataType "Open Display Interface Dynamic Data Centerstack : Data Type";
BA_ "VNSigAllNodes" SG_ 2158927872 ODDC_DataType 1;
BA_ "GenSigDeltaValue" SG_ 2158927872 ODDC_DataId 1;
BA_ "GenSigSendType" SG_ 2158927872 ODDC_DataId 12;
BA_ "VNSigInfotainment" SG_ 2158927872 ODDC_DataId 1;
BA_ "SignalType" SG_ 2158927872 ODDC_DataId "UNM";
BA_ "PacketOrder" SG_ 2158927872 ODDC_DataId 4;
BA_ "SignalLongName" SG_ 2158927872 ODDC_DataId "Open Display Interface Dynamic Data Centerstack : Data ID";
BA_ "VNSigAllNodes" SG_ 2158927872 ODDC_DataId 1;
BA_ "GenSigDeltaValue" SG_ 2159099904 ODI_DAB2AxIP 1;
BA_ "GenSigSendType" SG_ 2159099904 ODI_DAB2AxIP 12;
BA_ "VNSigInfotainment" SG_ 2159099904 ODI_DAB2AxIP 1;
BA_ "SignalType" SG_ 2159099904 ODI_DAB2AxIP "UNM";
BA_ "SignalLongName" SG_ 2159099904 ODI_DAB2AxIP "Open Display Interface DAB 2 AuxIP";
BA_ "VNSigAllNodes" SG_ 2159099904 ODI_DAB2AxIP 1;
BA_ "GenSigDeltaValue" SG_ 2159181824 ODI_CntrStck2AxIP 1;
BA_ "GenSigSendType" SG_ 2159181824 ODI_CntrStck2AxIP 12;
BA_ "VNSigInfotainment" SG_ 2159181824 ODI_CntrStck2AxIP 1;
BA_ "SignalType" SG_ 2159181824 ODI_CntrStck2AxIP "UNM";
BA_ "SignalLongName" SG_ 2159181824 ODI_CntrStck2AxIP "Open Display Interface CenterStack 2 AuxIP";
BA_ "VNSigAllNodes" SG_ 2159181824 ODI_CntrStck2AxIP 1;
BA_ "SignalType" SG_ 1622 DgnInf "UNM";
BA_ "SignalLongName" SG_ 1622 DgnInf "Diagnostic Information";
BA_ "VNSigDiagnostic" SG_ 1622 DgnInf 1;
BA_ "VNSigAllNodes" SG_ 1622 DgnInf 1;
BA_ "VNSigPrimaryTriggering" SG_ 1590 VectraSpcNWMgtD 1;
BA_ "VNSigRemoteDiagnostics" SG_ 1590 VectraSpcNWMgtD 1;
BA_ "VNSigInfotainment" SG_ 1590 VectraSpcNWMgtD 1;
BA_ "VNSigParkedVehicle" SG_ 1590 VectraSpcNWMgtD 1;
BA_ "VNSigIntermediate" SG_ 1590 VectraSpcNWMgtD 1;
BA_ "VNSigUnused_4" SG_ 1590 VectraSpcNWMgtD 1;
BA_ "SignalType" SG_ 1590 VectraSpcNWMgtD "UNM";
BA_ "SignalLongName" SG_ 1590 VectraSpcNWMgtD "Vectra Specific Network Management Data";
BA_ "VNSigDiagnostic" SG_ 1590 VectraSpcNWMgtD 1;
BA_ "VNSigAllNodes" SG_ 1590 VectraSpcNWMgtD 1;
BA_ "GenSigDeltaValue" SG_ 1366 DgnInf_LS556 1;
BA_ "GenSigSendType" SG_ 1366 DgnInf_LS556 12;
BA_ "SignalType" SG_ 1366 DgnInf_LS556 "UNM";
BA_ "SignalLongName" SG_ 1366 DgnInf_LS556 "Diagnostic Information LS556";
BA_ "VNSigDiagnostic" SG_ 1366 DgnInf_LS556 1;
BA_ "VNSigAllNodes" SG_ 1366 DgnInf_LS556 1;
BA_ "GenSigSendType" SG_ 2156789760 FrPedDetCsStReq 10;
BA_ "SignalType" SG_ 2156789760 FrPedDetCsStReq "ENM";
BA_ "SignalLongName" SG_ 2156789760 FrPedDetCsStReq "Front Pedestrian Detection Customization Setting Request";
BA_ "VNSigAllNodes" SG_ 2156789760 FrPedDetCsStReq 1;
BA_ "GenSigSendType" SG_ 2156789760 TimeDispFormat 10;
BA_ "GenSigSendOnInit" SG_ 2156789760 TimeDispFormat 1;
BA_ "VNSigInfotainment" SG_ 2156789760 TimeDispFormat 1;
BA_ "SignalType" SG_ 2156789760 TimeDispFormat "ENM";
BA_ "SignalLongName" SG_ 2156789760 TimeDispFormat "Time Display Format";
BA_ "VNSigAllNodes" SG_ 2156789760 TimeDispFormat 1;
BA_ "GenSigDeltaValue" SG_ 2156789760 CldrYr 1;
BA_ "GenSigSendType" SG_ 2156789760 CldrYr 12;
BA_ "GenSigSendOnInit" SG_ 2156789760 CldrYr 1;
BA_ "VNSigInfotainment" SG_ 2156789760 CldrYr 1;
BA_ "SignalType" SG_ 2156789760 CldrYr "UNM";
BA_ "SignalLongName" SG_ 2156789760 CldrYr "Calendar Year";
BA_ "VNSigAllNodes" SG_ 2156789760 CldrYr 1;
BA_ "GenSigSendType" SG_ 2156789760 CldrMth 10;
BA_ "GenSigSendOnInit" SG_ 2156789760 CldrMth 1;
BA_ "VNSigInfotainment" SG_ 2156789760 CldrMth 1;
BA_ "SignalType" SG_ 2156789760 CldrMth "ENM";
BA_ "SignalLongName" SG_ 2156789760 CldrMth "Calendar Month";
BA_ "VNSigAllNodes" SG_ 2156789760 CldrMth 1;
BA_ "GenSigDeltaValue" SG_ 2156789760 CldrDay 1;
BA_ "GenSigSendType" SG_ 2156789760 CldrDay 12;
BA_ "GenSigSendOnInit" SG_ 2156789760 CldrDay 1;
BA_ "VNSigInfotainment" SG_ 2156789760 CldrDay 1;
BA_ "SignalType" SG_ 2156789760 CldrDay "UNM";
BA_ "SignalLongName" SG_ 2156789760 CldrDay "Calendar Day";
BA_ "VNSigAllNodes" SG_ 2156789760 CldrDay 1;
BA_ "GenSigDeltaValue" SG_ 2156789760 TOD_SecofMin 1;
BA_ "GenSigSendType" SG_ 2156789760 TOD_SecofMin 12;
BA_ "GenSigSendOnInit" SG_ 2156789760 TOD_SecofMin 1;
BA_ "VNSigInfotainment" SG_ 2156789760 TOD_SecofMin 1;
BA_ "SignalType" SG_ 2156789760 TOD_SecofMin "UNM";
BA_ "PacketOrder" SG_ 2156789760 TOD_SecofMin 3;
BA_ "SignalLongName" SG_ 2156789760 TOD_SecofMin "Time of Day : Seconds of Minute";
BA_ "VNSigAllNodes" SG_ 2156789760 TOD_SecofMin 1;
BA_ "GenSigDeltaValue" SG_ 2156789760 TOD_MinofHr 1;
BA_ "GenSigSendType" SG_ 2156789760 TOD_MinofHr 12;
BA_ "GenSigSendOnInit" SG_ 2156789760 TOD_MinofHr 1;
BA_ "VNSigInfotainment" SG_ 2156789760 TOD_MinofHr 1;
BA_ "SignalType" SG_ 2156789760 TOD_MinofHr "UNM";
BA_ "PacketOrder" SG_ 2156789760 TOD_MinofHr 2;
BA_ "SignalLongName" SG_ 2156789760 TOD_MinofHr "Time of Day : Minute of Hour";
BA_ "VNSigAllNodes" SG_ 2156789760 TOD_MinofHr 1;
BA_ "GenSigDeltaValue" SG_ 2156789760 TOD_HrofDay 1;
BA_ "GenSigSendType" SG_ 2156789760 TOD_HrofDay 12;
BA_ "GenSigSendOnInit" SG_ 2156789760 TOD_HrofDay 1;
BA_ "VNSigInfotainment" SG_ 2156789760 TOD_HrofDay 1;
BA_ "SignalType" SG_ 2156789760 TOD_HrofDay "UNM";
BA_ "PacketOrder" SG_ 2156789760 TOD_HrofDay 1;
BA_ "SignalLongName" SG_ 2156789760 TOD_HrofDay "Time of Day : Hour of Day";
BA_ "VNSigAllNodes" SG_ 2156789760 TOD_HrofDay 1;
BA_ "GenSigSendType" SG_ 2156789760 SurdVwLightgCsSetReq 10;
BA_ "SignalType" SG_ 2156789760 SurdVwLightgCsSetReq "ENM";
BA_ "SignalLongName" SG_ 2156789760 SurdVwLightgCsSetReq "Surround View Lighting Customization Setting Request";
BA_ "VNSigAllNodes" SG_ 2156789760 SurdVwLightgCsSetReq 1;
BA_ "GenSigSendType" SG_ 2156789760 SmrtHgBmAstCstSetReq 10;
BA_ "SignalType" SG_ 2156789760 SmrtHgBmAstCstSetReq "ENM";
BA_ "SignalLongName" SG_ 2156789760 SmrtHgBmAstCstSetReq "Smart High Beam Assist Customization Setting Request";
BA_ "VNSigAllNodes" SG_ 2156789760 SmrtHgBmAstCstSetReq 1;
BA_ "GenSigDeltaValue" SG_ 2151956480 StrWhlThbwhlCnts 1;
BA_ "GenSigSendType" SG_ 2151956480 StrWhlThbwhlCnts 12;
BA_ "VNSigInfotainment" SG_ 2151956480 StrWhlThbwhlCnts 1;
BA_ "SignalType" SG_ 2151956480 StrWhlThbwhlCnts "SNM";
BA_ "SignalLongName" SG_ 2151956480 StrWhlThbwhlCnts "Steering Wheel Thumbwheel Counts";
BA_ "VNSigAllNodes" SG_ 2151956480 StrWhlThbwhlCnts 1;
BA_ "GenSigDeltaValue" SG_ 2151956480 DrvWrkldLvl 1;
BA_ "GenSigSendType" SG_ 2151956480 DrvWrkldLvl 12;
BA_ "SignalType" SG_ 2151956480 DrvWrkldLvl "UNM";
BA_ "SignalLongName" SG_ 2151956480 DrvWrkldLvl "Driver Workload Level";
BA_ "VNSigAllNodes" SG_ 2151956480 DrvWrkldLvl 1;
BA_ "GenSigSendType" SG_ 2151956480 ClstrHMIRdy 10;
BA_ "GenSigSendOnInit" SG_ 2151956480 ClstrHMIRdy 1;
BA_ "VNSigInfotainment" SG_ 2151956480 ClstrHMIRdy 1;
BA_ "SignalType" SG_ 2151956480 ClstrHMIRdy "BLN";
BA_ "SignalLongName" SG_ 2151956480 ClstrHMIRdy "Cluster HMI Ready";
BA_ "VNSigAllNodes" SG_ 2151956480 ClstrHMIRdy 1;
BA_ "GenSigSendType" SG_ 2151956480 ClstrHMIAnmSt 10;
BA_ "GenSigSendOnInit" SG_ 2151956480 ClstrHMIAnmSt 1;
BA_ "VNSigInfotainment" SG_ 2151956480 ClstrHMIAnmSt 1;
BA_ "SignalType" SG_ 2151956480 ClstrHMIAnmSt "ENM";
BA_ "SignalLongName" SG_ 2151956480 ClstrHMIAnmSt "Cluster HMI Animation State";
BA_ "VNSigAllNodes" SG_ 2151956480 ClstrHMIAnmSt 1;
BA_ "GenSigSendType" SG_ 2150268928 EmrgncyRspSysTyp 10;
BA_ "SignalType" SG_ 2150268928 EmrgncyRspSysTyp "ENM";
BA_ "SignalLongName" SG_ 2150268928 EmrgncyRspSysTyp "Emergency Response System Type";
BA_ "VNSigAllNodes" SG_ 2150268928 EmrgncyRspSysTyp 1;
BA_ "GenSigSendType" SG_ 2150268928 EmrgncyRspSysSrvIndOn 10;
BA_ "GenSigSendOnInit" SG_ 2150268928 EmrgncyRspSysSrvIndOn 1;
BA_ "SignalType" SG_ 2150268928 EmrgncyRspSysSrvIndOn "BLN";
BA_ "SignalLongName" SG_ 2150268928 EmrgncyRspSysSrvIndOn "Emergency Response System Service Indication On";
BA_ "VNSigAllNodes" SG_ 2150268928 EmrgncyRspSysSrvIndOn 1;
BA_ "GenSigDeltaValue" SG_ 2150268928 CldrYr_154 1;
BA_ "GenSigSendType" SG_ 2150268928 CldrYr_154 12;
BA_ "GenSigSendOnInit" SG_ 2150268928 CldrYr_154 1;
BA_ "VNSigInfotainment" SG_ 2150268928 CldrYr_154 1;
BA_ "SignalType" SG_ 2150268928 CldrYr_154 "UNM";
BA_ "SignalLongName" SG_ 2150268928 CldrYr_154 "Calendar Year";
BA_ "VNSigAllNodes" SG_ 2150268928 CldrYr_154 1;
BA_ "GenSigSendType" SG_ 2150268928 CldrMth_154 10;
BA_ "GenSigSendOnInit" SG_ 2150268928 CldrMth_154 1;
BA_ "VNSigInfotainment" SG_ 2150268928 CldrMth_154 1;
BA_ "SignalType" SG_ 2150268928 CldrMth_154 "ENM";
BA_ "SignalLongName" SG_ 2150268928 CldrMth_154 "Calendar Month";
BA_ "VNSigAllNodes" SG_ 2150268928 CldrMth_154 1;
BA_ "GenSigDeltaValue" SG_ 2150268928 CldrDay_154 1;
BA_ "GenSigSendType" SG_ 2150268928 CldrDay_154 12;
BA_ "GenSigSendOnInit" SG_ 2150268928 CldrDay_154 1;
BA_ "VNSigInfotainment" SG_ 2150268928 CldrDay_154 1;
BA_ "SignalType" SG_ 2150268928 CldrDay_154 "UNM";
BA_ "SignalLongName" SG_ 2150268928 CldrDay_154 "Calendar Day";
BA_ "VNSigAllNodes" SG_ 2150268928 CldrDay_154 1;
BA_ "GenSigSendType" SG_ 2150268928 SecV 10;
BA_ "GenSigSendOnInit" SG_ 2150268928 SecV 1;
BA_ "VNSigInfotainment" SG_ 2150268928 SecV 1;
BA_ "SignalType" SG_ 2150268928 SecV "ENM";
BA_ "SignalLongName" SG_ 2150268928 SecV "Seconds Validity";
BA_ "VNSigAllNodes" SG_ 2150268928 SecV 1;
BA_ "GenSigDeltaValue" SG_ 2150268928 Sec 1;
BA_ "GenSigSendType" SG_ 2150268928 Sec 12;
BA_ "GenSigSendOnInit" SG_ 2150268928 Sec 1;
BA_ "VNSigInfotainment" SG_ 2150268928 Sec 1;
BA_ "SignalType" SG_ 2150268928 Sec "UNM";
BA_ "SignalLongName" SG_ 2150268928 Sec "Seconds";
BA_ "VNSigAllNodes" SG_ 2150268928 Sec 1;
BA_ "GenSigSendType" SG_ 2150268928 MinsV 10;
BA_ "GenSigSendOnInit" SG_ 2150268928 MinsV 1;
BA_ "VNSigInfotainment" SG_ 2150268928 MinsV 1;
BA_ "SignalType" SG_ 2150268928 MinsV "ENM";
BA_ "SignalLongName" SG_ 2150268928 MinsV "Minutes Validity";
BA_ "VNSigAllNodes" SG_ 2150268928 MinsV 1;
BA_ "GenSigDeltaValue" SG_ 2150268928 Mins 1;
BA_ "GenSigSendType" SG_ 2150268928 Mins 12;
BA_ "GenSigSendOnInit" SG_ 2150268928 Mins 1;
BA_ "VNSigInfotainment" SG_ 2150268928 Mins 1;
BA_ "SignalType" SG_ 2150268928 Mins "UNM";
BA_ "SignalLongName" SG_ 2150268928 Mins "Minutes";
BA_ "VNSigAllNodes" SG_ 2150268928 Mins 1;
BA_ "GenSigSendType" SG_ 2150268928 HrsV 10;
BA_ "GenSigSendOnInit" SG_ 2150268928 HrsV 1;
BA_ "VNSigInfotainment" SG_ 2150268928 HrsV 1;
BA_ "SignalType" SG_ 2150268928 HrsV "ENM";
BA_ "SignalLongName" SG_ 2150268928 HrsV "Hours Validity";
BA_ "VNSigAllNodes" SG_ 2150268928 HrsV 1;
BA_ "GenSigDeltaValue" SG_ 2150268928 Hrs 1;
BA_ "GenSigSendType" SG_ 2150268928 Hrs 12;
BA_ "GenSigSendOnInit" SG_ 2150268928 Hrs 1;
BA_ "VNSigInfotainment" SG_ 2150268928 Hrs 1;
BA_ "SignalType" SG_ 2150268928 Hrs "UNM";
BA_ "SignalLongName" SG_ 2150268928 Hrs "Hours";
BA_ "VNSigAllNodes" SG_ 2150268928 Hrs 1;
BA_ "GenSigSendType" SG_ 2156175360 NtVsnSysEnbld 10;
BA_ "SignalType" SG_ 2156175360 NtVsnSysEnbld "BLN";
BA_ "SignalLongName" SG_ 2156175360 NtVsnSysEnbld "Night Vision System Enabled";
BA_ "VNSigAllNodes" SG_ 2156175360 NtVsnSysEnbld 1;
BA_ "GenSigSendType" SG_ 2156175360 DispMeasSysExt 10;
BA_ "GenSigSendOnInit" SG_ 2156175360 DispMeasSysExt 1;
BA_ "VNSigInfotainment" SG_ 2156175360 DispMeasSysExt 1;
BA_ "SignalType" SG_ 2156175360 DispMeasSysExt "ENM";
BA_ "SignalLongName" SG_ 2156175360 DispMeasSysExt "Display Measurement System Extended";
BA_ "VNSigAllNodes" SG_ 2156175360 DispMeasSysExt 1;
BA_ "GenSigSendType" SG_ 2156175360 DispMeasSys 10;
BA_ "GenSigSendOnInit" SG_ 2156175360 DispMeasSys 1;
BA_ "SignalType" SG_ 2156175360 DispMeasSys "ENM";
BA_ "SignalLongName" SG_ 2156175360 DispMeasSys "Display Measurement System";
BA_ "VNSigAllNodes" SG_ 2156175360 DispMeasSys 1;
BA_ "GenSigSendType" SG_ 2154053632 TrlrLtngSeqStat 10;
BA_ "VNSigIntermediate" SG_ 2154053632 TrlrLtngSeqStat 1;
BA_ "SignalType" SG_ 2154053632 TrlrLtngSeqStat "ENM";
BA_ "SignalLongName" SG_ 2154053632 TrlrLtngSeqStat "Trailer Lighting Sequence Status";
BA_ "VNSigAllNodes" SG_ 2154053632 TrlrLtngSeqStat 1;
BA_ "GenSigSendType" SG_ 2154053632 CargoLmpActIO 10;
BA_ "SignalType" SG_ 2154053632 CargoLmpActIO "BLN";
BA_ "SignalLongName" SG_ 2154053632 CargoLmpActIO "Cargo Lamp Active Indication On";
BA_ "VNSigAllNodes" SG_ 2154053632 CargoLmpActIO 1;
BA_ "GenSigSendType" SG_ 2154053632 DispNtSchmAtv 10;
BA_ "GenSigSendOnInit" SG_ 2154053632 DispNtSchmAtv 2;
BA_ "VNSigInfotainment" SG_ 2154053632 DispNtSchmAtv 1;
BA_ "SignalType" SG_ 2154053632 DispNtSchmAtv "BLN";
BA_ "SignalLongName" SG_ 2154053632 DispNtSchmAtv "Display Night Scheme Active";
BA_ "VNSigAllNodes" SG_ 2154053632 DispNtSchmAtv 1;
BA_ "GenSigDeltaValue" SG_ 2154053632 IntDimLvl 1;
BA_ "GenSigSendType" SG_ 2154053632 IntDimLvl 12;
BA_ "GenSigSendOnInit" SG_ 2154053632 IntDimLvl 2;
BA_ "VNSigInfotainment" SG_ 2154053632 IntDimLvl 1;
BA_ "SignalType" SG_ 2154053632 IntDimLvl "UNM";
BA_ "SignalLongName" SG_ 2154053632 IntDimLvl "Interior Dimming Level";
BA_ "VNSigAllNodes" SG_ 2154053632 IntDimLvl 1;
BA_ "GenSigDeltaValue" SG_ 2154053632 IntDimDspLvl 1;
BA_ "GenSigSendType" SG_ 2154053632 IntDimDspLvl 12;
BA_ "GenSigSendOnInit" SG_ 2154053632 IntDimDspLvl 2;
BA_ "VNSigInfotainment" SG_ 2154053632 IntDimDspLvl 1;
BA_ "SignalType" SG_ 2154053632 IntDimDspLvl "UNM";
BA_ "SignalLongName" SG_ 2154053632 IntDimDspLvl "Interior Dimming Display Level";
BA_ "VNSigAllNodes" SG_ 2154053632 IntDimDspLvl 1;
BA_ "GenSigSendType" SG_ 2154053632 IntDimNtPnlAtv 10;
BA_ "VNSigInfotainment" SG_ 2154053632 IntDimNtPnlAtv 1;
BA_ "SignalType" SG_ 2154053632 IntDimNtPnlAtv "BLN";
BA_ "SignalLongName" SG_ 2154053632 IntDimNtPnlAtv "Interior Dimming Night Panel Active";
BA_ "VNSigAllNodes" SG_ 2154053632 IntDimNtPnlAtv 1;
BA_ "GenSigSendType" SG_ 2155216896 SpdLmtPstdSpdM 10;
BA_ "SignalType" SG_ 2155216896 SpdLmtPstdSpdM "ENM";
BA_ "SignalLongName" SG_ 2155216896 SpdLmtPstdSpdM "Speed Limit Posted Speed Mask";
BA_ "VNSigAllNodes" SG_ 2155216896 SpdLmtPstdSpdM 1;
BA_ "GenSigSendType" SG_ 2155216896 ISA2CCC_ScndCdChr 10;
BA_ "SignalType" SG_ 2155216896 ISA2CCC_ScndCdChr "ENM";
BA_ "PacketOrder" SG_ 2155216896 ISA2CCC_ScndCdChr 2;
BA_ "SignalLongName" SG_ 2155216896 ISA2CCC_ScndCdChr "International Standard Alpha 2 Coded Country Code : Second Code Character";
BA_ "VNSigAllNodes" SG_ 2155216896 ISA2CCC_ScndCdChr 1;
BA_ "GenSigSendType" SG_ 2155216896 ISA2CCC_FrstCdChr 10;
BA_ "SignalType" SG_ 2155216896 ISA2CCC_FrstCdChr "ENM";
BA_ "PacketOrder" SG_ 2155216896 ISA2CCC_FrstCdChr 1;
BA_ "SignalLongName" SG_ 2155216896 ISA2CCC_FrstCdChr "International Standard Alpha 2 Coded Country Code : First Code Character";
BA_ "VNSigAllNodes" SG_ 2155216896 ISA2CCC_FrstCdChr 1;
BA_ "GenSigSendType" SG_ 2155216896 CurvAdvInd 10;
BA_ "SignalType" SG_ 2155216896 CurvAdvInd "ENM";
BA_ "SignalLongName" SG_ 2155216896 CurvAdvInd "Curve Advisory Indication";
BA_ "VNSigAllNodes" SG_ 2155216896 CurvAdvInd 1;
BA_ "GenSigSendType" SG_ 2155216896 SpdLmtUnits 10;
BA_ "SignalType" SG_ 2155216896 SpdLmtUnits "ENM";
BA_ "SignalLongName" SG_ 2155216896 SpdLmtUnits "Speed Limit Units";
BA_ "VNSigAllNodes" SG_ 2155216896 SpdLmtUnits 1;
BA_ "GenSigDeltaValue" SG_ 2155216896 SpdLmtRecmndSpd 1;
BA_ "GenSigSendType" SG_ 2155216896 SpdLmtRecmndSpd 12;
BA_ "SignalType" SG_ 2155216896 SpdLmtRecmndSpd "UNM";
BA_ "SignalLongName" SG_ 2155216896 SpdLmtRecmndSpd "Speed Limit Recommended Speed";
BA_ "VNSigAllNodes" SG_ 2155216896 SpdLmtRecmndSpd 1;
BA_ "GenSigDeltaValue" SG_ 2155216896 SpdLmtPstdSpd 1;
BA_ "GenSigSendType" SG_ 2155216896 SpdLmtPstdSpd 12;
BA_ "SignalType" SG_ 2155216896 SpdLmtPstdSpd "UNM";
BA_ "SignalLongName" SG_ 2155216896 SpdLmtPstdSpd "Speed Limit Posted Speed";
BA_ "VNSigAllNodes" SG_ 2155216896 SpdLmtPstdSpd 1;
BA_ "GenSigSendType" SG_ 2155216896 LnCat 10;
BA_ "GenSigSendOnInit" SG_ 2155216896 LnCat 1;
BA_ "SignalType" SG_ 2155216896 LnCat "ENM";
BA_ "SignalLongName" SG_ 2155216896 LnCat "Lane Category";
BA_ "VNSigAllNodes" SG_ 2155216896 LnCat 1;
BA_ "GenSigSendType" SG_ 2155216896 RdSpdCatType 10;
BA_ "GenSigSendOnInit" SG_ 2155216896 RdSpdCatType 1;
BA_ "SignalType" SG_ 2155216896 RdSpdCatType "ENM";
BA_ "SignalLongName" SG_ 2155216896 RdSpdCatType "Road Speed Category Type";
BA_ "VNSigAllNodes" SG_ 2155216896 RdSpdCatType 1;
BA_ "GenSigSendType" SG_ 2155216896 FncRdClass 10;
BA_ "GenSigSendOnInit" SG_ 2155216896 FncRdClass 1;
BA_ "SignalType" SG_ 2155216896 FncRdClass "ENM";
BA_ "SignalLongName" SG_ 2155216896 FncRdClass "Functional Road Class";
BA_ "VNSigAllNodes" SG_ 2155216896 FncRdClass 1;
BA_ "GenSigSendType" SG_ 2155216896 SprtLnRd 10;
BA_ "GenSigSendOnInit" SG_ 2155216896 SprtLnRd 1;
BA_ "SignalType" SG_ 2155216896 SprtLnRd "BLN";
BA_ "SignalLongName" SG_ 2155216896 SprtLnRd "Separate Lane Road";
BA_ "VNSigAllNodes" SG_ 2155216896 SprtLnRd 1;
BA_ "GenSigSendType" SG_ 2155216896 CntrldAccRd 10;
BA_ "GenSigSendOnInit" SG_ 2155216896 CntrldAccRd 1;
BA_ "SignalType" SG_ 2155216896 CntrldAccRd "BLN";
BA_ "SignalLongName" SG_ 2155216896 CntrldAccRd "Controlled Access Road";
BA_ "VNSigAllNodes" SG_ 2155216896 CntrldAccRd 1;
BA_ "GenSigSendType" SG_ 2155216896 BldUpArDet 10;
BA_ "GenSigSendOnInit" SG_ 2155216896 BldUpArDet 1;
BA_ "SignalType" SG_ 2155216896 BldUpArDet "BLN";
BA_ "SignalLongName" SG_ 2155216896 BldUpArDet "Build Up Area Detected";
BA_ "VNSigAllNodes" SG_ 2155216896 BldUpArDet 1;
BA_ "GenSigSendType" SG_ 2155216896 MpDataAvlbl 10;
BA_ "GenSigSendOnInit" SG_ 2155216896 MpDataAvlbl 1;
BA_ "SignalType" SG_ 2155216896 MpDataAvlbl "BLN";
BA_ "SignalLongName" SG_ 2155216896 MpDataAvlbl "Map Data Available";
BA_ "VNSigAllNodes" SG_ 2155216896 MpDataAvlbl 1;
BA_ "GenSigSendType" SG_ 2155216896 DgtlMapPstdSpdLimAsrd 10;
BA_ "GenSigSendOnInit" SG_ 2155216896 DgtlMapPstdSpdLimAsrd 1;
BA_ "SignalType" SG_ 2155216896 DgtlMapPstdSpdLimAsrd "BLN";
BA_ "SignalLongName" SG_ 2155216896 DgtlMapPstdSpdLimAsrd "Digital Map Posted Speed Limit Assured";
BA_ "VNSigAllNodes" SG_ 2155216896 DgtlMapPstdSpdLimAsrd 1;
BA_ "GenSigSendType" SG_ 2154921984 RFRmtCntFobNm 10;
BA_ "SignalType" SG_ 2154921984 RFRmtCntFobNm "ENM";
BA_ "PacketOrder" SG_ 2154921984 RFRmtCntFobNm 1;
BA_ "SignalLongName" SG_ 2154921984 RFRmtCntFobNm "RFA Function : Remote Control Fob Number";
BA_ "VNSigAllNodes" SG_ 2154921984 RFRmtCntFobNm 1;
BA_ "GenSigSendType" SG_ 2154921984 RFRmtCntrlFobFnc 10;
BA_ "SignalType" SG_ 2154921984 RFRmtCntrlFobFnc "ENM";
BA_ "PacketOrder" SG_ 2154921984 RFRmtCntrlFobFnc 2;
BA_ "SignalLongName" SG_ 2154921984 RFRmtCntrlFobFnc "RFA Function : Remote Control Fob Function";
BA_ "VNSigAllNodes" SG_ 2154921984 RFRmtCntrlFobFnc 1;
BA_ "GenSigSendType" SG_ 2154921984 RFRmtCntFobBatLw 10;
BA_ "SignalType" SG_ 2154921984 RFRmtCntFobBatLw "BLN";
BA_ "PacketOrder" SG_ 2154921984 RFRmtCntFobBatLw 3;
BA_ "SignalLongName" SG_ 2154921984 RFRmtCntFobBatLw "RFA Function : Remote Control Fob Battery Low";
BA_ "VNSigAllNodes" SG_ 2154921984 RFRmtCntFobBatLw 1;
BA_ "GenSigSendType" SG_ 2154921984 FobPogLimRchdIndOn 10;
BA_ "SignalType" SG_ 2154921984 FobPogLimRchdIndOn "BLN";
BA_ "SignalLongName" SG_ 2154921984 FobPogLimRchdIndOn "Fob Programming Limit Reached Indication On";
BA_ "VNSigAllNodes" SG_ 2154921984 FobPogLimRchdIndOn 1;
BA_ "GenSigSendType" SG_ 2153971712 LftglsRelSwAct 10;
BA_ "GenSigSendOnInit" SG_ 2153971712 LftglsRelSwAct 2;
BA_ "SignalType" SG_ 2153971712 LftglsRelSwAct "BLN";
BA_ "SignalLongName" SG_ 2153971712 LftglsRelSwAct "Liftglass Release Switch Active";
BA_ "VNSigAllNodes" SG_ 2153971712 LftglsRelSwAct 1;
BA_ "GenSigSendType" SG_ 2153971712 LftglsAjrSwAct 10;
BA_ "GenSigSendOnInit" SG_ 2153971712 LftglsAjrSwAct 2;
BA_ "SignalType" SG_ 2153971712 LftglsAjrSwAct "BLN";
BA_ "SignalLongName" SG_ 2153971712 LftglsAjrSwAct "Liftglass Ajar Switch Active";
BA_ "VNSigAllNodes" SG_ 2153971712 LftglsAjrSwAct 1;
BA_ "GenSigSendType" SG_ 2153971712 DDAjrSwAtvM 10;
BA_ "SignalType" SG_ 2153971712 DDAjrSwAtvM "ENM";
BA_ "SignalLongName" SG_ 2153971712 DDAjrSwAtvM "Driver Door Ajar Switch Active Mask";
BA_ "VNSigAllNodes" SG_ 2153971712 DDAjrSwAtvM 1;
BA_ "GenSigSendType" SG_ 2153971712 DDAjrSwAtv 10;
BA_ "GenSigSendOnInit" SG_ 2153971712 DDAjrSwAtv 2;
BA_ "VNSigInfotainment" SG_ 2153971712 DDAjrSwAtv 1;
BA_ "VNSigIntermediate" SG_ 2153971712 DDAjrSwAtv 1;
BA_ "SignalType" SG_ 2153971712 DDAjrSwAtv "BLN";
BA_ "SignalLongName" SG_ 2153971712 DDAjrSwAtv "Driver Door Ajar Switch Active";
BA_ "VNSigAllNodes" SG_ 2153971712 DDAjrSwAtv 1;
BA_ "GenSigSendType" SG_ 2152054784 FuelEconMetDispUnts 10;
BA_ "GenSigSendOnInit" SG_ 2152054784 FuelEconMetDispUnts 1;
BA_ "VNSigInfotainment" SG_ 2152054784 FuelEconMetDispUnts 1;
BA_ "SignalType" SG_ 2152054784 FuelEconMetDispUnts "ENM";
BA_ "SignalLongName" SG_ 2152054784 FuelEconMetDispUnts "Fuel Economy Metric Display Units";
BA_ "VNSigAllNodes" SG_ 2152054784 FuelEconMetDispUnts 1;
BA_ "GenSigSendType" SG_ 2152054784 IntPnlClstrAnmtStat 10;
BA_ "SignalType" SG_ 2152054784 IntPnlClstrAnmtStat "ENM";
BA_ "SignalLongName" SG_ 2152054784 IntPnlClstrAnmtStat "Instrument Panel Cluster Animation Status";
BA_ "VNSigAllNodes" SG_ 2152054784 IntPnlClstrAnmtStat 1;
BA_ "GenSigSendType" SG_ 2152054784 AnmStrtReq 10;
BA_ "SignalType" SG_ 2152054784 AnmStrtReq "ENM";
BA_ "SignalLongName" SG_ 2152054784 AnmStrtReq "Animation Start Request";
BA_ "VNSigAllNodes" SG_ 2152054784 AnmStrtReq 1;
BA_ "SignalType" SG_ 2151505920 PTExPrtclFltManRgnDispPrsnt "BLN";
BA_ "SignalLongName" SG_ 2151505920 PTExPrtclFltManRgnDispPrsnt "Powertrain Exhaust Particle Filter Manual Regen Display Present";
BA_ "VNSigAllNodes" SG_ 2151505920 PTExPrtclFltManRgnDispPrsnt 1;
BA_ "SignalType" SG_ 2151505920 Trp2OdomtrV "ENM";
BA_ "SignalLongName" SG_ 2151505920 Trp2OdomtrV "Trip 2 Odometer Validity";
BA_ "VNSigAllNodes" SG_ 2151505920 Trp2OdomtrV 1;
BA_ "GenSigDeltaValue" SG_ 2151505920 Trp2Odomtr 1;
BA_ "SignalType" SG_ 2151505920 Trp2Odomtr "UNM";
BA_ "SignalLongName" SG_ 2151505920 Trp2Odomtr "Trip 2 Odometer";
BA_ "VNSigAllNodes" SG_ 2151505920 Trp2Odomtr 1;
BA_ "SignalType" SG_ 2151505920 Trp1OdomtrV "ENM";
BA_ "SignalLongName" SG_ 2151505920 Trp1OdomtrV "Trip 1 Odometer Validity";
BA_ "VNSigAllNodes" SG_ 2151505920 Trp1OdomtrV 1;
BA_ "GenSigDeltaValue" SG_ 2151505920 Trp1Odomtr 1;
BA_ "SignalType" SG_ 2151505920 Trp1Odomtr "UNM";
BA_ "SignalLongName" SG_ 2151505920 Trp1Odomtr "Trip 1 Odometer";
BA_ "VNSigAllNodes" SG_ 2151505920 Trp1Odomtr 1;
BA_ "GenSigSendType" SG_ 2151505920 AutoMdSpdLmtCnfrmd 10;
BA_ "SignalType" SG_ 2151505920 AutoMdSpdLmtCnfrmd "BLN";
BA_ "SignalLongName" SG_ 2151505920 AutoMdSpdLmtCnfrmd "Auto Mode Speed Limit Confirmed";
BA_ "VNSigAllNodes" SG_ 2151505920 AutoMdSpdLmtCnfrmd 1;
BA_ "GenSigSendType" SG_ 2151505920 ACCSettingType 10;
BA_ "SignalType" SG_ 2151505920 ACCSettingType "ENM";
BA_ "SignalLongName" SG_ 2151505920 ACCSettingType "Adaptive Cruise Control Setting Type";
BA_ "VNSigAllNodes" SG_ 2151505920 ACCSettingType 1;
BA_ "GenSigSendType" SG_ 2151505920 TrlrBrkDsplyAct 10;
BA_ "GenSigSendOnInit" SG_ 2151505920 TrlrBrkDsplyAct 1;
BA_ "SignalType" SG_ 2151505920 TrlrBrkDsplyAct "BLN";
BA_ "SignalLongName" SG_ 2151505920 TrlrBrkDsplyAct "Trailer Brake Display Active";
BA_ "VNSigAllNodes" SG_ 2151505920 TrlrBrkDsplyAct 1;
BA_ "GenSigSendType" SG_ 2151505920 SpdCurvAdvSysEnbld 10;
BA_ "SignalType" SG_ 2151505920 SpdCurvAdvSysEnbld "BLN";
BA_ "SignalLongName" SG_ 2151505920 SpdCurvAdvSysEnbld "Speed and Curve Advisory System Enabled";
BA_ "VNSigAllNodes" SG_ 2151505920 SpdCurvAdvSysEnbld 1;
BA_ "GenSigSendType" SG_ 2151505920 PTExPrtclFltManRgnRqd 10;
BA_ "SignalType" SG_ 2151505920 PTExPrtclFltManRgnRqd "BLN";
BA_ "SignalLongName" SG_ 2151505920 PTExPrtclFltManRgnRqd "Powertrain Exhaust Particle Filter Manual Regeneration Requested";
BA_ "VNSigAllNodes" SG_ 2151505920 PTExPrtclFltManRgnRqd 1;
BA_ "SignalType" SG_ 2150424576 ExtHlStrAssCsCrStVal "ENM";
BA_ "SignalLongName" SG_ 2150424576 ExtHlStrAssCsCrStVal "Extended Hill Start Assist Customization Current Setting Value";
BA_ "VNSigAllNodes" SG_ 2150424576 ExtHlStrAssCsCrStVal 1;
BA_ "SignalType" SG_ 2150424576 ExtHlStrAssCsStAvl "BLN";
BA_ "SignalLongName" SG_ 2150424576 ExtHlStrAssCsStAvl "Extended Hill Start Assist Customization Setting Available";
BA_ "VNSigAllNodes" SG_ 2150424576 ExtHlStrAssCsStAvl 1;
BA_ "SignalType" SG_ 2150424576 RrAxlELSDCplLwResV "ENM";
BA_ "SignalLongName" SG_ 2150424576 RrAxlELSDCplLwResV "Rear Axle Electronic Limited Slip Differential Coupling Low Resolution Validity";
BA_ "VNSigAllNodes" SG_ 2150424576 RrAxlELSDCplLwResV 1;
BA_ "SignalType" SG_ 2150424576 RrAxlELSDCplLwRes "UNM";
BA_ "SignalLongName" SG_ 2150424576 RrAxlELSDCplLwRes "Rear Axle Electronic Limited Slip Differential Coupling Low Resolution";
BA_ "VNSigAllNodes" SG_ 2150424576 RrAxlELSDCplLwRes 1;
BA_ "SignalType" SG_ 2150424576 EngTrqDrRqdExtRngV "ENM";
BA_ "SignalLongName" SG_ 2150424576 EngTrqDrRqdExtRngV "Engine Torque Driver Requested Extended Range Validity";
BA_ "VNSigAllNodes" SG_ 2150424576 EngTrqDrRqdExtRngV 1;
BA_ "SignalType" SG_ 2150424576 EngTrqDrRqdExtRng "UNM";
BA_ "SignalLongName" SG_ 2150424576 EngTrqDrRqdExtRng "Engine Torque Driver Requested Extended Range";
BA_ "GenSigStartValue" SG_ 2150424576 EngTrqDrRqdExtRng 1696;
BA_ "VNSigAllNodes" SG_ 2150424576 EngTrqDrRqdExtRng 1;
BA_ "SignalType" SG_ 2150424576 EngAirIntBstPrV "ENM";
BA_ "SignalLongName" SG_ 2150424576 EngAirIntBstPrV "Engine Intake Air Boost Pressure Validity";
BA_ "VNSigAllNodes" SG_ 2150424576 EngAirIntBstPrV 1;
BA_ "SignalType" SG_ 2150424576 TrnsRngInhbtStat "ENM";
BA_ "SignalLongName" SG_ 2150424576 TrnsRngInhbtStat "Transmission Range Inhibit Status";
BA_ "VNSigAllNodes" SG_ 2150424576 TrnsRngInhbtStat 1;
BA_ "SignalType" SG_ 2150424576 DrvtShftCntrlTrgtGear "ENM";
BA_ "SignalLongName" SG_ 2150424576 DrvtShftCntrlTrgtGear "Driver Shift Control Target Gear";
BA_ "VNSigAllNodes" SG_ 2150424576 DrvtShftCntrlTrgtGear 1;
BA_ "SignalType" SG_ 2150424576 EngAirIntBstPr "SNM";
BA_ "SignalLongName" SG_ 2150424576 EngAirIntBstPr "Engine Intake Air Boost Pressure";
BA_ "VNSigAllNodes" SG_ 2150424576 EngAirIntBstPr 1;
BA_ "SignalType" SG_ 2150424576 ACCmpNrmLdGrdAld "UNM";
BA_ "SignalLongName" SG_ 2150424576 ACCmpNrmLdGrdAld "Air Conditioning Compressor Normalized Load Gradient Allowed";
BA_ "VNSigAllNodes" SG_ 2150424576 ACCmpNrmLdGrdAld 1;
BA_ "SignalType" SG_ 2150424576 TrnsEngdStateV "ENM";
BA_ "SignalLongName" SG_ 2150424576 TrnsEngdStateV "Transmission Engaged State Validity";
BA_ "VNSigAllNodes" SG_ 2150424576 TrnsEngdStateV 1;
BA_ "SignalType" SG_ 2150424576 ACRfHiSdFldPrsV "ENM";
BA_ "SignalLongName" SG_ 2150424576 ACRfHiSdFldPrsV "Air Conditioning Refrigerant High Side Fluid Pressure Validity";
BA_ "VNSigAllNodes" SG_ 2150424576 ACRfHiSdFldPrsV 1;
BA_ "SignalType" SG_ 2150424576 ACRfHiSdFldPrs "UNM";
BA_ "SignalLongName" SG_ 2150424576 ACRfHiSdFldPrs "Air Conditioning Refrigerant High Side Fluid Pressure";
BA_ "VNSigAllNodes" SG_ 2150424576 ACRfHiSdFldPrs 1;
BA_ "SignalType" SG_ 2150424576 ACCompCmnd "ENM";
BA_ "SignalLongName" SG_ 2150424576 ACCompCmnd "Air Conditioning Compressor Command";
BA_ "VNSigAllNodes" SG_ 2150424576 ACCompCmnd 1;
BA_ "SignalType" SG_ 2150424576 TrnsEngdState "ENM";
BA_ "SignalLongName" SG_ 2150424576 TrnsEngdState "Transmission Engaged State";
BA_ "VNSigAllNodes" SG_ 2150424576 TrnsEngdState 1;
BA_ "SignalType" SG_ 2150416384 PTWrmgWtToShftIO "BLN";
BA_ "SignalLongName" SG_ 2150416384 PTWrmgWtToShftIO "Powertrain Warming Wait To Shift Indication On";
BA_ "VNSigAllNodes" SG_ 2150416384 PTWrmgWtToShftIO 1;
BA_ "SignalType" SG_ 2150416384 EngTrqActExtRngV "ENM";
BA_ "SignalLongName" SG_ 2150416384 EngTrqActExtRngV "Engine Torque Actual Extended Range Validity";
BA_ "VNSigAllNodes" SG_ 2150416384 EngTrqActExtRngV 1;
BA_ "SignalType" SG_ 2150416384 VehTopSpdLmtMdAct "BLN";
BA_ "SignalLongName" SG_ 2150416384 VehTopSpdLmtMdAct "Vehicle Top Speed Limit Mode Active";
BA_ "VNSigAllNodes" SG_ 2150416384 VehTopSpdLmtMdAct 1;
BA_ "SignalType" SG_ 2150416384 EngTrqActExtRng "UNM";
BA_ "SignalLongName" SG_ 2150416384 EngTrqActExtRng "Engine Torque Actual Extended Range";
BA_ "GenSigStartValue" SG_ 2150416384 EngTrqActExtRng 1696;
BA_ "VNSigAllNodes" SG_ 2150416384 EngTrqActExtRng 1;
BA_ "SignalType" SG_ 2150416384 EngRunAtv "BLN";
BA_ "SignalLongName" SG_ 2150416384 EngRunAtv "Engine Run Active";
BA_ "VNSigAllNodes" SG_ 2150416384 EngRunAtv 1;
BA_ "SignalType" SG_ 2150416384 EngIdlAtv "BLN";
BA_ "SignalLongName" SG_ 2150416384 EngIdlAtv "Engine Idle Active";
BA_ "VNSigAllNodes" SG_ 2150416384 EngIdlAtv 1;
BA_ "SignalType" SG_ 2150416384 EngSpdStat "ENM";
BA_ "SignalLongName" SG_ 2150416384 EngSpdStat "Engine Speed Status";
BA_ "VNSigAllNodes" SG_ 2150416384 EngSpdStat 1;
BA_ "SignalType" SG_ 2150416384 VaccBoostFailure "BLN";
BA_ "SignalLongName" SG_ 2150416384 VaccBoostFailure "Vaccum Boost Failure";
BA_ "VNSigAllNodes" SG_ 2150416384 VaccBoostFailure 1;
BA_ "SignalType" SG_ 2150416384 RmVhStrtEngRng "BLN";
BA_ "SignalLongName" SG_ 2150416384 RmVhStrtEngRng "Remote Vehicle Start Engine Running";
BA_ "VNSigAllNodes" SG_ 2150416384 RmVhStrtEngRng 1;
BA_ "SignalType" SG_ 2150416384 EngCoolFanSpd "UNM";
BA_ "SignalLongName" SG_ 2150416384 EngCoolFanSpd "Engine Cooling Fan Speed";
BA_ "VNSigAllNodes" SG_ 2150416384 EngCoolFanSpd 1;
BA_ "SignalType" SG_ 2150416384 TrnsVDA "ENM";
BA_ "SignalLongName" SG_ 2150416384 TrnsVDA "Transmission Virtual Device Availability";
BA_ "GenSigStartValue" SG_ 2150416384 TrnsVDA 1;
BA_ "VNSigAllNodes" SG_ 2150416384 TrnsVDA 1;
BA_ "SignalType" SG_ 2150416384 GenFld "BLN";
BA_ "SignalLongName" SG_ 2150416384 GenFld "Generator Failed";
BA_ "VNSigAllNodes" SG_ 2150416384 GenFld 1;
BA_ "SignalType" SG_ 2150416384 EngSpdLmtnMdAct "BLN";
BA_ "SignalLongName" SG_ 2150416384 EngSpdLmtnMdAct "Engine Speed Limitation Mode Active";
BA_ "VNSigAllNodes" SG_ 2150416384 EngSpdLmtnMdAct 1;
BA_ "SignalType" SG_ 2150416384 EngNEmsnsRelMalfAct "BLN";
BA_ "SignalLongName" SG_ 2150416384 EngNEmsnsRelMalfAct "Engine Non Emissions Related Malfunction Active";
BA_ "VNSigAllNodes" SG_ 2150416384 EngNEmsnsRelMalfAct 1;
BA_ "SignalType" SG_ 2150416384 EngCstFlCutAct "BLN";
BA_ "SignalLongName" SG_ 2150416384 EngCstFlCutAct "Engine Coast Fuel Cut Off Active";
BA_ "VNSigAllNodes" SG_ 2150416384 EngCstFlCutAct 1;
BA_ "SignalType" SG_ 2150416384 EngCylDeactMd "ENM";
BA_ "SignalLongName" SG_ 2150416384 EngCylDeactMd "Engine Cylinder Deactivation Mode";
BA_ "VNSigAllNodes" SG_ 2150416384 EngCylDeactMd 1;
BA_ "SignalType" SG_ 2150416384 EngBstPrsIndV "ENM";
BA_ "SignalLongName" SG_ 2150416384 EngBstPrsIndV "Engine Boost Pressure Indication Validity";
BA_ "VNSigAllNodes" SG_ 2150416384 EngBstPrsIndV 1;
BA_ "SignalType" SG_ 2150416384 EngBstPrsInd "UNM";
BA_ "SignalLongName" SG_ 2150416384 EngBstPrsInd "Engine Boost Pressure Indication";
BA_ "VNSigAllNodes" SG_ 2150416384 EngBstPrsInd 1;
BA_ "SignalType" SG_ 2150416384 TransEstGear "ENM";
BA_ "SignalLongName" SG_ 2150416384 TransEstGear "Transmission Estimated Gear";
BA_ "GenSigStartValue" SG_ 2150416384 TransEstGear 15;
BA_ "VNSigAllNodes" SG_ 2150416384 TransEstGear 1;
BA_ "SignalType" SG_ 2150416384 TransEstGearV "ENM";
BA_ "SignalLongName" SG_ 2150416384 TransEstGearV "Transmission Estimated Gear Validity";
BA_ "VNSigAllNodes" SG_ 2150416384 TransEstGearV 1;
BA_ "SignalType" SG_ 2150416384 EngVDA "ENM";
BA_ "SignalLongName" SG_ 2150416384 EngVDA "Engine Virtual Device Availability";
BA_ "GenSigStartValue" SG_ 2150416384 EngVDA 1;
BA_ "VNSigAllNodes" SG_ 2150416384 EngVDA 1;
BA_ "SignalType" SG_ 2150416384 TrnCrpMdAtv "BLN";
BA_ "SignalLongName" SG_ 2150416384 TrnCrpMdAtv "Transmission Creep Mode Active";
BA_ "VNSigAllNodes" SG_ 2150416384 TrnCrpMdAtv 1;
BA_ "SignalType" SG_ 2150416384 VehTopSpdLmtArbVal "UNM";
BA_ "SignalLongName" SG_ 2150416384 VehTopSpdLmtArbVal "Vehicle Top Speed Limit Arbitrated Value";
BA_ "VNSigAllNodes" SG_ 2150416384 VehTopSpdLmtArbVal 1;
BA_ "SignalType" SG_ 2150408192 ElcRngSelDrvAct "BLN";
BA_ "SignalLongName" SG_ 2150408192 ElcRngSelDrvAct "Electronic Range Selection In Drive Active";
BA_ "VNSigAllNodes" SG_ 2150408192 ElcRngSelDrvAct 1;
BA_ "SignalType" SG_ 2150408192 TmpDrvrShftCtlAct "BLN";
BA_ "SignalLongName" SG_ 2150408192 TmpDrvrShftCtlAct "Temporary Driver Shift Control Active";
BA_ "VNSigAllNodes" SG_ 2150408192 TmpDrvrShftCtlAct 1;
BA_ "SignalType" SG_ 2150408192 AdptPsngrSeatStng "ENM";
BA_ "SignalLongName" SG_ 2150408192 AdptPsngrSeatStng "Adaptive Passenger Seat Setting";
BA_ "VNSigAllNodes" SG_ 2150408192 AdptPsngrSeatStng 1;
BA_ "SignalType" SG_ 2150408192 EngRunng "BLN";
BA_ "SignalLongName" SG_ 2150408192 EngRunng "Engine Running";
BA_ "VNSigAllNodes" SG_ 2150408192 EngRunng 1;
BA_ "SignalType" SG_ 2150408192 Eng12vStrtrMtrCmmdOn "BLN";
BA_ "SignalLongName" SG_ 2150408192 Eng12vStrtrMtrCmmdOn "Engine 12 Volt Starter Motor Commanded On";
BA_ "VNSigAllNodes" SG_ 2150408192 Eng12vStrtrMtrCmmdOn 1;
BA_ "SignalType" SG_ 2150408192 AccPdlOvrrdAtv "BLN";
BA_ "SignalLongName" SG_ 2150408192 AccPdlOvrrdAtv "Accelerator Pedal Override Active";
BA_ "VNSigAllNodes" SG_ 2150408192 AccPdlOvrrdAtv 1;
BA_ "SignalType" SG_ 2150408192 TopTrvlCltchSwActV "ENM";
BA_ "SignalLongName" SG_ 2150408192 TopTrvlCltchSwActV "Top of Travel Clutch Switch Active Validity";
BA_ "VNSigAllNodes" SG_ 2150408192 TopTrvlCltchSwActV 1;
BA_ "SignalType" SG_ 2150408192 TopTrvlCltchSwAct "BLN";
BA_ "SignalLongName" SG_ 2150408192 TopTrvlCltchSwAct "Top of Travel Clutch Switch Active";
BA_ "VNSigAllNodes" SG_ 2150408192 TopTrvlCltchSwAct 1;
BA_ "SignalType" SG_ 2150408192 CltStartSwAtvV "ENM";
BA_ "SignalLongName" SG_ 2150408192 CltStartSwAtvV "Clutch Start Switch Active Validity";
BA_ "VNSigAllNodes" SG_ 2150408192 CltStartSwAtvV 1;
BA_ "SignalType" SG_ 2150408192 CltStartSwAtv "BLN";
BA_ "SignalLongName" SG_ 2150408192 CltStartSwAtv "Clutch Start Switch Active";
BA_ "GenSigStartValue" SG_ 2150408192 CltStartSwAtv 1;
BA_ "VNSigAllNodes" SG_ 2150408192 CltStartSwAtv 1;
BA_ "GenSigSendOnInit" SG_ 2150408192 CrsCntEnbld 1;
BA_ "SignalType" SG_ 2150408192 CrsCntEnbld "BLN";
BA_ "SignalLongName" SG_ 2150408192 CrsCntEnbld "Cruise Control Enabled";
BA_ "VNSigAllNodes" SG_ 2150408192 CrsCntEnbld 1;
BA_ "SignalType" SG_ 2150408192 AccActPosV "ENM";
BA_ "SignalLongName" SG_ 2150408192 AccActPosV "Accelerator Actual Position Validity";
BA_ "VNSigAllNodes" SG_ 2150408192 AccActPosV 1;
BA_ "SignalType" SG_ 2150408192 TrnsShftLvrPosV "ENM";
BA_ "SignalLongName" SG_ 2150408192 TrnsShftLvrPosV "Transmission Shift Lever Position Validity";
BA_ "VNSigAllNodes" SG_ 2150408192 TrnsShftLvrPosV 1;
BA_ "SignalType" SG_ 2150408192 TrnsSftMdStat "ENM";
BA_ "SignalLongName" SG_ 2150408192 TrnsSftMdStat "Transmission Shift Mode Status";
BA_ "VNSigAllNodes" SG_ 2150408192 TrnsSftMdStat 1;
BA_ "SignalType" SG_ 2150408192 EngSpd "UNM";
BA_ "SignalLongName" SG_ 2150408192 EngSpd "Engine Speed";
BA_ "VNSigAllNodes" SG_ 2150408192 EngSpd 1;
BA_ "SignalType" SG_ 2150408192 AutoTransComndGear "ENM";
BA_ "SignalLongName" SG_ 2150408192 AutoTransComndGear "Automatic Transmission Commanded Gear";
BA_ "GenSigStartValue" SG_ 2150408192 AutoTransComndGear 15;
BA_ "VNSigAllNodes" SG_ 2150408192 AutoTransComndGear 1;
BA_ "SignalType" SG_ 2150408192 TrnShftPtrnActStat "ENM";
BA_ "SignalLongName" SG_ 2150408192 TrnShftPtrnActStat "Transmission Shift Pattern Active Status";
BA_ "VNSigAllNodes" SG_ 2150408192 TrnShftPtrnActStat 1;
BA_ "SignalType" SG_ 2150408192 TrnsShftLvrPos "ENM";
BA_ "SignalLongName" SG_ 2150408192 TrnsShftLvrPos "Transmission Shift Lever Position";
BA_ "VNSigAllNodes" SG_ 2150408192 TrnsShftLvrPos 1;
BA_ "SignalType" SG_ 2150408192 AccActPos "UNM";
BA_ "SignalLongName" SG_ 2150408192 AccActPos "Accelerator Actual Position";
BA_ "VNSigAllNodes" SG_ 2150408192 AccActPos 1;
BA_ "SignalType" SG_ 2150408192 ThrPosV "ENM";
BA_ "SignalLongName" SG_ 2150408192 ThrPosV "Throttle Position Validity";
BA_ "VNSigAllNodes" SG_ 2150408192 ThrPosV 1;
BA_ "SignalType" SG_ 2150408192 TransTUDMdStat "ENM";
BA_ "SignalLongName" SG_ 2150408192 TransTUDMdStat "Transmission Tap Up/Tap Down Mode Status";
BA_ "VNSigAllNodes" SG_ 2150408192 TransTUDMdStat 1;
BA_ "SignalType" SG_ 2150408192 ThrPos "UNM";
BA_ "SignalLongName" SG_ 2150408192 ThrPos "Throttle Position";
BA_ "VNSigAllNodes" SG_ 2150408192 ThrPos 1;
BA_ "SignalType" SG_ 2149990400 ElcTransRngRq "ENM";
BA_ "SignalLongName" SG_ 2149990400 ElcTransRngRq "Electronic Transmission Range Request";
BA_ "VNSigAllNodes" SG_ 2149990400 ElcTransRngRq 1;
BA_ "SignalType" SG_ 2149990400 TrnsfrCsRngShfSpdLmt "UNM";
BA_ "SignalLongName" SG_ 2149990400 TrnsfrCsRngShfSpdLmt "Transfer Case Range Shift Speed Limit";
BA_ "VNSigAllNodes" SG_ 2149990400 TrnsfrCsRngShfSpdLmt 1;
BA_ "SignalType" SG_ 2149990400 TrlrBrkngVDA "ENM";
BA_ "SignalLongName" SG_ 2149990400 TrlrBrkngVDA "Trailer Braking Virtual Device Availability";
BA_ "GenSigStartValue" SG_ 2149990400 TrlrBrkngVDA 1;
BA_ "VNSigAllNodes" SG_ 2149990400 TrlrBrkngVDA 1;
BA_ "SignalType" SG_ 2149990400 SecAxlOperMod "ENM";
BA_ "SignalLongName" SG_ 2149990400 SecAxlOperMod "Secondary Axle Operational Mode";
BA_ "VNSigAllNodes" SG_ 2149990400 SecAxlOperMod 1;
BA_ "SignalType" SG_ 2149990400 InstFuelConsmpRate "UNM";
BA_ "SignalLongName" SG_ 2149990400 InstFuelConsmpRate "Instantaneous Fuel Consumption Rate";
BA_ "VNSigAllNodes" SG_ 2149990400 InstFuelConsmpRate 1;
BA_ "SignalType" SG_ 2149990400 MotStBltUnblIO "BLN";
BA_ "SignalLongName" SG_ 2149990400 MotStBltUnblIO "Motorized Seat Belt Unavailable Indication On";
BA_ "VNSigAllNodes" SG_ 2149990400 MotStBltUnblIO 1;
BA_ "SignalType" SG_ 2149990400 MotStBltFldIO "BLN";
BA_ "SignalLongName" SG_ 2149990400 MotStBltFldIO "Motorized Seat Belt Failed Indication On";
BA_ "VNSigAllNodes" SG_ 2149990400 MotStBltFldIO 1;
BA_ "SignalType" SG_ 2149990400 TransNtrlCntrlMdStat "ENM";
BA_ "SignalLongName" SG_ 2149990400 TransNtrlCntrlMdStat "Transmission Neutral Control Mode Status";
BA_ "VNSigAllNodes" SG_ 2149990400 TransNtrlCntrlMdStat 1;
BA_ "SignalType" SG_ 2149990400 TrlrWiringFltIO "BLN";
BA_ "SignalLongName" SG_ 2149990400 TrlrWiringFltIO "Trailer Wiring Fault Indication On";
BA_ "VNSigAllNodes" SG_ 2149990400 TrlrWiringFltIO 1;
BA_ "SignalType" SG_ 2149990400 TrlrCnctdIO "BLN";
BA_ "SignalLongName" SG_ 2149990400 TrlrCnctdIO "Trailer Connected Indication On";
BA_ "VNSigAllNodes" SG_ 2149990400 TrlrCnctdIO 1;
BA_ "SignalType" SG_ 2149990400 TrlrBrkngGainSetIO "BLN";
BA_ "SignalLongName" SG_ 2149990400 TrlrBrkngGainSetIO "Trailer Braking Gain Setting Indication On";
BA_ "VNSigAllNodes" SG_ 2149990400 TrlrBrkngGainSetIO 1;
BA_ "SignalType" SG_ 2149990400 TrlrBrkngGainSet "UNM";
BA_ "SignalLongName" SG_ 2149990400 TrlrBrkngGainSet "Trailer Braking Gain Setting";
BA_ "VNSigAllNodes" SG_ 2149990400 TrlrBrkngGainSet 1;
BA_ "SignalType" SG_ 2149990400 TrlrBrkngFrcOtpt "UNM";
BA_ "SignalLongName" SG_ 2149990400 TrlrBrkngFrcOtpt "Trailer Braking Force Output";
BA_ "VNSigAllNodes" SG_ 2149990400 TrlrBrkngFrcOtpt 1;
BA_ "SignalType" SG_ 2149990400 SrvTrlrBrkngSysIO "BLN";
BA_ "SignalLongName" SG_ 2149990400 SrvTrlrBrkngSysIO "ServiceTrailer Braking System Indication On";
BA_ "VNSigAllNodes" SG_ 2149990400 SrvTrlrBrkngSysIO 1;
BA_ "SignalType" SG_ 2149990400 ChkTrlrIO "BLN";
BA_ "SignalLongName" SG_ 2149990400 ChkTrlrIO "Check Trailer Indication On";
BA_ "VNSigAllNodes" SG_ 2149990400 ChkTrlrIO 1;
BA_ "SignalType" SG_ 2149990400 ScndryAxleVDA "ENM";
BA_ "SignalLongName" SG_ 2149990400 ScndryAxleVDA "Secondary Axle Virtual Device Availability";
BA_ "GenSigStartValue" SG_ 2149990400 ScndryAxleVDA 1;
BA_ "VNSigAllNodes" SG_ 2149990400 ScndryAxleVDA 1;
BA_ "SignalType" SG_ 2149990400 TrlrHtchSwAtv_ITBC "BLN";
BA_ "SignalLongName" SG_ 2149990400 TrlrHtchSwAtv_ITBC "Trailer Hitch Switch Active ITBC";
BA_ "VNSigAllNodes" SG_ 2149990400 TrlrHtchSwAtv_ITBC 1;
BA_ "SignalType" SG_ 2149990400 AdvHlmpsVDA "ENM";
BA_ "SignalLongName" SG_ 2149990400 AdvHlmpsVDA "Advance Headlamps Virtual Device Availability";
BA_ "GenSigStartValue" SG_ 2149990400 AdvHlmpsVDA 1;
BA_ "VNSigAllNodes" SG_ 2149990400 AdvHlmpsVDA 1;
BA_ "SignalType" SG_ 2149990400 ABSIO "BLN";
BA_ "SignalLongName" SG_ 2149990400 ABSIO "Antilock Brake System Indication On";
BA_ "VNSigAllNodes" SG_ 2149990400 ABSIO 1;
BA_ "SignalType" SG_ 2149990400 ACCHdwayStngIO "BLN";
BA_ "SignalLongName" SG_ 2149990400 ACCHdwayStngIO "Adaptive Cruise Control Headway Setting Indication On";
BA_ "VNSigAllNodes" SG_ 2149990400 ACCHdwayStngIO 1;
BA_ "SignalType" SG_ 2149990400 StpOnBrkToRelPBIndOn "BLN";
BA_ "SignalLongName" SG_ 2149990400 StpOnBrkToRelPBIndOn "Step On Brake To Release Park Brake Indication On";
BA_ "VNSigAllNodes" SG_ 2149990400 StpOnBrkToRelPBIndOn 1;
BA_ "SignalType" SG_ 2149990400 SADmpVDA "ENM";
BA_ "SignalLongName" SG_ 2149990400 SADmpVDA "Semi Active Damping Virtual Device Availability";
BA_ "GenSigStartValue" SG_ 2149990400 SADmpVDA 1;
BA_ "VNSigAllNodes" SG_ 2149990400 SADmpVDA 1;
BA_ "SignalType" SG_ 2149990400 ACCDrvrSeltdSpdIO "BLN";
BA_ "SignalLongName" SG_ 2149990400 ACCDrvrSeltdSpdIO "Adaptive Cruise Control Driver Selected Speed Indication On";
BA_ "VNSigAllNodes" SG_ 2149990400 ACCDrvrSeltdSpdIO 1;
BA_ "SignalType" SG_ 2149990400 TreInfMonSysRstPrfmd "BLN";
BA_ "SignalLongName" SG_ 2149990400 TreInfMonSysRstPrfmd "Tire Inflation Monitoring System Reset Performed";
BA_ "VNSigAllNodes" SG_ 2149990400 TreInfMonSysRstPrfmd 1;
BA_ "SignalType" SG_ 2149990400 DrvThrtlOvrdIO "BLN";
BA_ "SignalLongName" SG_ 2149990400 DrvThrtlOvrdIO "Driver Throttle Override Indication On";
BA_ "VNSigAllNodes" SG_ 2149990400 DrvThrtlOvrdIO 1;
BA_ "SignalType" SG_ 2149842944 AdptDrvrSeatStng "ENM";
BA_ "SignalLongName" SG_ 2149842944 AdptDrvrSeatStng "Adaptive Driver Seat Setting";
BA_ "VNSigAllNodes" SG_ 2149842944 AdptDrvrSeatStng 1;
BA_ "SignalType" SG_ 2149842944 VSELatAccV "ENM";
BA_ "SignalLongName" SG_ 2149842944 VSELatAccV "Vehicle Stability Enhancement Lateral Acceleration Validity";
BA_ "VNSigAllNodes" SG_ 2149842944 VSELatAccV 1;
BA_ "SignalType" SG_ 2149842944 VSELatAcc "SNM";
BA_ "SignalLongName" SG_ 2149842944 VSELatAcc "Vehicle Stability Enhancement Lateral Acceleration";
BA_ "VNSigAllNodes" SG_ 2149842944 VSELatAcc 1;
BA_ "SignalType" SG_ 2149842944 StrWhAngV "ENM";
BA_ "SignalLongName" SG_ 2149842944 StrWhAngV "Steering Wheel Angle Validity";
BA_ "VNSigAllNodes" SG_ 2149842944 StrWhAngV 1;
BA_ "SignalType" SG_ 2149842944 TCSysAtv "BLN";
BA_ "SignalLongName" SG_ 2149842944 TCSysAtv "Traction Control System Active";
BA_ "VNSigAllNodes" SG_ 2149842944 TCSysAtv 1;
BA_ "SignalType" SG_ 2149842944 BrkSysAutBrkFld "BLN";
BA_ "SignalLongName" SG_ 2149842944 BrkSysAutBrkFld "Brake System Automatic Braking Failed";
BA_ "VNSigAllNodes" SG_ 2149842944 BrkSysAutBrkFld 1;
BA_ "SignalType" SG_ 2149842944 StrWhlAngSenCalStat "ENM";
BA_ "SignalLongName" SG_ 2149842944 StrWhlAngSenCalStat "Steering Wheel Angle Sensor Calibration Status";
BA_ "VNSigAllNodes" SG_ 2149842944 StrWhlAngSenCalStat 1;
BA_ "SignalType" SG_ 2149842944 VehStabEnhmntStat "ENM";
BA_ "SignalLongName" SG_ 2149842944 VehStabEnhmntStat "Vehicle Stability Enhancement Status";
BA_ "VNSigAllNodes" SG_ 2149842944 VehStabEnhmntStat 1;
BA_ "SignalType" SG_ 2149842944 VehStabEnhmntMd "ENM";
BA_ "SignalLongName" SG_ 2149842944 VehStabEnhmntMd "Vehicle Stability Enhancement Mode";
BA_ "VNSigAllNodes" SG_ 2149842944 VehStabEnhmntMd 1;
BA_ "SignalType" SG_ 2149842944 VSEAct "BLN";
BA_ "SignalLongName" SG_ 2149842944 VSEAct "Vehicle Stability Enhancement System Active";
BA_ "VNSigAllNodes" SG_ 2149842944 VSEAct 1;
BA_ "SignalType" SG_ 2149842944 TCSysOpStat "ENM";
BA_ "SignalLongName" SG_ 2149842944 TCSysOpStat "Traction Control System Operating Status";
BA_ "VNSigAllNodes" SG_ 2149842944 TCSysOpStat 1;
BA_ "SignalType" SG_ 2149842944 TCSysOpMd "ENM";
BA_ "SignalLongName" SG_ 2149842944 TCSysOpMd "Traction Control System Operating Mode";
BA_ "VNSigAllNodes" SG_ 2149842944 TCSysOpMd 1;
BA_ "SignalType" SG_ 2149842944 StWhAnVDA "ENM";
BA_ "SignalLongName" SG_ 2149842944 StWhAnVDA "Steering Wheel Angle Virtual Device Availability";
BA_ "GenSigStartValue" SG_ 2149842944 StWhAnVDA 1;
BA_ "VNSigAllNodes" SG_ 2149842944 StWhAnVDA 1;
BA_ "SignalType" SG_ 2149842944 StrWhAng "SNM";
BA_ "SignalLongName" SG_ 2149842944 StrWhAng "Steering Wheel Angle";
BA_ "VNSigAllNodes" SG_ 2149842944 StrWhAng 1;
BA_ "SignalType" SG_ 2149842944 IMUProtLonAcc "SNM";
BA_ "SignalLongName" SG_ 2149842944 IMUProtLonAcc "Inertial Measurement Unit Protected Longitudinal Acceleration";
BA_ "VNSigAllNodes" SG_ 2149842944 IMUProtLonAcc 1;
BA_ "SignalType" SG_ 2149842944 IMUProtLonAccV "ENM";
BA_ "SignalLongName" SG_ 2149842944 IMUProtLonAccV "Inertial Measurement Unit Protected Longitudinal Acceleration Validity";
BA_ "VNSigAllNodes" SG_ 2149842944 IMUProtLonAccV 1;
BA_REL_ "GenSigSuprvResp" BU_SG_REL_ LVMPC_LE SG_ 2156789760 TOD_SecofMin 1;
BA_REL_ "GenSigSuprvResp" BU_SG_REL_ LVMPC_LE SG_ 2156789760 TOD_MinofHr 1;
BA_REL_ "GenSigSuprvResp" BU_SG_REL_ LVMPC_LE SG_ 2156789760 TOD_HrofDay 1;
BA_REL_ "GenSigRxStartValue" BU_SG_REL_ RadioHead_LE SG_ 2151956480 StrWhlThbwhlCnts "0";
BA_REL_ "GenSigSuprvResp" BU_SG_REL_ CSM_LE SG_ 2151956480 ClstrHMIRdy 1;
BA_REL_ "GenSigSuprvResp" BU_SG_REL_ CSM_LE SG_ 2151956480 ClstrHMIAnmSt 1;
BA_REL_ "GenSigSuprvResp" BU_SG_REL_ VCU_LE SG_ 2150268928 EmrgncyRspSysSrvIndOn 1;
BA_REL_ "GenSigSuprvResp" BU_SG_REL_ IPC_LE SG_ 2150268928 EmrgncyRspSysSrvIndOn 1;
BA_REL_ "GenSigSuprvResp" BU_SG_REL_ V2V_LE SG_ 2150268928 CldrYr_154 1;
BA_REL_ "GenSigSuprvResp" BU_SG_REL_ V2V_LE SG_ 2150268928 CldrMth_154 1;
BA_REL_ "GenSigSuprvResp" BU_SG_REL_ V2V_LE SG_ 2150268928 CldrDay_154 1;
BA_REL_ "GenSigSuprvResp" BU_SG_REL_ V2V_LE SG_ 2150268928 Sec 1;
BA_REL_ "GenSigSuprvResp" BU_SG_REL_ V2V_LE SG_ 2150268928 Mins 1;
BA_REL_ "GenSigSuprvResp" BU_SG_REL_ V2V_LE SG_ 2150268928 Hrs 1;
BA_REL_ "GenSigSuprvResp" BU_SG_REL_ V2V_LE SG_ 2156175360 DispMeasSysExt 1;
BA_REL_ "GenSigSuprvResp" BU_SG_REL_ V2V_LE SG_ 2156175360 DispMeasSys 1;
BA_REL_ "GenSigSuprvResp" BU_SG_REL_ VCU_LE SG_ 2154053632 CargoLmpActIO 1;
BA_REL_ "GenSigSuprvResp" BU_SG_REL_ IPC_LE SG_ 2154053632 CargoLmpActIO 1;
BA_REL_ "GenSigSuprvResp" BU_SG_REL_ RSE_LE SG_ 2154053632 DispNtSchmAtv 1;
BA_REL_ "GenSigSuprvResp" BU_SG_REL_ TouchPad_LE SG_ 2154053632 DispNtSchmAtv 1;
BA_REL_ "GenSigSuprvResp" BU_SG_REL_ ICS_LE SG_ 2154053632 DispNtSchmAtv 1;
BA_REL_ "GenSigSuprvResp" BU_SG_REL_ RSE_LE SG_ 2154053632 IntDimLvl 1;
BA_REL_ "GenSigSuprvResp" BU_SG_REL_ VPM_LE SG_ 2154053632 IntDimLvl 1;
BA_REL_ "GenSigSuprvResp" BU_SG_REL_ TouchPad_LE SG_ 2154053632 IntDimLvl 1;
BA_REL_ "GenSigSuprvResp" BU_SG_REL_ ICS_LE SG_ 2154053632 IntDimLvl 1;
BA_REL_ "GenSigSuprvResp" BU_SG_REL_ VCU_LE SG_ 2154053632 IntDimLvl 1;
BA_REL_ "GenSigSuprvResp" BU_SG_REL_ CHUD_LE SG_ 2154053632 IntDimLvl 1;
BA_REL_ "GenSigSuprvResp" BU_SG_REL_ EDI_LE SG_ 2154053632 IntDimLvl 1;
BA_REL_ "GenSigSuprvResp" BU_SG_REL_ CSM_LE SG_ 2154053632 IntDimLvl 1;
BA_REL_ "GenSigSuprvResp" BU_SG_REL_ RSC_LE SG_ 2154053632 IntDimLvl 1;
BA_REL_ "GenSigSuprvResp" BU_SG_REL_ RSA_LE SG_ 2154053632 IntDimLvl 1;
BA_REL_ "GenSigSuprvResp" BU_SG_REL_ HUD_LE SG_ 2154053632 IntDimLvl 1;
BA_REL_ "GenSigSuprvResp" BU_SG_REL_ IPC_LE SG_ 2154053632 IntDimLvl 1;
BA_REL_ "GenSigSuprvResp" BU_SG_REL_ RadioHead_LE SG_ 2154053632 IntDimLvl 1;
BA_REL_ "GenSigSuprvResp" BU_SG_REL_ RSE_LE SG_ 2154053632 IntDimDspLvl 1;
BA_REL_ "GenSigSuprvResp" BU_SG_REL_ VPM_LE SG_ 2154053632 IntDimDspLvl 1;
BA_REL_ "GenSigSuprvResp" BU_SG_REL_ TouchPad_LE SG_ 2154053632 IntDimDspLvl 1;
BA_REL_ "GenSigSuprvResp" BU_SG_REL_ ICS_LE SG_ 2154053632 IntDimDspLvl 1;
BA_REL_ "GenSigSuprvResp" BU_SG_REL_ VCU_LE SG_ 2154053632 IntDimDspLvl 1;
BA_REL_ "GenSigSuprvResp" BU_SG_REL_ CHUD_LE SG_ 2154053632 IntDimDspLvl 1;
BA_REL_ "GenSigSuprvResp" BU_SG_REL_ EDI_LE SG_ 2154053632 IntDimDspLvl 1;
BA_REL_ "GenSigSuprvResp" BU_SG_REL_ CSM_LE SG_ 2154053632 IntDimDspLvl 1;
BA_REL_ "GenSigSuprvResp" BU_SG_REL_ RSC_LE SG_ 2154053632 IntDimDspLvl 1;
BA_REL_ "GenSigSuprvResp" BU_SG_REL_ RSA_LE SG_ 2154053632 IntDimDspLvl 1;
BA_REL_ "GenSigSuprvResp" BU_SG_REL_ HUD_LE SG_ 2154053632 IntDimDspLvl 1;
BA_REL_ "GenSigSuprvResp" BU_SG_REL_ IPC_LE SG_ 2154053632 IntDimDspLvl 1;
BA_REL_ "GenSigSuprvResp" BU_SG_REL_ RadioHead_LE SG_ 2154053632 IntDimDspLvl 1;
BA_REL_ "GenSigSuprvResp" BU_SG_REL_ ICS_LE SG_ 2154053632 IntDimNtPnlAtv 1;
BA_REL_ "GenSigSuprvResp" BU_SG_REL_ V2V_LE SG_ 2153971712 DDAjrSwAtv 1;
BA_REL_ "GenSigSuprvResp" BU_SG_REL_ TCP_LE SG_ 2153971712 DDAjrSwAtv 1;
BA_REL_ "GenSigSuprvResp" BU_SG_REL_ ONSTAR_LE SG_ 2153971712 DDAjrSwAtv 1;
BA_REL_ "GenSigSuprvResp" BU_SG_REL_ CSM_LE SG_ 2153971712 DDAjrSwAtv 1;
BA_REL_ "GenSigSuprvResp" BU_SG_REL_ RadioHead_LE SG_ 2153971712 DDAjrSwAtv 1;
BA_REL_ "GenSigSuprvResp" BU_SG_REL_ VCU_LE SG_ 2153971712 DDAjrSwAtv 1;
BA_REL_ "GenSigSuprvResp" BU_SG_REL_ VCU_LE SG_ 2153971712 DDAjrSwAtv 1;
BA_REL_ "GenSigSuprvResp" BU_SG_REL_ VCU_LE SG_ 2153971712 DDAjrSwAtv 1;
BA_REL_ "GenSigSuprvResp" BU_SG_REL_ IPC_LE SG_ 2153971712 DDAjrSwAtv 1;
BA_REL_ "GenSigSuprvResp" BU_SG_REL_ IPC_LE SG_ 2153971712 DDAjrSwAtv 1;
BA_REL_ "GenSigSuprvResp" BU_SG_REL_ CSM_LE SG_ 2152054784 FuelEconMetDispUnts 1;
BA_REL_ "GenSigSuprvResp" BU_SG_REL_ CSM_LE SG_ 2152054784 FuelEconMetDispUnts 1;
BA_REL_ "GenSigSuprvResp" BU_SG_REL_ VCU_LE SG_ 2152054784 FuelEconMetDispUnts 1;
BA_REL_ "GenSigSuprvResp" BU_SG_REL_ VCU_LE SG_ 2152054784 FuelEconMetDispUnts 1;
BA_REL_ "GenSigSuprvResp" BU_SG_REL_ RadioHead_LE SG_ 2152054784 FuelEconMetDispUnts 1;
BA_REL_ "GenSigSuprvResp" BU_SG_REL_ RadioHead_LE SG_ 2152054784 FuelEconMetDispUnts 1;
BA_REL_ "GenSigSuprvResp" BU_SG_REL_ VCU_LE SG_ 2150424576 RrAxlELSDCplLwRes 1;
BA_REL_ "GenSigSuprvResp" BU_SG_REL_ IPC_LE SG_ 2150424576 RrAxlELSDCplLwRes 1;
BA_REL_ "GenSigSuprvResp" BU_SG_REL_ VCU_LE SG_ 2150424576 EngTrqDrRqdExtRng 1;
BA_REL_ "GenSigSuprvResp" BU_SG_REL_ IPC_LE SG_ 2150424576 EngTrqDrRqdExtRng 1;
BA_REL_ "GenSigSuprvResp" BU_SG_REL_ CHUD_LE SG_ 2150424576 EngAirIntBstPr 1;
BA_REL_ "GenSigSuprvResp" BU_SG_REL_ HUD_LE SG_ 2150424576 EngAirIntBstPr 1;
BA_REL_ "GenSigSuprvResp" BU_SG_REL_ VCU_LE SG_ 2150416384 PTWrmgWtToShftIO 1;
BA_REL_ "GenSigSuprvResp" BU_SG_REL_ IPC_LE SG_ 2150416384 PTWrmgWtToShftIO 1;
BA_REL_ "GenSigSuprvResp" BU_SG_REL_ VCU_LE SG_ 2150416384 EngTrqActExtRng 1;
BA_REL_ "GenSigSuprvResp" BU_SG_REL_ IPC_LE SG_ 2150416384 EngTrqActExtRng 1;
BA_REL_ "GenSigSuprvResp" BU_SG_REL_ VPM_LE SG_ 2150416384 EngRunAtv 1;
BA_REL_ "GenSigSuprvResp" BU_SG_REL_ TCP_LE SG_ 2150416384 EngRunAtv 1;
BA_REL_ "GenSigSuprvResp" BU_SG_REL_ ONSTAR_LE SG_ 2150416384 EngRunAtv 1;
BA_REL_ "GenSigSuprvResp" BU_SG_REL_ VCU_LE SG_ 2150416384 EngRunAtv 1;
BA_REL_ "GenSigSuprvResp" BU_SG_REL_ VCU_LE SG_ 2150416384 EngRunAtv 1;
BA_REL_ "GenSigSuprvResp" BU_SG_REL_ IPC_LE SG_ 2150416384 EngRunAtv 1;
BA_REL_ "GenSigSuprvResp" BU_SG_REL_ IPC_LE SG_ 2150416384 EngRunAtv 1;
BA_REL_ "GenSigSuprvResp" BU_SG_REL_ LVMNav_LE SG_ 2150416384 EngRunAtv 1;
BA_REL_ "GenSigSuprvResp" BU_SG_REL_ CHUD_LE SG_ 2150416384 EngSpdStat 1;
BA_REL_ "GenSigSuprvResp" BU_SG_REL_ HUD_LE SG_ 2150416384 EngSpdStat 1;
BA_REL_ "GenSigSuprvResp" BU_SG_REL_ CSM_LE SG_ 2150416384 EngSpdStat 1;
BA_REL_ "GenSigSuprvResp" BU_SG_REL_ RadioHead_LE SG_ 2150416384 EngSpdStat 1;
BA_REL_ "GenSigSuprvResp" BU_SG_REL_ RadioHead_LE SG_ 2150416384 EngSpdStat 1;
BA_REL_ "GenSigSuprvResp" BU_SG_REL_ VCU_LE SG_ 2150416384 EngSpdStat 1;
BA_REL_ "GenSigSuprvResp" BU_SG_REL_ VCU_LE SG_ 2150416384 EngSpdStat 1;
BA_REL_ "GenSigSuprvResp" BU_SG_REL_ TCP_LE SG_ 2150416384 RmVhStrtEngRng 1;
BA_REL_ "GenSigSuprvResp" BU_SG_REL_ ONSTAR_LE SG_ 2150416384 RmVhStrtEngRng 1;
BA_REL_ "GenSigSuprvResp" BU_SG_REL_ CSM_LE SG_ 2150416384 EngCylDeactMd 1;
BA_REL_ "GenSigSuprvResp" BU_SG_REL_ RadioHead_LE SG_ 2150416384 EngCylDeactMd 1;
BA_REL_ "GenSigSuprvResp" BU_SG_REL_ RadioHead_LE SG_ 2150416384 EngCylDeactMd 1;
BA_REL_ "GenSigSuprvResp" BU_SG_REL_ VCU_LE SG_ 2150416384 EngCylDeactMd 1;
BA_REL_ "GenSigSuprvResp" BU_SG_REL_ VCU_LE SG_ 2150416384 EngCylDeactMd 1;
BA_REL_ "GenSigSuprvResp" BU_SG_REL_ ICS_LE SG_ 2150416384 TransEstGear 1;
BA_REL_ "GenSigSuprvResp" BU_SG_REL_ CHUD_LE SG_ 2150416384 TransEstGear 1;
BA_REL_ "GenSigSuprvResp" BU_SG_REL_ HUD_LE SG_ 2150416384 TransEstGear 1;
BA_REL_ "GenSigSuprvResp" BU_SG_REL_ VCU_LE SG_ 2150408192 ElcRngSelDrvAct 1;
BA_REL_ "GenSigSuprvResp" BU_SG_REL_ IPC_LE SG_ 2150408192 ElcRngSelDrvAct 1;
BA_REL_ "GenSigSuprvResp" BU_SG_REL_ VCU_LE SG_ 2150408192 TmpDrvrShftCtlAct 1;
BA_REL_ "GenSigSuprvResp" BU_SG_REL_ IPC_LE SG_ 2150408192 TmpDrvrShftCtlAct 1;
BA_REL_ "GenSigSuprvResp" BU_SG_REL_ RSE_LE SG_ 2150408192 EngRunng 1;
BA_REL_ "GenSigSuprvResp" BU_SG_REL_ CSM_LE SG_ 2150408192 CrsCntEnbld 1;
BA_REL_ "GenSigSuprvResp" BU_SG_REL_ RadioHead_LE SG_ 2150408192 CrsCntEnbld 1;
BA_REL_ "GenSigSuprvResp" BU_SG_REL_ RadioHead_LE SG_ 2150408192 CrsCntEnbld 1;
BA_REL_ "GenSigSuprvResp" BU_SG_REL_ VCU_LE SG_ 2150408192 CrsCntEnbld 1;
BA_REL_ "GenSigSuprvResp" BU_SG_REL_ VCU_LE SG_ 2150408192 CrsCntEnbld 1;
BA_REL_ "GenSigSuprvResp" BU_SG_REL_ RSE_LE SG_ 2150408192 EngSpd 1;
BA_REL_ "GenSigSuprvResp" BU_SG_REL_ CHUD_LE SG_ 2150408192 EngSpd 1;
BA_REL_ "GenSigSuprvResp" BU_SG_REL_ HUD_LE SG_ 2150408192 EngSpd 1;
BA_REL_ "GenSigSuprvResp" BU_SG_REL_ VPM_LE SG_ 2149990400 ElcTransRngRq 1;
BA_REL_ "GenSigSuprvResp" BU_SG_REL_ VCU_LE SG_ 2149990400 TrnsfrCsRngShfSpdLmt 1;
BA_REL_ "GenSigSuprvResp" BU_SG_REL_ IPC_LE SG_ 2149990400 TrnsfrCsRngShfSpdLmt 1;
BA_REL_ "GenSigSuprvResp" BU_SG_REL_ VCU_LE SG_ 2149990400 SecAxlOperMod 1;
BA_REL_ "GenSigSuprvResp" BU_SG_REL_ IPC_LE SG_ 2149990400 SecAxlOperMod 1;
BA_REL_ "GenSigVDAFailComment" BU_SG_REL_ VCU_LE SG_ 2149990400 TrlrBrkngGainSetIO "TrlrBrkngVDA";
BA_REL_ "GenSigVDAFailResp" BU_SG_REL_ VCU_LE SG_ 2149990400 TrlrBrkngGainSetIO 1;
BA_REL_ "GenSigSuprvResp" BU_SG_REL_ VCU_LE SG_ 2149990400 TrlrBrkngGainSetIO 1;
BA_REL_ "GenSigVDAFailComment" BU_SG_REL_ IPC_LE SG_ 2149990400 TrlrBrkngGainSetIO "TrlrBrkngVDA";
BA_REL_ "GenSigVDAFailResp" BU_SG_REL_ IPC_LE SG_ 2149990400 TrlrBrkngGainSetIO 1;
BA_REL_ "GenSigSuprvResp" BU_SG_REL_ IPC_LE SG_ 2149990400 TrlrBrkngGainSetIO 1;
BA_REL_ "GenSigVDAFailComment" BU_SG_REL_ VCU_LE SG_ 2149990400 TrlrBrkngGainSet "TrlrBrkngVDA";
BA_REL_ "GenSigVDAFailResp" BU_SG_REL_ VCU_LE SG_ 2149990400 TrlrBrkngGainSet 1;
BA_REL_ "GenSigSuprvResp" BU_SG_REL_ VCU_LE SG_ 2149990400 TrlrBrkngGainSet 1;
BA_REL_ "GenSigVDAFailComment" BU_SG_REL_ IPC_LE SG_ 2149990400 TrlrBrkngGainSet "TrlrBrkngVDA";
BA_REL_ "GenSigVDAFailResp" BU_SG_REL_ IPC_LE SG_ 2149990400 TrlrBrkngGainSet 1;
BA_REL_ "GenSigSuprvResp" BU_SG_REL_ IPC_LE SG_ 2149990400 TrlrBrkngGainSet 1;
BA_REL_ "GenSigVDAFailComment" BU_SG_REL_ VCU_LE SG_ 2149990400 SrvTrlrBrkngSysIO "TrlrBrkngVDA";
BA_REL_ "GenSigVDAFailResp" BU_SG_REL_ VCU_LE SG_ 2149990400 SrvTrlrBrkngSysIO 1;
BA_REL_ "GenSigSuprvResp" BU_SG_REL_ VCU_LE SG_ 2149990400 SrvTrlrBrkngSysIO 1;
BA_REL_ "GenSigVDAFailComment" BU_SG_REL_ IPC_LE SG_ 2149990400 SrvTrlrBrkngSysIO "TrlrBrkngVDA";
BA_REL_ "GenSigVDAFailResp" BU_SG_REL_ IPC_LE SG_ 2149990400 SrvTrlrBrkngSysIO 1;
BA_REL_ "GenSigSuprvResp" BU_SG_REL_ IPC_LE SG_ 2149990400 SrvTrlrBrkngSysIO 1;
BA_REL_ "GenSigVDAFailComment" BU_SG_REL_ VCU_LE SG_ 2149990400 TrlrHtchSwAtv_ITBC "Trailer Braking Virtual Device Availability";
BA_REL_ "GenSigVDAFailResp" BU_SG_REL_ VCU_LE SG_ 2149990400 TrlrHtchSwAtv_ITBC 1;
BA_REL_ "GenSigSuprvResp" BU_SG_REL_ VCU_LE SG_ 2149990400 TrlrHtchSwAtv_ITBC 1;
BA_REL_ "GenSigVDAFailComment" BU_SG_REL_ IPC_LE SG_ 2149990400 TrlrHtchSwAtv_ITBC "Trailer Braking Virtual Device Availability";
BA_REL_ "GenSigVDAFailResp" BU_SG_REL_ IPC_LE SG_ 2149990400 TrlrHtchSwAtv_ITBC 1;
BA_REL_ "GenSigSuprvResp" BU_SG_REL_ IPC_LE SG_ 2149990400 TrlrHtchSwAtv_ITBC 1;
BA_REL_ "GenSigVDAFailComment" BU_SG_REL_ VCU_LE SG_ 2149990400 ABSIO "BrkSysVDA";
BA_REL_ "GenSigVDAFailResp" BU_SG_REL_ VCU_LE SG_ 2149990400 ABSIO 1;
BA_REL_ "GenSigSuprvResp" BU_SG_REL_ VCU_LE SG_ 2149990400 ABSIO 1;
BA_REL_ "GenSigVDAFailComment" BU_SG_REL_ IPC_LE SG_ 2149990400 ABSIO "BrkSysVDA";
BA_REL_ "GenSigVDAFailResp" BU_SG_REL_ IPC_LE SG_ 2149990400 ABSIO 1;
BA_REL_ "GenSigSuprvResp" BU_SG_REL_ IPC_LE SG_ 2149990400 ABSIO 1;
BA_REL_ "GenSigSuprvResp" BU_SG_REL_ CHUD_LE SG_ 2149990400 ACCHdwayStngIO 1;
BA_REL_ "GenSigSuprvResp" BU_SG_REL_ HUD_LE SG_ 2149990400 ACCHdwayStngIO 1;
BA_REL_ "GenSigSuprvResp" BU_SG_REL_ CHUD_LE SG_ 2149990400 ACCDrvrSeltdSpdIO 1;
BA_REL_ "GenSigSuprvResp" BU_SG_REL_ HUD_LE SG_ 2149990400 ACCDrvrSeltdSpdIO 1;
BA_REL_ "GenSigSuprvResp" BU_SG_REL_ CHUD_LE SG_ 2149990400 DrvThrtlOvrdIO 1;
BA_REL_ "GenSigSuprvResp" BU_SG_REL_ HUD_LE SG_ 2149990400 DrvThrtlOvrdIO 1;
BA_REL_ "GenSigSuprvResp" BU_SG_REL_ VCU_LE SG_ 2149842944 VSELatAcc 1;
BA_REL_ "GenSigSuprvResp" BU_SG_REL_ IPC_LE SG_ 2149842944 VSELatAcc 1;
BA_REL_ "GenSigVDAFailComment" BU_SG_REL_ VCU_LE SG_ 2149842944 VehStabEnhmntStat "BrkSysVDA";
BA_REL_ "GenSigVDAFailResp" BU_SG_REL_ VCU_LE SG_ 2149842944 VehStabEnhmntStat 1;
BA_REL_ "GenSigSuprvResp" BU_SG_REL_ VCU_LE SG_ 2149842944 VehStabEnhmntStat 1;
BA_REL_ "GenSigVDAFailComment" BU_SG_REL_ IPC_LE SG_ 2149842944 VehStabEnhmntStat "BrkSysVDA";
BA_REL_ "GenSigVDAFailResp" BU_SG_REL_ IPC_LE SG_ 2149842944 VehStabEnhmntStat 1;
BA_REL_ "GenSigSuprvResp" BU_SG_REL_ IPC_LE SG_ 2149842944 VehStabEnhmntStat 1;
BA_REL_ "GenSigVDAFailComment" BU_SG_REL_ VCU_LE SG_ 2149842944 VehStabEnhmntMd "BrkSysVDA";
BA_REL_ "GenSigVDAFailResp" BU_SG_REL_ VCU_LE SG_ 2149842944 VehStabEnhmntMd 1;
BA_REL_ "GenSigSuprvResp" BU_SG_REL_ VCU_LE SG_ 2149842944 VehStabEnhmntMd 1;
BA_REL_ "GenSigVDAFailComment" BU_SG_REL_ IPC_LE SG_ 2149842944 VehStabEnhmntMd "BrkSysVDA";
BA_REL_ "GenSigVDAFailResp" BU_SG_REL_ IPC_LE SG_ 2149842944 VehStabEnhmntMd 1;
BA_REL_ "GenSigSuprvResp" BU_SG_REL_ IPC_LE SG_ 2149842944 VehStabEnhmntMd 1;
BA_REL_ "GenSigVDAFailComment" BU_SG_REL_ VCU_LE SG_ 2149842944 TCSysOpStat "BrkSysVDA";
BA_REL_ "GenSigVDAFailResp" BU_SG_REL_ VCU_LE SG_ 2149842944 TCSysOpStat 1;
BA_REL_ "GenSigSuprvResp" BU_SG_REL_ VCU_LE SG_ 2149842944 TCSysOpStat 1;
BA_REL_ "GenSigVDAFailComment" BU_SG_REL_ IPC_LE SG_ 2149842944 TCSysOpStat "BrkSysVDA";
BA_REL_ "GenSigVDAFailResp" BU_SG_REL_ IPC_LE SG_ 2149842944 TCSysOpStat 1;
BA_REL_ "GenSigSuprvResp" BU_SG_REL_ IPC_LE SG_ 2149842944 TCSysOpStat 1;
BA_REL_ "GenSigVDAFailComment" BU_SG_REL_ VCU_LE SG_ 2149842944 TCSysOpMd "BrkSysVDA";
BA_REL_ "GenSigVDAFailResp" BU_SG_REL_ VCU_LE SG_ 2149842944 TCSysOpMd 1;
BA_REL_ "GenSigSuprvResp" BU_SG_REL_ VCU_LE SG_ 2149842944 TCSysOpMd 1;
BA_REL_ "GenSigVDAFailComment" BU_SG_REL_ IPC_LE SG_ 2149842944 TCSysOpMd "BrkSysVDA";
BA_REL_ "GenSigVDAFailResp" BU_SG_REL_ IPC_LE SG_ 2149842944 TCSysOpMd 1;
BA_REL_ "GenSigSuprvResp" BU_SG_REL_ IPC_LE SG_ 2149842944 TCSysOpMd 1;
BA_REL_ "GenSigSuprvResp" BU_SG_REL_ VCU_LE SG_ 2149842944 StrWhAng 1;
BA_REL_ "GenSigSuprvResp" BU_SG_REL_ VCU_LE SG_ 2149842944 StrWhAng 1;
BA_REL_ "GenSigSuprvResp" BU_SG_REL_ CSM_LE SG_ 2149842944 StrWhAng 1;
BA_REL_ "GenSigSuprvResp" BU_SG_REL_ RadioHead_LE SG_ 2149842944 StrWhAng 1;
BA_REL_ "GenSigSuprvResp" BU_SG_REL_ RadioHead_LE SG_ 2149842944 StrWhAng 1;
BA_REL_ "GenSigSuprvResp" BU_SG_REL_ RadioHead_LE SG_ 2149842944 IMUProtLonAcc 1;
BA_REL_ "GenSigSuprvResp" BU_SG_REL_ VCU_LE SG_ 2149842944 IMUProtLonAcc 1;
BA_REL_ "GenSigSuprvResp" BU_SG_REL_ VCU_LE SG_ 2149842944 IMUProtLonAcc 1;
BA_REL_ "GenSigSuprvResp" BU_SG_REL_ IPC_LE SG_ 2149842944 IMUProtLonAcc 1;
VAL_ 2158960640 ODIIC_ODIInd9 1 "true" 0 "false" ;
VAL_ 2158960640 ODIIC_ODIInd8 1 "true" 0 "false" ;
VAL_ 2158960640 ODIIC_ODIInd7 1 "true" 0 "false" ;
VAL_ 2158960640 ODIIC_ODIInd6 1 "true" 0 "false" ;
VAL_ 2158960640 ODIIC_ODIInd56 1 "true" 0 "false" ;
VAL_ 2158960640 ODIIC_ODIInd55 1 "true" 0 "false" ;
VAL_ 2158960640 ODIIC_ODIInd54 1 "true" 0 "false" ;
VAL_ 2158960640 ODIIC_ODIInd53 1 "true" 0 "false" ;
VAL_ 2158960640 ODIIC_ODIInd52 1 "true" 0 "false" ;
VAL_ 2158960640 ODIIC_ODIInd51 1 "true" 0 "false" ;
VAL_ 2158960640 ODIIC_ODIInd50 1 "true" 0 "false" ;
VAL_ 2158960640 ODIIC_ODIInd5 1 "true" 0 "false" ;
VAL_ 2158960640 ODIIC_ODIInd49 1 "true" 0 "false" ;
VAL_ 2158960640 ODIIC_ODIInd48 1 "true" 0 "false" ;
VAL_ 2158960640 ODIIC_ODIInd47 1 "true" 0 "false" ;
VAL_ 2158960640 ODIIC_ODIInd46 1 "true" 0 "false" ;
VAL_ 2158960640 ODIIC_ODIInd45 1 "true" 0 "false" ;
VAL_ 2158960640 ODIIC_ODIInd44 1 "true" 0 "false" ;
VAL_ 2158960640 ODIIC_ODIInd43 1 "true" 0 "false" ;
VAL_ 2158960640 ODIIC_ODIInd42 1 "true" 0 "false" ;
VAL_ 2158960640 ODIIC_ODIInd41 1 "true" 0 "false" ;
VAL_ 2158960640 ODIIC_ODIInd40 1 "true" 0 "false" ;
VAL_ 2158960640 ODIIC_ODIInd4 1 "true" 0 "false" ;
VAL_ 2158960640 ODIIC_ODIInd39 1 "true" 0 "false" ;
VAL_ 2158960640 ODIIC_ODIInd38 1 "true" 0 "false" ;
VAL_ 2158960640 ODIIC_ODIInd37 1 "true" 0 "false" ;
VAL_ 2158960640 ODIIC_ODIInd36 1 "true" 0 "false" ;
VAL_ 2158960640 ODIIC_ODIInd35 1 "true" 0 "false" ;
VAL_ 2158960640 ODIIC_ODIInd34 1 "true" 0 "false" ;
VAL_ 2158960640 ODIIC_ODIInd33 1 "true" 0 "false" ;
VAL_ 2158960640 ODIIC_ODIInd32 1 "true" 0 "false" ;
VAL_ 2158960640 ODIIC_ODIInd31 1 "true" 0 "false" ;
VAL_ 2158960640 ODIIC_ODIInd30 1 "true" 0 "false" ;
VAL_ 2158960640 ODIIC_ODIInd3 1 "true" 0 "false" ;
VAL_ 2158960640 ODIIC_ODIInd29 1 "true" 0 "false" ;
VAL_ 2158960640 ODIIC_ODIInd28 1 "true" 0 "false" ;
VAL_ 2158960640 ODIIC_ODIInd27 1 "true" 0 "false" ;
VAL_ 2158960640 ODIIC_ODIInd26 1 "true" 0 "false" ;
VAL_ 2158960640 ODIIC_ODIInd25 1 "true" 0 "false" ;
VAL_ 2158960640 ODIIC_ODIInd24 1 "true" 0 "false" ;
VAL_ 2158960640 ODIIC_ODIInd23 1 "true" 0 "false" ;
VAL_ 2158960640 ODIIC_ODIInd22 1 "true" 0 "false" ;
VAL_ 2158960640 ODIIC_ODIInd21 1 "true" 0 "false" ;
VAL_ 2158960640 ODIIC_ODIInd20 1 "true" 0 "false" ;
VAL_ 2158960640 ODIIC_ODIInd2 1 "true" 0 "false" ;
VAL_ 2158960640 ODIIC_ODIInd19 1 "true" 0 "false" ;
VAL_ 2158960640 ODIIC_ODIInd18 1 "true" 0 "false" ;
VAL_ 2158960640 ODIIC_ODIInd17 1 "true" 0 "false" ;
VAL_ 2158960640 ODIIC_ODIInd16 1 "true" 0 "false" ;
VAL_ 2158960640 ODIIC_ODIInd15 1 "true" 0 "false" ;
VAL_ 2158960640 ODIIC_ODIInd14 1 "true" 0 "false" ;
VAL_ 2158960640 ODIIC_ODIInd13 1 "true" 0 "false" ;
VAL_ 2158960640 ODIIC_ODIInd12 1 "true" 0 "false" ;
VAL_ 2158960640 ODIIC_ODIInd11 1 "true" 0 "false" ;
VAL_ 2158960640 ODIIC_ODIInd10 1 "true" 0 "false" ;
VAL_ 2158960640 ODIIC_ODIInd1 1 "true" 0 "false" ;
VAL_ 2159026176 ODD_InvldData 1 "true" 0 "false" ;
VAL_ 2159026176 ODD_DataType 21 "Bitmap" 20 "DecimalShort" 19 "HoursOfDay" 18 "Character" 17 "Fuel Consumption Inverted" 16 "Fuel Consumption" 15 "Pressure" 14 "Temperature" 13 "Volume" 12 "DistanceShort" 11 "DistanceLong" 10 "BitmapId" 9 "TextId" 8 "Pictogram" 7 "List " 6 "Date" 5 "Time " 4 "Decimal" 3 "EnumerationValue" 2 "Integer" 1 "String" 0 "Speed" ;
VAL_ 2159042560 ODDI_InvldData 1 "true" 0 "false" ;
VAL_ 2159042560 ODDI_DataType 21 "Bitmap" 20 "DecimalShort" 19 "HoursOfDay" 18 "Character" 17 "Fuel Consumption Inverted" 16 "Fuel Consumption" 15 "Pressure" 14 "Temperature" 13 "Volume" 12 "DistanceShort" 11 "DistanceLong" 10 "BitmapId" 9 "TextId" 8 "Pictogram" 7 "List " 6 "Date" 5 "Time " 4 "Decimal" 3 "EnumerationValue" 2 "Integer" 1 "String" 0 "Speed" ;
VAL_ 2158927872 ODDC_InvldData 1 "true" 0 "false" ;
VAL_ 2158927872 ODDC_DataType 21 "Bitmap" 20 "DecimalShort" 19 "HoursOfDay" 18 "Character" 17 "Fuel Consumption Inverted" 16 "Fuel Consumption" 15 "Pressure" 14 "Temperature" 13 "Volume" 12 "DistanceShort" 11 "DistanceLong" 10 "BitmapId" 9 "TextId" 8 "Pictogram" 7 "List " 6 "Date" 5 "Time " 4 "Decimal" 3 "EnumerationValue" 2 "Integer" 1 "String" 0 "Speed" ;
VAL_ 2156789760 FrPedDetCsStReq 3 "Alert and Brake" 2 "Alert" 1 "Off" 0 "No Action" ;
VAL_ 2156789760 TimeDispFormat 1 "24 hour mode" 0 "12 hour mode" ;
VAL_ 2156789760 CldrMth 12 "December" 11 "November" 10 "October" 9 "September" 8 "August" 7 "July" 6 "June" 5 "May" 4 "April" 3 "March" 2 "February" 1 "January" 0 "Unknown" ;
VAL_ 2156789760 SurdVwLightgCsSetReq 7 "Unused and Reserved 5" 6 "Unused and Reserved 4" 5 "Unused and Reserved 3" 4 "Unused and Reserved 2" 3 "Unused and Reserved 1" 2 "ON" 1 "OFF" 0 "No Action" ;
VAL_ 2156789760 SmrtHgBmAstCstSetReq 7 "Unused and Reserved 5" 6 "Unused and Reserved 4" 5 "Unused and Reserved 3" 4 "Unused and Reserved 2" 3 "Unused and Reserved 1" 2 "Adaptive High Beam" 1 "Auto High Beam" 0 "No Action" ;
VAL_ 2151956480 ClstrHMIRdy 1 "true" 0 "false" ;
VAL_ 2151956480 ClstrHMIAnmSt 7 "Unused and Reserved 3" 6 "Unused and Reserved 2" 5 "Unused and Reserved 1" 4 "Shutdown Play" 3 "Start Play" 2 "Welcome Play" 1 "Ready" 0 "Uninitialized" ;
VAL_ 2150268928 EmrgncyRspSysTyp 7 "Ununsed and Reserved 1" 6 "Generic" 5 "ERA" 4 "ChevyStar" 3 "eCall" 2 "Onstar" 1 "None" 0 "Unknown" ;
VAL_ 2150268928 EmrgncyRspSysSrvIndOn 1 "true" 0 "false" ;
VAL_ 2150268928 CldrMth_154 12 "December" 11 "November" 10 "October" 9 "September" 8 "August" 7 "July" 6 "June" 5 "May" 4 "April" 3 "March" 2 "February" 1 "January" 0 "Unknown" ;
VAL_ 2150268928 SecV 1 "Invalid" 0 "Valid" ;
VAL_ 2150268928 MinsV 1 "Invalid" 0 "Valid" ;
VAL_ 2150268928 HrsV 1 "Invalid" 0 "Valid" ;
VAL_ 2156175360 NtVsnSysEnbld 1 "true" 0 "false" ;
VAL_ 2156175360 DispMeasSysExt 2 "Imperial" 1 "US" 0 "Metric" ;
VAL_ 2156175360 DispMeasSys 1 "English" 0 "Metric" ;
VAL_ 2154053632 TrlrLtngSeqStat 1 "On" 0 "Off" ;
VAL_ 2154053632 CargoLmpActIO 1 "true" 0 "false" ;
VAL_ 2154053632 DispNtSchmAtv 1 "true" 0 "false" ;
VAL_ 2154053632 IntDimNtPnlAtv 1 "true" 0 "false" ;
VAL_ 2155216896 SpdLmtPstdSpdM 0 "Don't Use Data" 1 "Use Data" ;
VAL_ 2155216896 ISA2CCC_ScndCdChr 0 "Unknown" 1 "A" 2 "B" 3 "C" 4 "D" 5 "E" 6 "F" 7 "G" 8 "H" 9 "I" 10 "J" 11 "K" 12 "L" 13 "M" 14 "N" 15 "O" 16 "P" 17 "Q" 18 "R" 19 "S" 20 "T" 21 "U" 22 "V" 23 "W" 24 "X" 25 "Y" 26 "Z" ;
VAL_ 2155216896 ISA2CCC_FrstCdChr 0 "Unknown" 1 "A" 2 "B" 3 "C" 4 "D" 5 "E" 6 "F" 7 "G" 8 "H" 9 "I" 10 "J" 11 "K" 12 "L" 13 "M" 14 "N" 15 "O" 16 "P" 17 "Q" 18 "R" 19 "S" 20 "T" 21 "U" 22 "V" 23 "W" 24 "X" 25 "Y" 26 "Z" ;
VAL_ 2155216896 CurvAdvInd 3 "Winding Road" 2 "Right Turn" 1 "Left Turn" 0 "No Advisory" ;
VAL_ 2155216896 SpdLmtUnits 1 "km/h" 0 "mph" ;
VAL_ 2155216896 LnCat 3 "Four Or More Lanes" 2 "Two Or Three Lanes" 1 "One lane" 0 "no info available" ;
VAL_ 2155216896 RdSpdCatType 3 "all speed categories 0 - 50 km/h" 2 "all speed categories 51-80 km/h" 1 "all speed categories 81-130 km/h" 0 "all speed categories > 130 km/h" ;
VAL_ 2155216896 FncRdClass 7 "COLLECTOR" 6 "ALLEY" 5 "ARTERIAL" 4 "HIGHWAY" 3 "PED-MALL" 2 "FREEWAY" 1 "SFREEWAY" 0 "LOCAL (Residential Road)" ;
VAL_ 2155216896 SprtLnRd 1 "true" 0 "false" ;
VAL_ 2155216896 CntrldAccRd 1 "true" 0 "false" ;
VAL_ 2155216896 BldUpArDet 1 "true" 0 "false" ;
VAL_ 2155216896 MpDataAvlbl 1 "true" 0 "false" ;
VAL_ 2155216896 DgtlMapPstdSpdLimAsrd 1 "true" 0 "false" ;
VAL_ 2154921984 RFRmtCntFobNm 5 "Remote Control Fob #5" 4 "Remote Control Fob #4" 3 "Remote Control Fob #3" 2 "Remote Control Fob #2" 1 "Remote Control Fob #1" 0 "No Fob" ;
VAL_ 2154921984 RFRmtCntrlFobFnc 31 "Charge Termination" 30 "Pwr Top Control Start Motion Contrl" 29 "Pwr Top Control Stop Motion Control" 28 "Comfort Close 2" 27 "Comfort Open 2" 26 "Connectivity Request" 25 "Comfort Close" 24 "Comfort Open" 23 "Right Sliding Dr Stop Motion Contrl" 22 "Left Sliding Dr Stop Motion Control" 21 "Pwr Rr Closure Start Motion Control" 20 "Pwr Rr Closure Stop Motion Control" 19 "All Door Double Lock" 18 "Pwr Rr Closure Stop While Opening" 17 "Pwr Rr Closure Stop While Closing" 16 "Power Rear Closure Open Control" 15 "Power Rear Closure Close Control" 14 "Locator Alarm Control" 13 "Fob Programmed" 12 "Engine Stop" 11 "Engine Run" 10 "Power Top Control" 9 "Power Window Control" 8 "Fuel Door Control" 7 "Panic Alarm Control" 6 "Right Sliding Door Control" 5 "Left Sliding Door Control" 4 "Rear Closure Control" 3 "All Door Unlock" 2 "Driver Door Unlock" 1 "Lock" 0 "No Activation" ;
VAL_ 2154921984 RFRmtCntFobBatLw 1 "true" 0 "false" ;
VAL_ 2154921984 FobPogLimRchdIndOn 1 "true" 0 "false" ;
VAL_ 2153971712 LftglsRelSwAct 1 "true" 0 "false" ;
VAL_ 2153971712 LftglsAjrSwAct 1 "true" 0 "false" ;
VAL_ 2153971712 DDAjrSwAtvM 0 "Don't Use Data" 1 "Use Data" ;
VAL_ 2153971712 DDAjrSwAtv 1 "true" 0 "false" ;
VAL_ 2152054784 FuelEconMetDispUnts 0 "Kilometers per liter" 1 "Liters per 100 km" ;
VAL_ 2152054784 IntPnlClstrAnmtStat 0 "Animation Not Available" 1 "Animation Available" 2 "Welcome Active" 3 "CRANK Active" 4 "RUN Active" 5 "Good Bye Active" ;
VAL_ 2152054784 AnmStrtReq 0 "No Action" 1 "Welcome" 2 "CRANK" 3 "RUN" 4 "Good Bye" ;
VAL_ 2151505920 PTExPrtclFltManRgnDispPrsnt 1 "true" 0 "false" ;
VAL_ 2151505920 Trp2OdomtrV 1 "Invalid" 0 "Valid" ;
VAL_ 2151505920 Trp1OdomtrV 1 "Invalid" 0 "Valid" ;
VAL_ 2151505920 AutoMdSpdLmtCnfrmd 1 "true" 0 "false" ;
VAL_ 2151505920 ACCSettingType 0 "Manual" 1 "Auto" ;
VAL_ 2151505920 TrlrBrkDsplyAct 1 "true" 0 "false" ;
VAL_ 2151505920 SpdCurvAdvSysEnbld 1 "true" 0 "false" ;
VAL_ 2151505920 PTExPrtclFltManRgnRqd 1 "true" 0 "false" ;
VAL_ 2150424576 ExtHlStrAssCsCrStVal 2 "Standard Hold" 1 "Extended Hold" 0 "No Action" ;
VAL_ 2150424576 ExtHlStrAssCsStAvl 1 "true" 0 "false" ;
VAL_ 2150424576 RrAxlELSDCplLwResV 1 "Invalid" 0 "Valid" ;
VAL_ 2150424576 EngTrqDrRqdExtRngV 1 "Invalid" 0 "Valid" ;
VAL_ 2150424576 EngAirIntBstPrV 1 "Invalid" 0 "Valid" ;
VAL_ 2150424576 TrnsRngInhbtStat 4 "Diagnostic Inhibit Active" 3 "Driveline Not Engaged" 2 "Transmission Range Re-Selection Req" 1 "Transmission Inhibit Active" 0 "No Range Inhibit Active" ;
VAL_ 2150424576 DrvtShftCntrlTrgtGear 10 "Tenth Gear" 9 "Ninth Gear" 8 "Eighth Gear" 7 "Seventh Gear" 6 "Sixth Gear" 5 "Fifth Gear" 4 "Fourth Gear" 3 "Third Gear" 2 "Second Gear" 1 "First Gear" 0 "Not Supported" ;
VAL_ 2150424576 TrnsEngdStateV 1 "Invalid" 0 "Valid" ;
VAL_ 2150424576 ACRfHiSdFldPrsV 1 "Invalid" 0 "Valid" ;
VAL_ 2150424576 ACCompCmnd 1 "On" 0 "Off" ;
VAL_ 2150424576 TrnsEngdState 3 "Operating State Not Reached" 2 "Transmission Engaged in Reverse" 1 "Transmission Engaged in Forward" 0 "Transmission Not Engaged" ;
VAL_ 2150416384 PTWrmgWtToShftIO 1 "true" 0 "false" ;
VAL_ 2150416384 EngTrqActExtRngV 1 "Invalid" 0 "Valid" ;
VAL_ 2150416384 VehTopSpdLmtMdAct 1 "true" 0 "false" ;
VAL_ 2150416384 EngRunAtv 1 "true" 0 "false" ;
VAL_ 2150416384 EngIdlAtv 1 "true" 0 "false" ;
VAL_ 2150416384 EngSpdStat 3 "Invalid" 1 "Degraded Operation" 0 "Normal Operation" ;
VAL_ 2150416384 VaccBoostFailure 1 "true" 0 "false" ;
VAL_ 2150416384 RmVhStrtEngRng 1 "true" 0 "false" ;
VAL_ 2150416384 TrnsVDA 1 "VirtualDeviceAvailable" 0 "VirtualDeviceUnavailable" ;
VAL_ 2150416384 GenFld 1 "true" 0 "false" ;
VAL_ 2150416384 EngSpdLmtnMdAct 1 "true" 0 "false" ;
VAL_ 2150416384 EngNEmsnsRelMalfAct 1 "true" 0 "false" ;
VAL_ 2150416384 EngCstFlCutAct 1 "true" 0 "false" ;
VAL_ 2150416384 EngCylDeactMd 3 "Reactivation In Progress" 2 "Half of Total Cylinders Active" 1 "Deactivation In Progress" 0 "All Cylinders Active" ;
VAL_ 2150416384 EngBstPrsIndV 1 "Invalid" 0 "Valid" ;
VAL_ 2150416384 TransEstGear 9 "Ninth Gear" 15 "Park Gear" 14 "Reverse Gear" 13 "Neutral Gear" 12 "CVT Forward Gear" 11 "Unused and Reserved" 10 "Tenth Gear" 8 "Eighth Gear" 7 "Seventh Gear" 6 "Sixth Gear" 5 "Fifth Gear" 4 "Fourth Gear" 3 "Third Gear" 2 "Second Gear" 1 "First Gear" 0 "Not Supported" ;
VAL_ 2150416384 TransEstGearV 1 "Invalid" 0 "Valid" ;
VAL_ 2150416384 EngVDA 1 "VirtualDeviceAvailable" 0 "VirtualDeviceUnavailable" ;
VAL_ 2150416384 TrnCrpMdAtv 1 "true" 0 "false" ;
VAL_ 2150408192 ElcRngSelDrvAct 1 "true" 0 "false" ;
VAL_ 2150408192 TmpDrvrShftCtlAct 1 "true" 0 "false" ;
VAL_ 2150408192 AdptPsngrSeatStng 7 "Performance Mode 7" 6 "Performance Mode 6" 5 "Performance Mode 5" 4 "Performance Mode 4" 3 "Performance Mode 3" 2 "Performance Mode 2" 1 "Performance Mode 1" 0 "No Action" ;
VAL_ 2150408192 EngRunng 1 "true" 0 "false" ;
VAL_ 2150408192 Eng12vStrtrMtrCmmdOn 1 "true" 0 "false" ;
VAL_ 2150408192 AccPdlOvrrdAtv 1 "true" 0 "false" ;
VAL_ 2150408192 TopTrvlCltchSwActV 1 "Invalid" 0 "Valid" ;
VAL_ 2150408192 TopTrvlCltchSwAct 1 "true" 0 "false" ;
VAL_ 2150408192 CltStartSwAtvV 1 "Invalid" 0 "Valid" ;
VAL_ 2150408192 CltStartSwAtv 1 "true" 0 "false" ;
VAL_ 2150408192 CrsCntEnbld 1 "true" 0 "false" ;
VAL_ 2150408192 AccActPosV 1 "Invalid" 0 "Valid" ;
VAL_ 2150408192 TrnsShftLvrPosV 1 "Invalid" 0 "Valid" ;
VAL_ 2150408192 TrnsSftMdStat 3 "Automatic Grade Braking Mode" 2 "Lift-Foot Cornering Mode" 1 "Performance Mode" 0 "No Override Mode" ;
VAL_ 2150408192 AutoTransComndGear 9 "Ninth Gear" 15 "Park Gear" 14 "Reverse Gear" 13 "Neutral Gear" 12 "CVT Forward Gear" 11 "Unused and Reserved" 10 "Tenth Gear" 8 "Eighth Gear" 7 "Seventh Gear" 6 "Sixth Gear" 5 "Fifth Gear" 4 "Fourth Gear" 3 "Third Gear" 2 "Second Gear" 1 "First Gear" 0 "Not Supported" ;
VAL_ 2150408192 TrnShftPtrnActStat 6 "PT Protection Pattern Active" 5 "PT Non-Protection Pattern Active" 4 "Shift Pattern 4 Active" 3 "Shift Pattern 3 Active" 2 "Shift Pattern 2 Active" 1 "Shift Pattern 1 Active" 0 "Default Shift Pattern Active" ;
VAL_ 2150408192 TrnsShftLvrPos 13 "Forward Range J" 12 "Froward Range I" 15 "Lever Position Unknown" 11 "Forward Range H" 10 "Forward Range G" 9 "Forward Range F" 8 "Forward Range E" 7 "Forward Range D" 6 "Forward Range C" 5 "Forward Range B" 4 "Forward Range A" 3 "Neutral Range" 2 "Reverse Range" 1 "Park Range" 0 "Between Ranges" ;
VAL_ 2150408192 ThrPosV 1 "Invalid" 0 "Valid" ;
VAL_ 2150408192 TransTUDMdStat 2 "Electronic Range Select Active" 1 "Driver Shift Control Active" 0 "No Activation" ;
VAL_ 2149990400 ElcTransRngRq 7 "Unused and Reserved" 6 "Manual Range" 5 "Low Range" 4 "Drive" 3 "Neutral" 2 "Reverse" 1 "Park" 0 "No Request" ;
VAL_ 2149990400 TrlrBrkngVDA 1 "VirtualDeviceAvailable" 0 "VirtualDeviceUnavailable" ;
VAL_ 2149990400 SecAxlOperMod 3 "Active All Wheel Drive (High)" 2 "4 Wheel Drive Low Locked" 1 "4 Wheel Drive High Locked" 0 "2 Wheel Drive High" 15 "Neutral" 14 "Unknown" 7 "2 Wheel Drive Low" 6 "Active All Wheel Drive (Low)" 5 "4 Wheel Drive Low Open" 4 "4 Wheel Drive High Open" ;
VAL_ 2149990400 MotStBltUnblIO 1 "true" 0 "false" ;
VAL_ 2149990400 MotStBltFldIO 1 "true" 0 "false" ;
VAL_ 2149990400 TransNtrlCntrlMdStat 3 "Exiting Neutral Control" 2 "Neutral Control Active" 1 "Entering Neutral Control" 0 "Neutral Control Not Active" ;
VAL_ 2149990400 TrlrWiringFltIO 1 "true" 0 "false" ;
VAL_ 2149990400 TrlrCnctdIO 1 "true" 0 "false" ;
VAL_ 2149990400 TrlrBrkngGainSetIO 1 "true" 0 "false" ;
VAL_ 2149990400 SrvTrlrBrkngSysIO 1 "true" 0 "false" ;
VAL_ 2149990400 ChkTrlrIO 1 "true" 0 "false" ;
VAL_ 2149990400 ScndryAxleVDA 1 "VirtualDeviceAvailable" 0 "VirtualDeviceUnavailable" ;
VAL_ 2149990400 TrlrHtchSwAtv_ITBC 1 "true" 0 "false" ;
VAL_ 2149990400 AdvHlmpsVDA 1 "VirtualDeviceAvailable" 0 "VirtualDeviceUnavailable" ;
VAL_ 2149990400 ABSIO 1 "true" 0 "false" ;
VAL_ 2149990400 ACCHdwayStngIO 1 "true" 0 "false" ;
VAL_ 2149990400 StpOnBrkToRelPBIndOn 1 "true" 0 "false" ;
VAL_ 2149990400 SADmpVDA 1 "VirtualDeviceAvailable" 0 "VirtualDeviceUnavailable" ;
VAL_ 2149990400 ACCDrvrSeltdSpdIO 1 "true" 0 "false" ;
VAL_ 2149990400 TreInfMonSysRstPrfmd 1 "true" 0 "false" ;
VAL_ 2149990400 DrvThrtlOvrdIO 1 "true" 0 "false" ;
VAL_ 2149842944 AdptDrvrSeatStng 7 "Performance Mode 7" 6 "Performance Mode 6" 5 "Performance Mode 5" 4 "Performance Mode 4" 3 "Performance Mode 3" 2 "Performance Mode 2" 1 "Performance Mode 1" 0 "No Action" ;
VAL_ 2149842944 VSELatAccV 1 "Invalid" 0 "Valid" ;
VAL_ 2149842944 StrWhAngV 1 "Invalid" 0 "Valid" ;
VAL_ 2149842944 TCSysAtv 1 "true" 0 "false" ;
VAL_ 2149842944 BrkSysAutBrkFld 1 "true" 0 "false" ;
VAL_ 2149842944 StrWhlAngSenCalStat 2 "Calibrated" 1 "Estimated" 0 "Unknown" ;
VAL_ 2149842944 VehStabEnhmntStat 4 "Not Ready" 3 "Warming Up" 2 "Fault" 1 "Active" 0 "Inactive" ;
VAL_ 2149842944 VehStabEnhmntMd 2 "Competitive" 1 "Normal" 0 "Off" ;
VAL_ 2149842944 VSEAct 1 "true" 0 "false" ;
VAL_ 2149842944 TCSysOpStat 2 "Fault" 1 "Active" 0 "Inactive" ;
VAL_ 2149842944 TCSysOpMd 2 "Off Road" 1 "Normal" 0 "Off" ;
VAL_ 2149842944 StWhAnVDA 1 "VirtualDeviceAvailable" 0 "VirtualDeviceUnavailable" ;
VAL_ 2149842944 IMUProtLonAccV 1 "Invalid" 0 "Valid" ;
SIG_GROUP_ 2158960640 ODIInd_CntrStck 1 : ODIIC_FUCID ODIIC_ODIInd9 ODIIC_ODIInd8 ODIIC_ODIInd7 ODIIC_ODIInd6 ODIIC_ODIInd56 ODIIC_ODIInd55 ODIIC_ODIInd54 ODIIC_ODIInd53 ODIIC_ODIInd52 ODIIC_ODIInd51 ODIIC_ODIInd50 ODIIC_ODIInd5 ODIIC_ODIInd49 ODIIC_ODIInd48 ODIIC_ODIInd47 ODIIC_ODIInd46 ODIIC_ODIInd45 ODIIC_ODIInd44 ODIIC_ODIInd43 ODIIC_ODIInd42 ODIIC_ODIInd41 ODIIC_ODIInd40 ODIIC_ODIInd4 ODIIC_ODIInd39 ODIIC_ODIInd38 ODIIC_ODIInd37 ODIIC_ODIInd36 ODIIC_ODIInd35 ODIIC_ODIInd34 ODIIC_ODIInd33 ODIIC_ODIInd32 ODIIC_ODIInd31 ODIIC_ODIInd30 ODIIC_ODIInd3 ODIIC_ODIInd29 ODIIC_ODIInd28 ODIIC_ODIInd27 ODIIC_ODIInd26 ODIIC_ODIInd25 ODIIC_ODIInd24 ODIIC_ODIInd23 ODIIC_ODIInd22 ODIIC_ODIInd21 ODIIC_ODIInd20 ODIIC_ODIInd2 ODIIC_ODIInd19 ODIIC_ODIInd18 ODIIC_ODIInd17 ODIIC_ODIInd16 ODIIC_ODIInd15 ODIIC_ODIInd14 ODIIC_ODIInd13 ODIIC_ODIInd12 ODIIC_ODIInd11 ODIIC_ODIInd10 ODIIC_ODIInd1;
SIG_GROUP_ 2158755840 ODIEvntPkt 1 : ODIE_MultiFrRetCh ODIE_FUCID ODIE_EvID;
SIG_GROUP_ 2159058944 ODIEvntPkt_IPC 1 : ODIEI_MultiFrRetCh ODIEI_FUCID ODIEI_EvID;
SIG_GROUP_ 2158977024 ODIEvntPkt_CntrStck 1 : ODIEC_MultiFrRetCh ODIEC_FUCID ODIEC_EvID;
SIG_GROUP_ 2158936064 ODIEnmDynData 1 : ODIEDD_Data18Value ODIEDD_Data17Value ODIEDD_Data16Value ODIEDD_Data15Value ODIEDD_Data14Value ODIEDD_Data13Value ODIEDD_Data12Value ODIEDD_Data11Value ODIEDD_Data10Value ODIEDD_Data9Value ODIEDD_Data8Value ODIEDD_Data7Value ODIEDD_Data6Value ODIEDD_Data5Value ODIEDD_Data4Value ODIEDD_Data3Value ODIEDD_Data2Value ODIEDD_Data1Value ODIEDD_FUCID;
SIG_GROUP_ 2159001600 ODIEnmDynData_IPC 1 : ODIEDDIPC_FUCID ODIEDDIPC_Data18Value ODIEDDIPC_Data17Value ODIEDDIPC_Data16Value ODIEDDIPC_Data15Value ODIEDDIPC_Data14Value ODIEDDIPC_Data13Value ODIEDDIPC_Data12Value ODIEDDIPC_Data11Value ODIEDDIPC_Data10Value ODIEDDIPC_Data9Value ODIEDDIPC_Data8Value ODIEDDIPC_Data7Value ODIEDDIPC_Data6Value ODIEDDIPC_Data5Value ODIEDDIPC_Data4Value ODIEDDIPC_Data3Value ODIEDDIPC_Data2Value ODIEDDIPC_Data1Value;
SIG_GROUP_ 2158993408 ODIEnmDynData_CenterStack 1 : ODIEDDCS_FUCID ODIEDDCS_Data9Value ODIEDDCS_Data8Value ODIEDDCS_Data7Value ODIEDDCS_Data6Value ODIEDDCS_Data5Value ODIEDDCS_Data4Value ODIEDDCS_Data3Value ODIEDDCS_Data2Value ODIEDDCS_Data18Value ODIEDDCS_Data17Value ODIEDDCS_Data16Value ODIEDDCS_Data15Value ODIEDDCS_Data14Value ODIEDDCS_Data13Value ODIEDDCS_Data12Value ODIEDDCS_Data11Value ODIEDDCS_Data10Value ODIEDDCS_Data1Value;
SIG_GROUP_ 2159026176 ODIDynData 1 : ODD_InvldData ODD_FUCID ODD_DataVal ODD_DataType ODD_DataId;
SIG_GROUP_ 2159042560 ODIDynData_IPC 1 : ODDI_DataVal ODDI_DataId ODDI_FUCID ODDI_InvldData ODDI_DataType;
SIG_GROUP_ 2158927872 ODIDynData_CntrStck 1 : ODDC_InvldData ODDC_FUCID ODDC_DataVal ODDC_DataType ODDC_DataId;
SIG_GROUP_ 2156789760 TmofDay 1 : TOD_SecofMin TOD_MinofHr TOD_HrofDay;
SIG_GROUP_ 2155216896 IntlStdAlph2CddCntryCd 1 : ISA2CCC_ScndCdChr ISA2CCC_FrstCdChr;
SIG_GROUP_ 2154921984 RFAFnc 1 : RFRmtCntFobNm RFRmtCntrlFobFnc RFRmtCntFobBatLw;
